VERSION "HNNBNNNYNNNNNNNNNNNNNNNNNNNNNNNNNNNNNNNNNN/4/%%%/4/'%**4NNN///"

NS_ :

BS_:

BU_: AAG BCM1 BCM2 ELV Gateway HDSG IEZS MFG MSBBR SAD SAD2 Schwerpanzer_Zusatz SitzMem_BFS SitzMem_FS SitzMem_HBFS SitzMem_HFS SitzMem_SR3 SpoilerSG TSG_BFS TSG_FS VSG VTS DK_Dummy

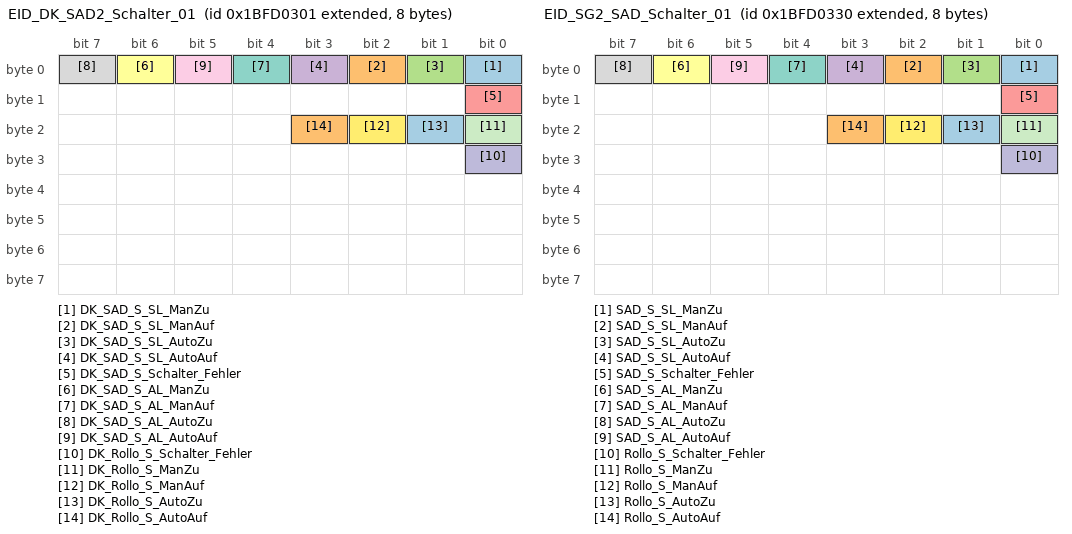
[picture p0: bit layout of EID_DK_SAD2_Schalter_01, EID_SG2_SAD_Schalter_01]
BO_ 2617049857 EID_DK_SAD2_Schalter_01: 8 DK_Dummy
 SG_ DK_SAD_S_SL_ManZu : 0|1@1+ (1,0) [0|1] ""  SAD2
 SG_ DK_SAD_S_SL_ManAuf : 2|1@1+ (1,0) [0|1] ""  SAD2
 SG_ DK_SAD_S_SL_AutoZu : 1|1@1+ (1,0) [0|1] ""  SAD2
 SG_ DK_SAD_S_SL_AutoAuf : 3|1@1+ (1,0) [0|1] ""  SAD2
 SG_ DK_SAD_S_Schalter_Fehler : 8|1@1+ (1,0) [0|1] ""  SAD2
 SG_ DK_SAD_S_AL_ManZu : 6|1@1+ (1,0) [0|1] ""  SAD2
 SG_ DK_SAD_S_AL_ManAuf : 4|1@1+ (1,0) [0|1] ""  SAD2
 SG_ DK_SAD_S_AL_AutoZu : 7|1@1+ (1,0) [0|1] ""  SAD2
 SG_ DK_SAD_S_AL_AutoAuf : 5|1@1+ (1,0) [0|1] ""  SAD2
 SG_ DK_Rollo_S_Schalter_Fehler : 24|1@1+ (1,0) [0|1] ""  SAD2
 SG_ DK_Rollo_S_ManZu : 16|1@1+ (1,0) [0|1] ""  SAD2
 SG_ DK_Rollo_S_ManAuf : 18|1@1+ (1,0) [0|1] ""  SAD2
 SG_ DK_Rollo_S_AutoZu : 17|1@1+ (1,0) [0|1] ""  SAD2
 SG_ DK_Rollo_S_AutoAuf : 19|1@1+ (1,0) [0|1] ""  SAD2

BO_ 2617049904 EID_SG2_SAD_Schalter_01: 8 SAD2
 SG_ SAD_S_SL_ManZu : 0|1@1+ (1,0) [0|1] "" Vector__XXX
 SG_ SAD_S_SL_ManAuf : 2|1@1+ (1,0) [0|1] "" Vector__XXX
 SG_ SAD_S_SL_AutoZu : 1|1@1+ (1,0) [0|1] "" Vector__XXX
 SG_ SAD_S_SL_AutoAuf : 3|1@1+ (1,0) [0|1] "" Vector__XXX
 SG_ SAD_S_Schalter_Fehler : 8|1@1+ (1,0) [0|1] "" Vector__XXX
 SG_ SAD_S_AL_ManZu : 6|1@1+ (1,0) [0|1] "" Vector__XXX
 SG_ SAD_S_AL_ManAuf : 4|1@1+ (1,0) [0|1] "" Vector__XXX
 SG_ SAD_S_AL_AutoZu : 7|1@1+ (1,0) [0|1] "" Vector__XXX
 SG_ SAD_S_AL_AutoAuf : 5|1@1+ (1,0) [0|1] "" Vector__XXX
 SG_ Rollo_S_Schalter_Fehler : 24|1@1+ (1,0) [0|1] "" Vector__XXX
 SG_ Rollo_S_ManZu : 16|1@1+ (1,0) [0|1] "" Vector__XXX
 SG_ Rollo_S_ManAuf : 18|1@1+ (1,0) [0|1] "" Vector__XXX
 SG_ Rollo_S_AutoZu : 17|1@1+ (1,0) [0|1] "" Vector__XXX
 SG_ Rollo_S_AutoAuf : 19|1@1+ (1,0) [0|1] "" Vector__XXX

BO_ 2617049906 EID_SG2_SAD_02: 8 SAD2
 SG_ Event_Logging : 0|64@1+ (1,0) [0|1.84467440737096E+019] "" Vector__XXX

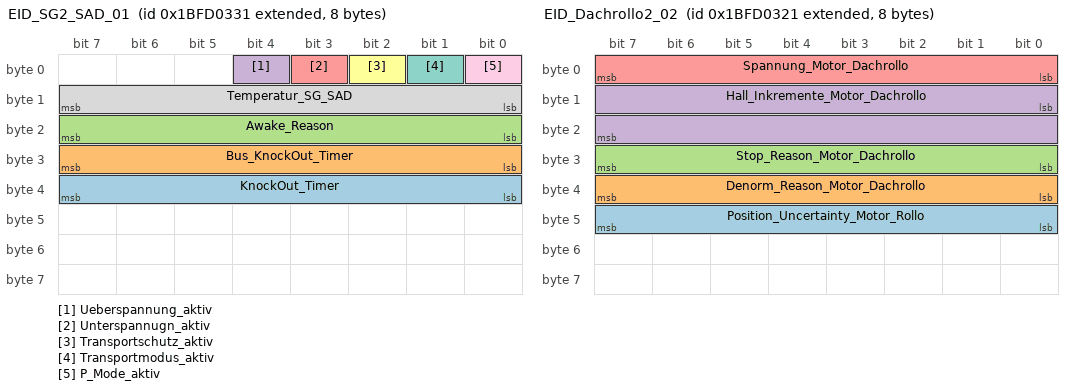
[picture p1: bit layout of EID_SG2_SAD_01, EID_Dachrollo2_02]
BO_ 2617049905 EID_SG2_SAD_01: 8 SAD2
 SG_ KnockOut_Timer : 32|8@1+ (1,0) [0|255] "Unit_Minut" Vector__XXX
 SG_ Bus_KnockOut_Timer : 24|8@1+ (1,0) [0|255] "Unit_Minut" Vector__XXX
 SG_ Awake_Reason : 16|8@1+ (1,0) [0|255] "" Vector__XXX
 SG_ Ueberspannung_aktiv : 4|1@1+ (1,0) [0|1] "" Vector__XXX
 SG_ Unterspannugn_aktiv : 3|1@1+ (1,0) [0|1] "" Vector__XXX
 SG_ Transportschutz_aktiv : 2|1@1+ (1,0) [0|1] "" Vector__XXX
 SG_ Transportmodus_aktiv : 1|1@1+ (1,0) [0|1] "" Vector__XXX
 SG_ Temperatur_SG_SAD : 8|8@1+ (1,0) [0|255] "Unit_DegreCelsi" Vector__XXX
 SG_ P_Mode_aktiv : 0|1@1+ (1,0) [0|1] "" Vector__XXX

BO_ 2617049889 EID_Dachrollo2_02: 8 SAD2
 SG_ Position_Uncertainty_Motor_Rollo : 40|8@1+ (1,0) [0|255] "" Vector__XXX
 SG_ Denorm_Reason_Motor_Dachrollo : 32|8@1+ (1,0) [0|255] "" Vector__XXX
 SG_ Stop_Reason_Motor_Dachrollo : 24|8@1+ (1,0) [0|255] "" Vector__XXX
 SG_ Hall_Inkremente_Motor_Dachrollo : 8|16@1+ (1,0) [0|65535] "" Vector__XXX
 SG_ Spannung_Motor_Dachrollo : 0|8@1+ (0.1,0) [0|25.5] "Unit_V" Vector__XXX

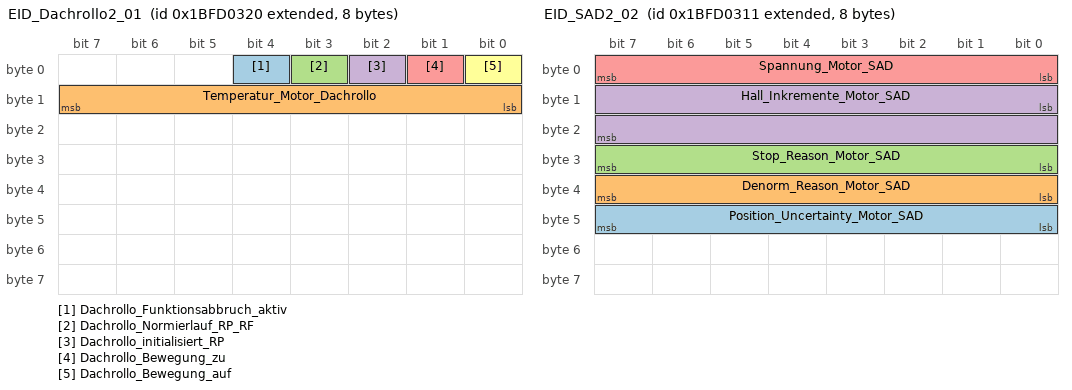
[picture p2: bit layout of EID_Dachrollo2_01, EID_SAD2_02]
BO_ 2617049888 EID_Dachrollo2_01: 8 SAD2
 SG_ Dachrollo_Funktionsabbruch_aktiv : 4|1@1+ (1,0) [0|1] "" Vector__XXX
 SG_ Temperatur_Motor_Dachrollo : 8|8@1+ (1,0) [0|255] "Unit_DegreCelsi" Vector__XXX
 SG_ Dachrollo_Normierlauf_RP_RF : 3|1@1+ (1,0) [0|1] "" Vector__XXX
 SG_ Dachrollo_initialisiert_RP : 2|1@1+ (1,0) [0|1] "" Vector__XXX
 SG_ Dachrollo_Bewegung_zu : 1|1@1+ (1,0) [0|1] "" Vector__XXX
 SG_ Dachrollo_Bewegung_auf : 0|1@1+ (1,0) [0|1] "" Vector__XXX

BO_ 2617049873 EID_SAD2_02: 8 SAD2
 SG_ Position_Uncertainty_Motor_SAD : 40|8@1+ (1,0) [0|255] "" Vector__XXX
 SG_ Denorm_Reason_Motor_SAD : 32|8@1+ (1,0) [0|255] "" Vector__XXX
 SG_ Stop_Reason_Motor_SAD : 24|8@1+ (1,0) [0|255] "" Vector__XXX
 SG_ Hall_Inkremente_Motor_SAD : 8|16@1+ (1,0) [0|65535] "" Vector__XXX
 SG_ Spannung_Motor_SAD : 0|8@1+ (0.1,0) [0|25.5] "Unit_V" Vector__XXX

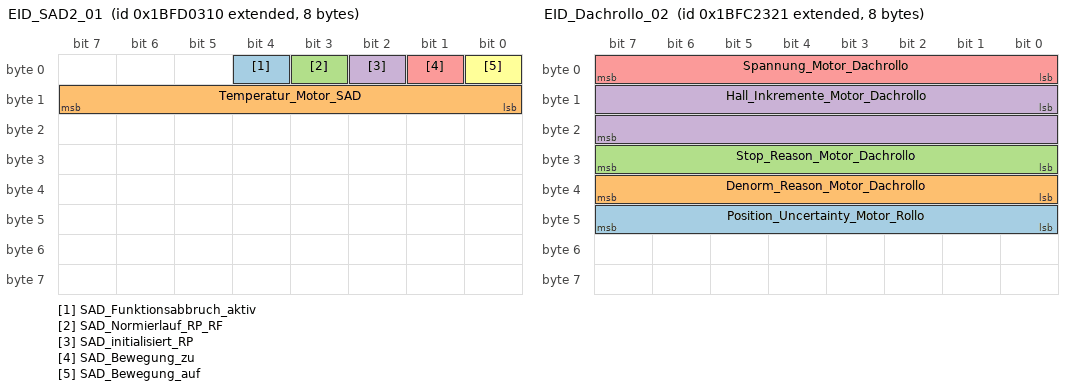
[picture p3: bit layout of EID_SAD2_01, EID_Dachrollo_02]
BO_ 2617049872 EID_SAD2_01: 8 SAD2
 SG_ SAD_Funktionsabbruch_aktiv : 4|1@1+ (1,0) [0|1] "" Vector__XXX
 SG_ Temperatur_Motor_SAD : 8|8@1+ (1,0) [0|255] "Unit_DegreCelsi" Vector__XXX
 SG_ SAD_Normierlauf_RP_RF : 3|1@1+ (1,0) [0|1] "" Vector__XXX
 SG_ SAD_initialisiert_RP : 2|1@1+ (1,0) [0|1] "" Vector__XXX
 SG_ SAD_Bewegung_zu : 1|1@1+ (1,0) [0|1] "" Vector__XXX
 SG_ SAD_Bewegung_auf : 0|1@1+ (1,0) [0|1] "" Vector__XXX

BO_ 2616992562 EID_SG_SAD_02: 8 SAD
 SG_ Event_Logging : 0|64@1+ (1,0) [0|1.84467440737096E+019] "" Vector__XXX

BO_ 2616992545 EID_Dachrollo_02: 8 SAD
 SG_ Position_Uncertainty_Motor_Rollo : 40|8@1+ (1,0) [0|255] "" Vector__XXX
 SG_ Denorm_Reason_Motor_Dachrollo : 32|8@1+ (1,0) [0|255] "" Vector__XXX
 SG_ Stop_Reason_Motor_Dachrollo : 24|8@1+ (1,0) [0|255] "" Vector__XXX
 SG_ Hall_Inkremente_Motor_Dachrollo : 8|16@1+ (1,0) [0|65535] "" Vector__XXX
 SG_ Spannung_Motor_Dachrollo : 0|8@1+ (0.1,0) [0|25.5] "Unit_V" Vector__XXX

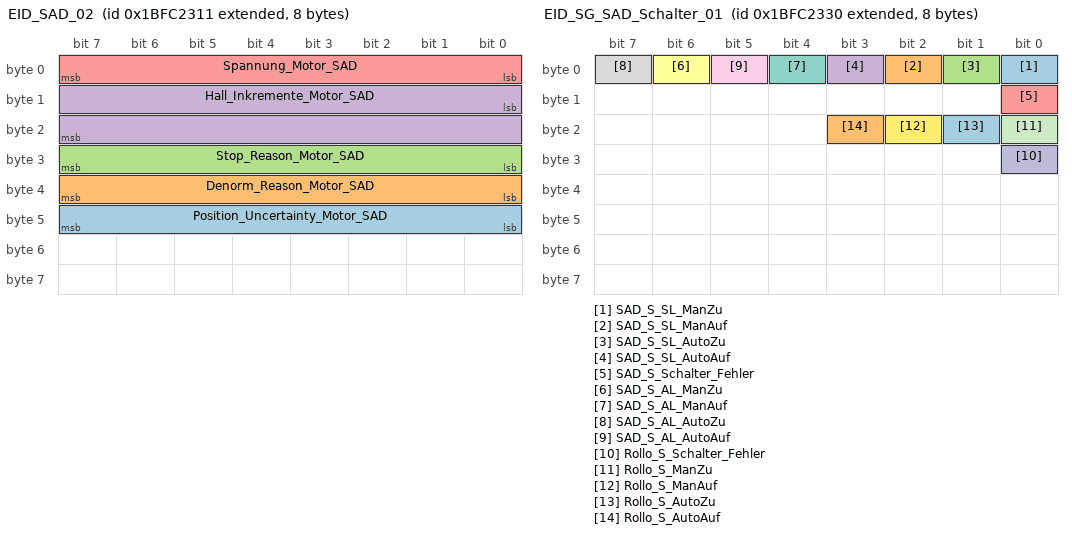
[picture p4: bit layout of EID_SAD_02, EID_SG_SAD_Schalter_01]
BO_ 2616992529 EID_SAD_02: 8 SAD
 SG_ Position_Uncertainty_Motor_SAD : 40|8@1+ (1,0) [0|255] "" Vector__XXX
 SG_ Denorm_Reason_Motor_SAD : 32|8@1+ (1,0) [0|255] "" Vector__XXX
 SG_ Stop_Reason_Motor_SAD : 24|8@1+ (1,0) [0|255] "" Vector__XXX
 SG_ Hall_Inkremente_Motor_SAD : 8|16@1+ (1,0) [0|65535] "" Vector__XXX
 SG_ Spannung_Motor_SAD : 0|8@1+ (0.1,0) [0|25.5] "Unit_V" Vector__XXX

BO_ 2616992560 EID_SG_SAD_Schalter_01: 8 SAD
 SG_ SAD_S_SL_ManZu : 0|1@1+ (1,0) [0|1] "" Vector__XXX
 SG_ SAD_S_SL_ManAuf : 2|1@1+ (1,0) [0|1] "" Vector__XXX
 SG_ SAD_S_SL_AutoZu : 1|1@1+ (1,0) [0|1] "" Vector__XXX
 SG_ SAD_S_SL_AutoAuf : 3|1@1+ (1,0) [0|1] "" Vector__XXX
 SG_ SAD_S_Schalter_Fehler : 8|1@1+ (1,0) [0|1] "" Vector__XXX
 SG_ SAD_S_AL_ManZu : 6|1@1+ (1,0) [0|1] "" Vector__XXX
 SG_ SAD_S_AL_ManAuf : 4|1@1+ (1,0) [0|1] "" Vector__XXX
 SG_ SAD_S_AL_AutoZu : 7|1@1+ (1,0) [0|1] "" Vector__XXX
 SG_ SAD_S_AL_AutoAuf : 5|1@1+ (1,0) [0|1] "" Vector__XXX
 SG_ Rollo_S_Schalter_Fehler : 24|1@1+ (1,0) [0|1] "" Vector__XXX
 SG_ Rollo_S_ManZu : 16|1@1+ (1,0) [0|1] "" Vector__XXX
 SG_ Rollo_S_ManAuf : 18|1@1+ (1,0) [0|1] "" Vector__XXX
 SG_ Rollo_S_AutoZu : 17|1@1+ (1,0) [0|1] "" Vector__XXX
 SG_ Rollo_S_AutoAuf : 19|1@1+ (1,0) [0|1] "" Vector__XXX

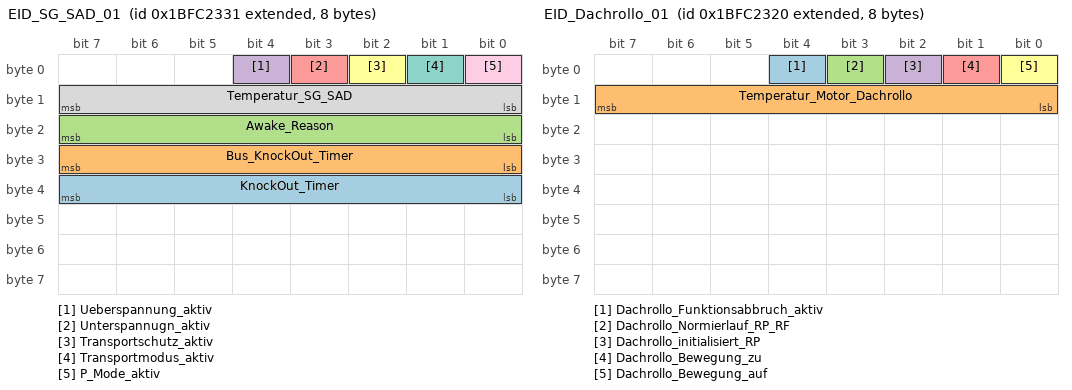
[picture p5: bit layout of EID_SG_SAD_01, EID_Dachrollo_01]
BO_ 2616992561 EID_SG_SAD_01: 8 SAD
 SG_ KnockOut_Timer : 32|8@1+ (1,0) [0|255] "Unit_Minut" Vector__XXX
 SG_ Bus_KnockOut_Timer : 24|8@1+ (1,0) [0|255] "Unit_Minut" Vector__XXX
 SG_ Awake_Reason : 16|8@1+ (1,0) [0|255] "" Vector__XXX
 SG_ Ueberspannung_aktiv : 4|1@1+ (1,0) [0|1] "" Vector__XXX
 SG_ Unterspannugn_aktiv : 3|1@1+ (1,0) [0|1] "" Vector__XXX
 SG_ Transportschutz_aktiv : 2|1@1+ (1,0) [0|1] "" Vector__XXX
 SG_ Transportmodus_aktiv : 1|1@1+ (1,0) [0|1] "" Vector__XXX
 SG_ Temperatur_SG_SAD : 8|8@1+ (1,0) [0|255] "Unit_DegreCelsi" Vector__XXX
 SG_ P_Mode_aktiv : 0|1@1+ (1,0) [0|1] "" Vector__XXX

BO_ 2616992544 EID_Dachrollo_01: 8 SAD
 SG_ Dachrollo_Funktionsabbruch_aktiv : 4|1@1+ (1,0) [0|1] "" Vector__XXX
 SG_ Temperatur_Motor_Dachrollo : 8|8@1+ (1,0) [0|255] "Unit_DegreCelsi" Vector__XXX
 SG_ Dachrollo_Normierlauf_RP_RF : 3|1@1+ (1,0) [0|1] "" Vector__XXX
 SG_ Dachrollo_initialisiert_RP : 2|1@1+ (1,0) [0|1] "" Vector__XXX
 SG_ Dachrollo_Bewegung_zu : 1|1@1+ (1,0) [0|1] "" Vector__XXX
 SG_ Dachrollo_Bewegung_auf : 0|1@1+ (1,0) [0|1] "" Vector__XXX

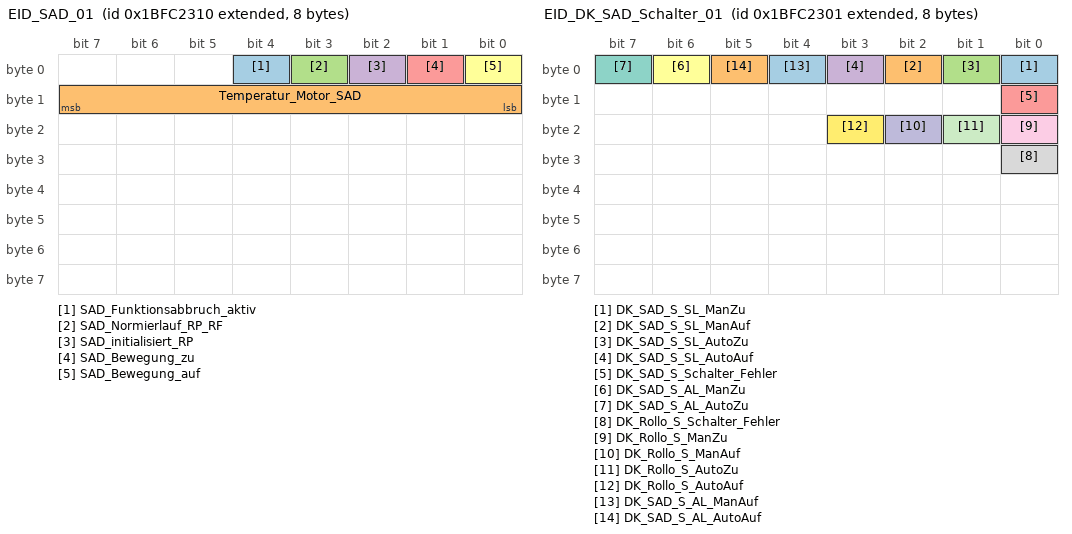
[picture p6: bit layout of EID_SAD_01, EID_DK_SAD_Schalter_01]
BO_ 2616992528 EID_SAD_01: 8 SAD
 SG_ SAD_Funktionsabbruch_aktiv : 4|1@1+ (1,0) [0|1] "" Vector__XXX
 SG_ Temperatur_Motor_SAD : 8|8@1+ (1,0) [0|255] "Unit_DegreCelsi" Vector__XXX
 SG_ SAD_Normierlauf_RP_RF : 3|1@1+ (1,0) [0|1] "" Vector__XXX
 SG_ SAD_initialisiert_RP : 2|1@1+ (1,0) [0|1] "" Vector__XXX
 SG_ SAD_Bewegung_zu : 1|1@1+ (1,0) [0|1] "" Vector__XXX
 SG_ SAD_Bewegung_auf : 0|1@1+ (1,0) [0|1] "" Vector__XXX

BO_ 2616992513 EID_DK_SAD_Schalter_01: 8 DK_Dummy
 SG_ DK_SAD_S_SL_ManZu : 0|1@1+ (1,0) [0|1] ""  SAD
 SG_ DK_SAD_S_SL_ManAuf : 2|1@1+ (1,0) [0|1] ""  SAD
 SG_ DK_SAD_S_SL_AutoZu : 1|1@1+ (1,0) [0|1] ""  SAD
 SG_ DK_SAD_S_SL_AutoAuf : 3|1@1+ (1,0) [0|1] ""  SAD
 SG_ DK_SAD_S_Schalter_Fehler : 8|1@1+ (1,0) [0|1] ""  SAD
 SG_ DK_SAD_S_AL_ManZu : 6|1@1+ (1,0) [0|1] ""  SAD
 SG_ DK_SAD_S_AL_AutoZu : 7|1@1+ (1,0) [0|1] ""  SAD
 SG_ DK_Rollo_S_Schalter_Fehler : 24|1@1+ (1,0) [0|1] ""  SAD
 SG_ DK_Rollo_S_ManZu : 16|1@1+ (1,0) [0|1] ""  SAD
 SG_ DK_Rollo_S_ManAuf : 18|1@1+ (1,0) [0|1] ""  SAD
 SG_ DK_Rollo_S_AutoZu : 17|1@1+ (1,0) [0|1] ""  SAD
 SG_ DK_Rollo_S_AutoAuf : 19|1@1+ (1,0) [0|1] ""  SAD
 SG_ DK_SAD_S_AL_ManAuf : 4|1@1+ (1,0) [0|1] ""  SAD
 SG_ DK_SAD_S_AL_AutoAuf : 5|1@1+ (1,0) [0|1] ""  SAD

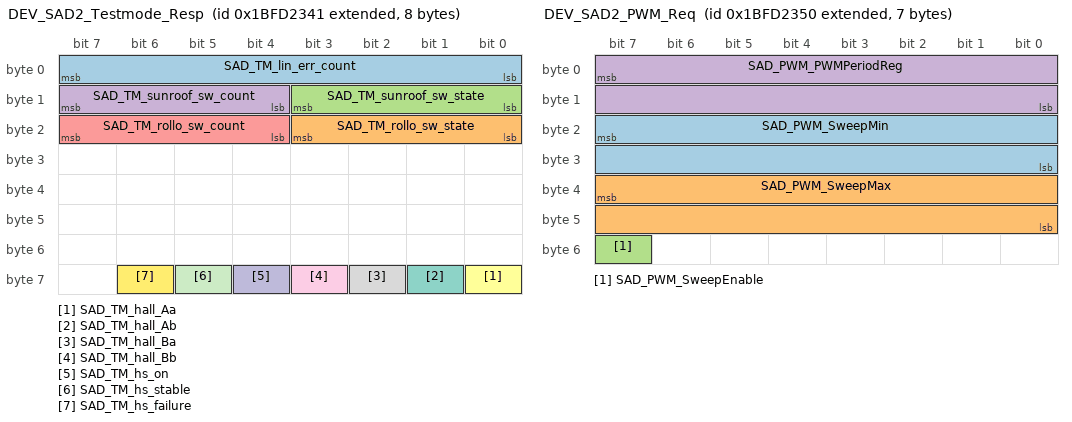
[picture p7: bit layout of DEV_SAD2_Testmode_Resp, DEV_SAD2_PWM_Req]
BO_ 2617058113 DEV_SAD2_Testmode_Resp: 8 SAD2
 SG_ SAD_TM_lin_err_count : 0|8@1+ (1,0) [0|0] ""  DK_Dummy
 SG_ SAD_TM_rollo_sw_state : 16|4@1+ (1,0) [0|0] ""  DK_Dummy
 SG_ SAD_TM_sunroof_sw_state : 8|4@1+ (1,0) [0|0] ""  DK_Dummy
 SG_ SAD_TM_sunroof_sw_count : 12|4@1+ (1,0) [0|0] ""  DK_Dummy
 SG_ SAD_TM_rollo_sw_count : 20|4@1+ (1,0) [0|0] ""  DK_Dummy
 SG_ SAD_TM_hall_Aa : 56|1@1+ (1,0) [0|0] ""  DK_Dummy
 SG_ SAD_TM_hall_Ab : 57|1@1+ (1,0) [0|0] ""  DK_Dummy
 SG_ SAD_TM_hall_Ba : 58|1@1+ (1,0) [0|0] ""  DK_Dummy
 SG_ SAD_TM_hall_Bb : 59|1@1+ (1,0) [0|0] ""  DK_Dummy
 SG_ SAD_TM_hs_on : 60|1@1+ (1,0) [0|0] ""  DK_Dummy
 SG_ SAD_TM_hs_stable : 61|1@1+ (1,0) [0|0] ""  DK_Dummy
 SG_ SAD_TM_hs_failure : 62|1@1+ (1,0) [0|0] ""  DK_Dummy

BO_ 2617058112 DEV_SAD2_Testmode_Req: 6 DK_Dummy
 SG_ SAD_TM_sunroof_sw_expected : 40|4@1+ (1,0) [0|0] ""  SAD2
 SG_ SAD_TM_rollo_sw_expected : 44|4@1+ (1,0) [0|0] ""  SAD2
 SG_ SAD_TM_l99h01_en : 7|1@1+ (1,0) [0|0] ""  SAD2
 SG_ SAD_TM_Mode : 0|2@1+ (1,0) [0|0] ""  SAD2
 SG_ SAD_TM_lin_en : 2|1@1+ (1,0) [0|0] ""  SAD2
 SG_ SAD_TM_swil_en : 3|1@1+ (1,0) [0|0] ""  SAD2
 SG_ SAD_TM_hs_en : 4|1@1+ (1,0) [0|0] ""  SAD2
 SG_ SAD_TM_lpwm_en : 5|1@1+ (1,0) [0|0] ""  SAD2
 SG_ SAD_TM_sws_en : 6|1@1+ (1,0) [0|0] ""  SAD2
 SG_ SAD_TM_sws : 15|1@1+ (1,0) [0|0] ""  SAD2
 SG_ SAD_TM_clr_lin : 10|1@1+ (1,0) [0|0] ""  SAD2
 SG_ SAD_TM_clr_swil_fdbk : 11|1@1+ (1,0) [0|0] ""  SAD2
 SG_ SAD_TM_clr_hs_fdbk : 12|1@1+ (1,0) [0|0] ""  SAD2
 SG_ SAD_TM_clr_lpwm_fdbk : 13|1@1+ (1,0) [0|0] ""  SAD2
 SG_ SAD_TM_clr_sw_fdbk : 14|1@1+ (1,0) [0|0] ""  SAD2
 SG_ SAD_TM_switch_illum : 16|7@1+ (1,0) [0|0] ""  SAD2
 SG_ SAD_TM_hall_supply : 24|7@1+ (1,0) [0|0] ""  SAD2
 SG_ SAD_TM_led_pwm : 32|7@1+ (1,0) [0|0] ""  SAD2

BO_ 2617058128 DEV_SAD2_PWM_Req: 7 DK_Dummy
 SG_ SAD_PWM_SweepMin : 23|16@0+ (1,0) [1|30000] "Hz"  SAD2
 SG_ SAD_PWM_SweepMax : 39|16@0+ (1,0) [1|30000] "Hz"  SAD2
 SG_ SAD_PWM_SweepEnable : 55|1@1+ (1,0) [0|0] ""  SAD2
 SG_ SAD_PWM_PWMPeriodReg : 7|16@0+ (1,0) [1|65535] ""  SAD2

BO_ 2617058161 DEV_SAD2_L99H01_B_Resp: 6 SAD2
 SG_ SAD_L99H01_B_WDTO : 0|1@1+ (1,0) [0|1] ""  DK_Dummy
 SG_ SAD_L99H01_B_UV : 2|1@1+ (1,0) [0|1] ""  DK_Dummy
 SG_ SAD_L99H01_B_TW : 3|1@1+ (1,0) [0|1] ""  DK_Dummy
 SG_ SAD_L99H01_B_TSD : 4|1@1+ (1,0) [0|1] ""  DK_Dummy
 SG_ SAD_L99H01_B_STK_RESET_Q : 5|1@1+ (1,0) [0|1] ""  DK_Dummy
 SG_ SAD_L99H01_B_rOT_EXT : 9|1@1+ (1,0) [0|1] ""  DK_Dummy
 SG_ SAD_L99H01_B_rDS_MON_3 : 15|1@1+ (1,0) [0|1] ""  DK_Dummy
 SG_ SAD_L99H01_B_rDS_MON_2 : 14|1@1+ (1,0) [0|1] ""  DK_Dummy
 SG_ SAD_L99H01_B_rDS_MON_1 : 13|1@1+ (1,0) [0|1] ""  DK_Dummy
 SG_ SAD_L99H01_B_rDS_MON_0 : 12|1@1+ (1,0) [0|1] ""  DK_Dummy
 SG_ SAD_L99H01_B_rCP_LOW : 8|1@1+ (1,0) [0|1] ""  DK_Dummy
 SG_ SAD_L99H01_B_OV : 1|1@1+ (1,0) [0|1] ""  DK_Dummy
 SG_ SAD_L99H01_B_GL_ER : 7|1@1+ (1,0) [0|1] ""  DK_Dummy
 SG_ SAD_L99H01_B_FE : 6|1@1+ (1,0) [0|1] ""  DK_Dummy
 SG_ SAD_L99H01_B_Error : 16|4@1+ (1,0) [0|0] ""  DK_Dummy
 SG_ SAD_L99H01_B_State : 20|4@1+ (1,0) [0|0] ""  DK_Dummy
 SG_ SAD_L99H01_B_SC2GND : 24|8@1+ (1,0) [0|0] ""  DK_Dummy
 SG_ SAD_L99H01_B_SC2BAT_LS : 32|8@1+ (1,0) [0|0] ""  DK_Dummy
 SG_ SAD_L99H01_B_SC2BAT_HS : 40|8@1+ (1,0) [0|0] ""  DK_Dummy

BO_ 2617058160 DEV_SAD2_L99H01_B_Req: 5 DK_Dummy
 SG_ SAD_L99H01_B_EnableFdbkMon : 12|1@1+ (1,0) [0|0] ""  SAD2
 SG_ SAD_L99H01_B_DirSwitchTime : 8|4@1+ (5,0) [0|75] "ms"  SAD2
 SG_ SAD_L99H01_B_OVT : 19|1@1+ (1,0) [0|1] ""  SAD2
 SG_ SAD_L99H01_B_OV_UV_RD : 18|1@1+ (1,0) [0|1] ""  SAD2
 SG_ SAD_L99H01_B_OFF_CAL : 21|1@1+ (1,0) [0|1] ""  SAD2
 SG_ SAD_L99H01_B_FW_PAS : 22|1@1+ (1,0) [0|1] ""  SAD2
 SG_ SAD_L99H01_B_FW : 27|1@1+ (1,0) [0|1] ""  SAD2
 SG_ SAD_L99H01_B_EXT_TS : 38|1@1+ (1,0) [0|1] ""  SAD2
 SG_ SAD_L99H01_B_ENABLE : 13|1@1+ (1,0) [0|1] ""  SAD2
 SG_ SAD_L99H01_B_DIR : 14|1@1+ (1,0) [0|1] ""  SAD2
 SG_ SAD_L99H01_B_CLR_STAT : 15|1@1+ (1,0) [0|1] ""  SAD2
 SG_ SAD_L99H01_B_CLK_SPCTR : 20|1@1+ (1,0) [0|1] ""  SAD2
 SG_ SAD_L99H01_B_EXTTH_n : 35|3@1+ (1,0) [0|7] ""  SAD2
 SG_ SAD_L99H01_B_DIAG : 16|2@1+ (1,0) [0|3] ""  SAD2
 SG_ SAD_L99H01_B_EXTTH_m : 32|3@1+ (1,0) [0|7] ""  SAD2
 SG_ SAD_L99H01_B_COPT : 28|3@1+ (1,0) [0|7] ""  SAD2
 SG_ SAD_L99H01_B_PWM : 0|8@1+ (1,0) [0|255] "%"  SAD2

BO_ 2617058145 DEV_SAD2_L99H01_A_Resp: 6 SAD2
 SG_ SAD_L99H01_A_WDTO : 0|1@1+ (1,0) [0|1] ""  DK_Dummy
 SG_ SAD_L99H01_A_UV : 2|1@1+ (1,0) [0|1] ""  DK_Dummy
 SG_ SAD_L99H01_A_TW : 3|1@1+ (1,0) [0|1] ""  DK_Dummy
 SG_ SAD_L99H01_A_TSD : 4|1@1+ (1,0) [0|1] ""  DK_Dummy
 SG_ SAD_L99H01_A_STK_RESET_Q : 5|1@1+ (1,0) [0|1] ""  DK_Dummy
 SG_ SAD_L99H01_A_rOT_EXT : 9|1@1+ (1,0) [0|1] ""  DK_Dummy
 SG_ SAD_L99H01_A_rDS_MON_3 : 15|1@1+ (1,0) [0|1] ""  DK_Dummy
 SG_ SAD_L99H01_A_rDS_MON_2 : 14|1@1+ (1,0) [0|1] ""  DK_Dummy
 SG_ SAD_L99H01_A_rDS_MON_1 : 13|1@1+ (1,0) [0|1] ""  DK_Dummy
 SG_ SAD_L99H01_A_rDS_MON_0 : 12|1@1+ (1,0) [0|1] ""  DK_Dummy
 SG_ SAD_L99H01_A_rCP_LOW : 8|1@1+ (1,0) [0|1] ""  DK_Dummy
 SG_ SAD_L99H01_A_OV : 1|1@1+ (1,0) [0|1] ""  DK_Dummy
 SG_ SAD_L99H01_A_GL_ER : 7|1@1+ (1,0) [0|1] ""  DK_Dummy
 SG_ SAD_L99H01_A_FE : 6|1@1+ (1,0) [0|1] ""  DK_Dummy
 SG_ SAD_L99H01_A_Error : 16|4@1+ (1,0) [0|0] ""  DK_Dummy
 SG_ SAD_L99H01_A_State : 20|4@1+ (1,0) [0|0] ""  DK_Dummy
 SG_ SAD_L99H01_A_SC2GND : 24|8@1+ (1,0) [0|0] ""  DK_Dummy
 SG_ SAD_L99H01_A_SC2BAT_LS : 32|8@1+ (1,0) [0|0] ""  DK_Dummy
 SG_ SAD_L99H01_A_SC2BAT_HS : 40|8@1+ (1,0) [0|0] ""  DK_Dummy

BO_ 2617058144 DEV_SAD2_L99H01_A_Req: 5 DK_Dummy
 SG_ SAD_L99H01_A_EnableFdbkMon : 12|1@1+ (1,0) [0|0] ""  SAD2
 SG_ SAD_L99H01_A_DirSwitchTime : 8|4@1+ (5,0) [0|75] "ms"  SAD2
 SG_ SAD_L99H01_A_OVT : 19|1@1+ (1,0) [0|1] ""  SAD2
 SG_ SAD_L99H01_A_OV_UV_RD : 18|1@1+ (1,0) [0|1] ""  SAD2
 SG_ SAD_L99H01_A_OFF_CAL : 21|1@1+ (1,0) [0|1] ""  SAD2
 SG_ SAD_L99H01_A_FW_PAS : 22|1@1+ (1,0) [0|1] ""  SAD2
 SG_ SAD_L99H01_A_FW : 27|1@1+ (1,0) [0|1] ""  SAD2
 SG_ SAD_L99H01_A_EXT_TS : 38|1@1+ (1,0) [0|1] ""  SAD2
 SG_ SAD_L99H01_A_ENABLE : 13|1@1+ (1,0) [0|1] ""  SAD2
 SG_ SAD_L99H01_A_DIR : 14|1@1+ (1,0) [0|1] ""  SAD2
 SG_ SAD_L99H01_A_CLR_STAT : 15|1@1+ (1,0) [0|1] ""  SAD2
 SG_ SAD_L99H01_A_CLK_SPCTR : 20|1@1+ (1,0) [0|1] ""  SAD2
 SG_ SAD_L99H01_A_EXTTH_n : 35|3@1+ (1,0) [0|7] ""  SAD2
 SG_ SAD_L99H01_A_DIAG : 16|2@1+ (1,0) [0|3] ""  SAD2
 SG_ SAD_L99H01_A_EXTTH_m : 32|3@1+ (1,0) [0|7] ""  SAD2
 SG_ SAD_L99H01_A_COPT : 28|3@1+ (1,0) [0|7] ""  SAD2
 SG_ SAD_L99H01_A_PWM : 0|8@1+ (1,0) [0|255] "%"  SAD2

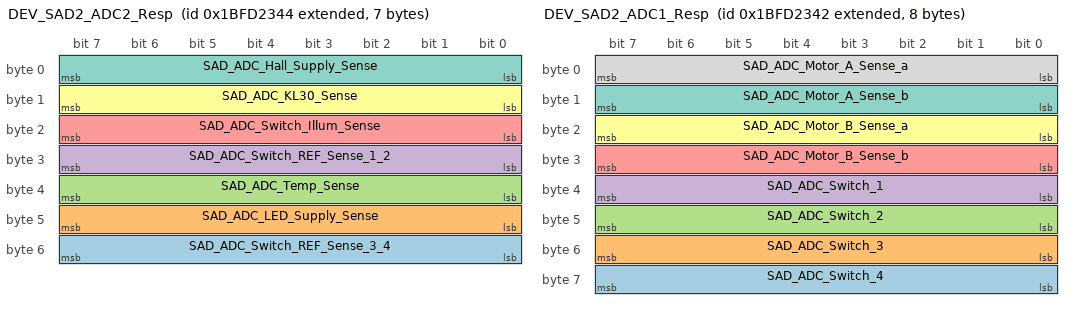
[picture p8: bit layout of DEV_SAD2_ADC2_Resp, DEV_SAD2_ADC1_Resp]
BO_ 2617058116 DEV_SAD2_ADC2_Resp: 7 SAD2
 SG_ SAD_ADC_Switch_REF_Sense_3_4 : 48|8@1+ (0.108309659,0) [0|0] "V"  DK_Dummy
 SG_ SAD_ADC_LED_Supply_Sense : 40|8@1+ (0.108309659,0) [0|0] "V"  DK_Dummy
 SG_ SAD_ADC_Temp_Sense : 32|8@1+ (1,0) [0|0] ""  DK_Dummy
 SG_ SAD_ADC_Switch_REF_Sense_1_2 : 24|8@1+ (0.108309659,0) [0|0] "V"  DK_Dummy
 SG_ SAD_ADC_Switch_Illum_Sense : 16|8@1+ (0.108309659,0) [0|0] "V"  DK_Dummy
 SG_ SAD_ADC_KL30_Sense : 8|8@1+ (0.091869212,0) [0|23.42664906] "V"  DK_Dummy
 SG_ SAD_ADC_Hall_Supply_Sense : 0|8@1+ (0.108309659,0) [0|0] "V"  DK_Dummy

BO_ 2617058114 DEV_SAD2_ADC1_Resp: 8 SAD2
 SG_ SAD_ADC_Switch_4 : 56|8@1+ (1,0) [0|0] ""  DK_Dummy
 SG_ SAD_ADC_Switch_3 : 48|8@1+ (1,0) [0|0] ""  DK_Dummy
 SG_ SAD_ADC_Switch_2 : 40|8@1+ (1,0) [0|0] ""  DK_Dummy
 SG_ SAD_ADC_Switch_1 : 32|8@1+ (1,0) [0|0] ""  DK_Dummy
 SG_ SAD_ADC_Motor_B_Sense_b : 24|8@1+ (0.091869212,0) [0|23.42664906] "V"  DK_Dummy
 SG_ SAD_ADC_Motor_B_Sense_a : 16|8@1+ (0.091869212,0) [0|23.42664906] "V"  DK_Dummy
 SG_ SAD_ADC_Motor_A_Sense_b : 8|8@1+ (0.091869212,0) [0|23.42664906] "V"  DK_Dummy
 SG_ SAD_ADC_Motor_A_Sense_a : 0|8@1+ (0.091869212,0) [0|23.42664906] "V"  DK_Dummy

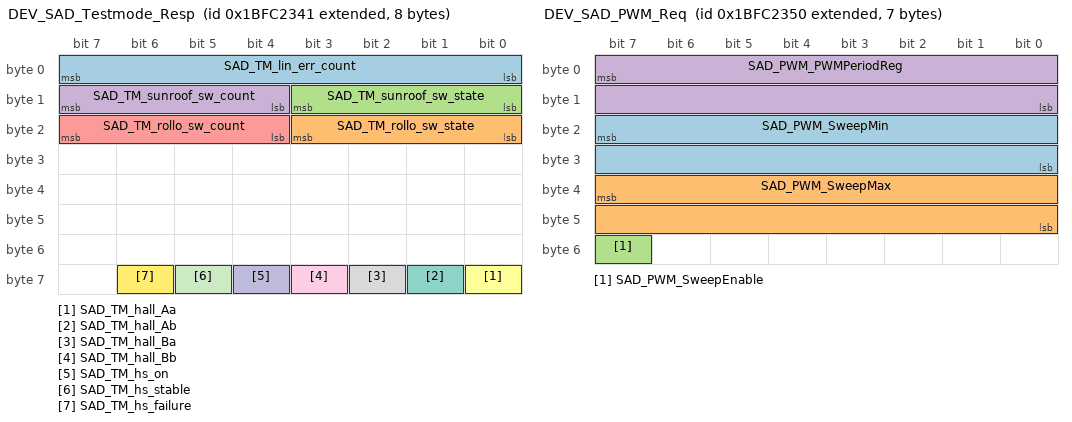
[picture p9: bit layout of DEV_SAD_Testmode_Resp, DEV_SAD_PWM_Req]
BO_ 2616992577 DEV_SAD_Testmode_Resp: 8 SAD
 SG_ SAD_TM_lin_err_count : 0|8@1+ (1,0) [0|0] ""  DK_Dummy
 SG_ SAD_TM_rollo_sw_state : 16|4@1+ (1,0) [0|0] ""  DK_Dummy
 SG_ SAD_TM_sunroof_sw_state : 8|4@1+ (1,0) [0|0] ""  DK_Dummy
 SG_ SAD_TM_sunroof_sw_count : 12|4@1+ (1,0) [0|0] ""  DK_Dummy
 SG_ SAD_TM_rollo_sw_count : 20|4@1+ (1,0) [0|0] ""  DK_Dummy
 SG_ SAD_TM_hall_Aa : 56|1@1+ (1,0) [0|0] ""  DK_Dummy
 SG_ SAD_TM_hall_Ab : 57|1@1+ (1,0) [0|0] ""  DK_Dummy
 SG_ SAD_TM_hall_Ba : 58|1@1+ (1,0) [0|0] ""  DK_Dummy
 SG_ SAD_TM_hall_Bb : 59|1@1+ (1,0) [0|0] ""  DK_Dummy
 SG_ SAD_TM_hs_on : 60|1@1+ (1,0) [0|0] ""  DK_Dummy
 SG_ SAD_TM_hs_stable : 61|1@1+ (1,0) [0|0] ""  DK_Dummy
 SG_ SAD_TM_hs_failure : 62|1@1+ (1,0) [0|0] ""  DK_Dummy

BO_ 2616992592 DEV_SAD_PWM_Req: 7 DK_Dummy
 SG_ SAD_PWM_SweepMin : 23|16@0+ (1,0) [1|30000] "Hz"  SAD
 SG_ SAD_PWM_SweepMax : 39|16@0+ (1,0) [1|30000] "Hz"  SAD
 SG_ SAD_PWM_SweepEnable : 55|1@1+ (1,0) [0|0] ""  SAD
 SG_ SAD_PWM_PWMPeriodReg : 7|16@0+ (1,0) [1|65535] ""  SAD

BO_ 2616992576 DEV_SAD_Testmode_Req: 6 DK_Dummy
 SG_ SAD_TM_sunroof_sw_expected : 40|4@1+ (1,0) [0|0] ""  SAD
 SG_ SAD_TM_rollo_sw_expected : 44|4@1+ (1,0) [0|0] ""  SAD
 SG_ SAD_TM_l99h01_en : 7|1@1+ (1,0) [0|0] ""  SAD
 SG_ SAD_TM_Mode : 0|2@1+ (1,0) [0|0] ""  SAD
 SG_ SAD_TM_lin_en : 2|1@1+ (1,0) [0|0] ""  SAD
 SG_ SAD_TM_swil_en : 3|1@1+ (1,0) [0|0] ""  SAD
 SG_ SAD_TM_hs_en : 4|1@1+ (1,0) [0|0] ""  SAD
 SG_ SAD_TM_lpwm_en : 5|1@1+ (1,0) [0|0] ""  SAD
 SG_ SAD_TM_sws_en : 6|1@1+ (1,0) [0|0] ""  SAD
 SG_ SAD_TM_sws : 15|1@1+ (1,0) [0|0] ""  SAD
 SG_ SAD_TM_clr_lin : 10|1@1+ (1,0) [0|0] ""  SAD
 SG_ SAD_TM_clr_swil_fdbk : 11|1@1+ (1,0) [0|0] ""  SAD
 SG_ SAD_TM_clr_hs_fdbk : 12|1@1+ (1,0) [0|0] ""  SAD
 SG_ SAD_TM_clr_lpwm_fdbk : 13|1@1+ (1,0) [0|0] ""  SAD
 SG_ SAD_TM_clr_sw_fdbk : 14|1@1+ (1,0) [0|0] ""  SAD
 SG_ SAD_TM_switch_illum : 16|7@1+ (1,0) [0|0] ""  SAD
 SG_ SAD_TM_hall_supply : 24|7@1+ (1,0) [0|0] ""  SAD
 SG_ SAD_TM_led_pwm : 32|7@1+ (1,0) [0|0] ""  SAD

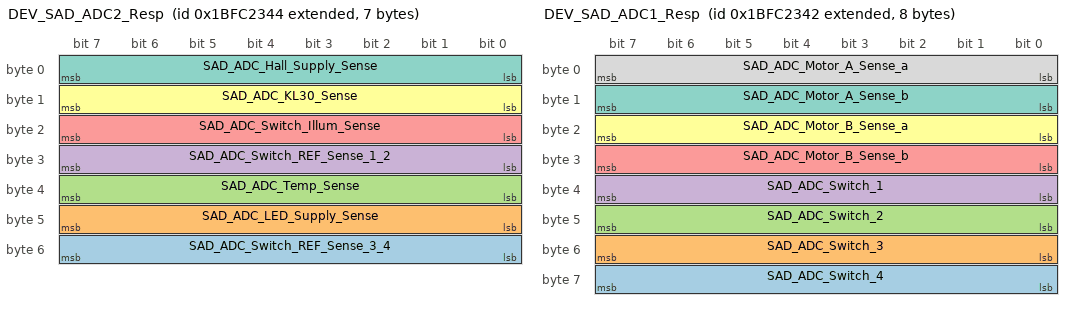
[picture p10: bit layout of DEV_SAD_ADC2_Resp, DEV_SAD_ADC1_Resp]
BO_ 2616992580 DEV_SAD_ADC2_Resp: 7 SAD
 SG_ SAD_ADC_Switch_REF_Sense_3_4 : 48|8@1+ (0.108309659,0) [0|0] "V"  DK_Dummy
 SG_ SAD_ADC_LED_Supply_Sense : 40|8@1+ (0.108309659,0) [0|0] "V"  DK_Dummy
 SG_ SAD_ADC_Temp_Sense : 32|8@1+ (1,0) [0|0] ""  DK_Dummy
 SG_ SAD_ADC_Switch_REF_Sense_1_2 : 24|8@1+ (0.108309659,0) [0|0] "V"  DK_Dummy
 SG_ SAD_ADC_Switch_Illum_Sense : 16|8@1+ (0.108309659,0) [0|0] "V"  DK_Dummy
 SG_ SAD_ADC_KL30_Sense : 8|8@1+ (0.091869212,0) [0|23.42664906] "V"  DK_Dummy
 SG_ SAD_ADC_Hall_Supply_Sense : 0|8@1+ (0.108309659,0) [0|0] "V"  DK_Dummy

BO_ 2616992578 DEV_SAD_ADC1_Resp: 8 SAD
 SG_ SAD_ADC_Switch_4 : 56|8@1+ (1,0) [0|0] ""  DK_Dummy
 SG_ SAD_ADC_Switch_3 : 48|8@1+ (1,0) [0|0] ""  DK_Dummy
 SG_ SAD_ADC_Switch_2 : 40|8@1+ (1,0) [0|0] ""  DK_Dummy
 SG_ SAD_ADC_Switch_1 : 32|8@1+ (1,0) [0|0] ""  DK_Dummy
 SG_ SAD_ADC_Motor_B_Sense_b : 24|8@1+ (0.091869212,0) [0|23.42664906] "V"  DK_Dummy
 SG_ SAD_ADC_Motor_B_Sense_a : 16|8@1+ (0.091869212,0) [0|23.42664906] "V"  DK_Dummy
 SG_ SAD_ADC_Motor_A_Sense_b : 8|8@1+ (0.091869212,0) [0|23.42664906] "V"  DK_Dummy
 SG_ SAD_ADC_Motor_A_Sense_a : 0|8@1+ (0.091869212,0) [0|23.42664906] "V"  DK_Dummy

BO_ 2616992624 DEV_SAD_L99H01_B_Req: 5 DK_Dummy
 SG_ SAD_L99H01_B_EnableFdbkMon : 12|1@1+ (1,0) [0|0] ""  SAD
 SG_ SAD_L99H01_B_DirSwitchTime : 8|4@1+ (5,0) [0|75] "ms"  SAD
 SG_ SAD_L99H01_B_OVT : 19|1@1+ (1,0) [0|1] ""  SAD
 SG_ SAD_L99H01_B_OV_UV_RD : 18|1@1+ (1,0) [0|1] ""  SAD
 SG_ SAD_L99H01_B_OFF_CAL : 21|1@1+ (1,0) [0|1] ""  SAD
 SG_ SAD_L99H01_B_FW_PAS : 22|1@1+ (1,0) [0|1] ""  SAD
 SG_ SAD_L99H01_B_FW : 27|1@1+ (1,0) [0|1] ""  SAD
 SG_ SAD_L99H01_B_EXT_TS : 38|1@1+ (1,0) [0|1] ""  SAD
 SG_ SAD_L99H01_B_ENABLE : 13|1@1+ (1,0) [0|1] ""  SAD
 SG_ SAD_L99H01_B_DIR : 14|1@1+ (1,0) [0|1] ""  SAD
 SG_ SAD_L99H01_B_CLR_STAT : 15|1@1+ (1,0) [0|1] ""  SAD
 SG_ SAD_L99H01_B_CLK_SPCTR : 20|1@1+ (1,0) [0|1] ""  SAD
 SG_ SAD_L99H01_B_EXTTH_n : 35|3@1+ (1,0) [0|7] ""  SAD
 SG_ SAD_L99H01_B_DIAG : 16|2@1+ (1,0) [0|3] ""  SAD
 SG_ SAD_L99H01_B_EXTTH_m : 32|3@1+ (1,0) [0|7] ""  SAD
 SG_ SAD_L99H01_B_COPT : 28|3@1+ (1,0) [0|7] ""  SAD
 SG_ SAD_L99H01_B_PWM : 0|8@1+ (1,0) [0|255] "%"  SAD

BO_ 2616992608 DEV_SAD_L99H01_A_Req: 5 DK_Dummy
 SG_ SAD_L99H01_A_EnableFdbkMon : 12|1@1+ (1,0) [0|0] ""  SAD
 SG_ SAD_L99H01_A_DirSwitchTime : 8|4@1+ (5,0) [0|75] "ms"  SAD
 SG_ SAD_L99H01_A_OVT : 19|1@1+ (1,0) [0|1] ""  SAD
 SG_ SAD_L99H01_A_OV_UV_RD : 18|1@1+ (1,0) [0|1] ""  SAD
 SG_ SAD_L99H01_A_OFF_CAL : 21|1@1+ (1,0) [0|1] ""  SAD
 SG_ SAD_L99H01_A_FW_PAS : 22|1@1+ (1,0) [0|1] ""  SAD
 SG_ SAD_L99H01_A_FW : 27|1@1+ (1,0) [0|1] ""  SAD
 SG_ SAD_L99H01_A_EXT_TS : 38|1@1+ (1,0) [0|1] ""  SAD
 SG_ SAD_L99H01_A_ENABLE : 13|1@1+ (1,0) [0|1] ""  SAD
 SG_ SAD_L99H01_A_DIR : 14|1@1+ (1,0) [0|1] ""  SAD
 SG_ SAD_L99H01_A_CLR_STAT : 15|1@1+ (1,0) [0|1] ""  SAD
 SG_ SAD_L99H01_A_CLK_SPCTR : 20|1@1+ (1,0) [0|1] ""  SAD
 SG_ SAD_L99H01_A_EXTTH_n : 35|3@1+ (1,0) [0|7] ""  SAD
 SG_ SAD_L99H01_A_DIAG : 16|2@1+ (1,0) [0|3] ""  SAD
 SG_ SAD_L99H01_A_EXTTH_m : 32|3@1+ (1,0) [0|7] ""  SAD
 SG_ SAD_L99H01_A_COPT : 28|3@1+ (1,0) [0|7] ""  SAD
 SG_ SAD_L99H01_A_PWM : 0|8@1+ (1,0) [0|255] "%"  SAD

BO_ 2616992625 DEV_SAD_L99H01_B_Resp: 6 SAD
 SG_ SAD_L99H01_B_WDTO : 0|1@1+ (1,0) [0|1] ""  DK_Dummy
 SG_ SAD_L99H01_B_UV : 2|1@1+ (1,0) [0|1] ""  DK_Dummy
 SG_ SAD_L99H01_B_TW : 3|1@1+ (1,0) [0|1] ""  DK_Dummy
 SG_ SAD_L99H01_B_TSD : 4|1@1+ (1,0) [0|1] ""  DK_Dummy
 SG_ SAD_L99H01_B_STK_RESET_Q : 5|1@1+ (1,0) [0|1] ""  DK_Dummy
 SG_ SAD_L99H01_B_rOT_EXT : 9|1@1+ (1,0) [0|1] ""  DK_Dummy
 SG_ SAD_L99H01_B_rDS_MON_3 : 15|1@1+ (1,0) [0|1] ""  DK_Dummy
 SG_ SAD_L99H01_B_rDS_MON_2 : 14|1@1+ (1,0) [0|1] ""  DK_Dummy
 SG_ SAD_L99H01_B_rDS_MON_1 : 13|1@1+ (1,0) [0|1] ""  DK_Dummy
 SG_ SAD_L99H01_B_rDS_MON_0 : 12|1@1+ (1,0) [0|1] ""  DK_Dummy
 SG_ SAD_L99H01_B_rCP_LOW : 8|1@1+ (1,0) [0|1] ""  DK_Dummy
 SG_ SAD_L99H01_B_OV : 1|1@1+ (1,0) [0|1] ""  DK_Dummy
 SG_ SAD_L99H01_B_GL_ER : 7|1@1+ (1,0) [0|1] ""  DK_Dummy
 SG_ SAD_L99H01_B_FE : 6|1@1+ (1,0) [0|1] ""  DK_Dummy
 SG_ SAD_L99H01_B_Error : 16|4@1+ (1,0) [0|0] ""  DK_Dummy
 SG_ SAD_L99H01_B_State : 20|4@1+ (1,0) [0|0] ""  DK_Dummy
 SG_ SAD_L99H01_B_SC2GND : 24|8@1+ (1,0) [0|0] ""  DK_Dummy
 SG_ SAD_L99H01_B_SC2BAT_LS : 32|8@1+ (1,0) [0|0] ""  DK_Dummy
 SG_ SAD_L99H01_B_SC2BAT_HS : 40|8@1+ (1,0) [0|0] ""  DK_Dummy

BO_ 2616992609 DEV_SAD_L99H01_A_Resp: 6 SAD
 SG_ SAD_L99H01_A_WDTO : 0|1@1+ (1,0) [0|1] ""  DK_Dummy
 SG_ SAD_L99H01_A_UV : 2|1@1+ (1,0) [0|1] ""  DK_Dummy
 SG_ SAD_L99H01_A_TW : 3|1@1+ (1,0) [0|1] ""  DK_Dummy
 SG_ SAD_L99H01_A_TSD : 4|1@1+ (1,0) [0|1] ""  DK_Dummy
 SG_ SAD_L99H01_A_STK_RESET_Q : 5|1@1+ (1,0) [0|1] ""  DK_Dummy
 SG_ SAD_L99H01_A_rOT_EXT : 9|1@1+ (1,0) [0|1] ""  DK_Dummy
 SG_ SAD_L99H01_A_rDS_MON_3 : 15|1@1+ (1,0) [0|1] ""  DK_Dummy
 SG_ SAD_L99H01_A_rDS_MON_2 : 14|1@1+ (1,0) [0|1] ""  DK_Dummy
 SG_ SAD_L99H01_A_rDS_MON_1 : 13|1@1+ (1,0) [0|1] ""  DK_Dummy
 SG_ SAD_L99H01_A_rDS_MON_0 : 12|1@1+ (1,0) [0|1] ""  DK_Dummy
 SG_ SAD_L99H01_A_rCP_LOW : 8|1@1+ (1,0) [0|1] ""  DK_Dummy
 SG_ SAD_L99H01_A_OV : 1|1@1+ (1,0) [0|1] ""  DK_Dummy
 SG_ SAD_L99H01_A_GL_ER : 7|1@1+ (1,0) [0|1] ""  DK_Dummy
 SG_ SAD_L99H01_A_FE : 6|1@1+ (1,0) [0|1] ""  DK_Dummy
 SG_ SAD_L99H01_A_Error : 16|4@1+ (1,0) [0|0] ""  DK_Dummy
 SG_ SAD_L99H01_A_State : 20|4@1+ (1,0) [0|0] ""  DK_Dummy
 SG_ SAD_L99H01_A_SC2GND : 24|8@1+ (1,0) [0|0] ""  DK_Dummy
 SG_ SAD_L99H01_A_SC2BAT_LS : 32|8@1+ (1,0) [0|0] ""  DK_Dummy
 SG_ SAD_L99H01_A_SC2BAT_HS : 40|8@1+ (1,0) [0|0] ""  DK_Dummy

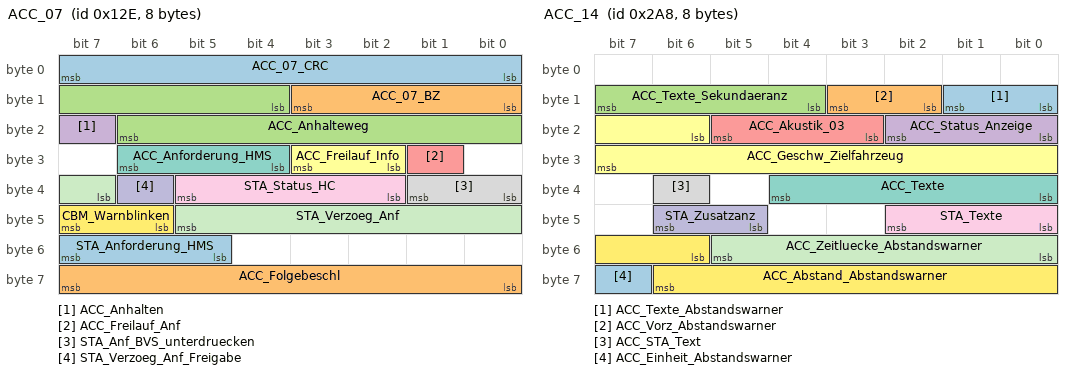
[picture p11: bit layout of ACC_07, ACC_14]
BO_ 302 ACC_07: 8 Gateway
 SG_ ACC_07_CRC : 0|8@1+ (1,0) [0|255] "" Vector__XXX
 SG_ ACC_07_BZ : 8|4@1+ (1,0) [0|15] "" Vector__XXX
 SG_ ACC_Anhalteweg : 12|11@1+ (0.01,0) [0|20.45] "Unit_Meter" Vector__XXX
 SG_ ACC_Anhalten : 23|1@1+ (1,0) [0|1] "" Vector__XXX
 SG_ ACC_Freilauf_Anf : 25|1@1+ (1,0) [0|1] "" Vector__XXX
 SG_ ACC_Freilauf_Info : 26|2@1+ (1,0) [0|3] "" Vector__XXX
 SG_ ACC_Anforderung_HMS : 28|3@1+ (1,0) [0|7] "" Vector__XXX
 SG_ STA_Anf_BVS_unterdruecken : 32|2@1+ (1,0) [0|3] "" Vector__XXX
 SG_ STA_Status_HC : 34|4@1+ (1,0) [0|15] "" Vector__XXX
 SG_ STA_Verzoeg_Anf_Freigabe : 38|1@1+ (1,0) [0|1] "" Vector__XXX
 SG_ STA_Verzoeg_Anf : 39|7@1+ (0.0625,-7.875) [-7.875|0] "Unit_MeterPerSeconSquar" Vector__XXX
 SG_ CBM_Warnblinken : 46|2@1+ (1,0) [0|3] ""  BCM2
 SG_ STA_Anforderung_HMS : 53|3@1+ (1,0) [0|7] "" Vector__XXX
 SG_ ACC_Folgebeschl : 56|8@1+ (0.03,-4.6) [-4.6|2.99] "Unit_MeterPerSeconSquar" Vector__XXX

BO_ 680 ACC_14: 8 Gateway
 SG_ ACC_Texte_Abstandswarner : 8|2@1+ (1,0) [0|3] "" Vector__XXX
 SG_ ACC_Vorz_Abstandswarner : 10|2@1+ (1,0) [0|3] "" Vector__XXX
 SG_ ACC_Texte_Sekundaeranz : 12|4@1+ (1,0) [0|15] "" Vector__XXX
 SG_ ACC_Status_Anzeige : 16|3@1+ (1,0) [0|7] ""  BCM1
 SG_ ACC_Akustik_03 : 19|3@1+ (1,0) [0|7] "" Vector__XXX
 SG_ ACC_Geschw_Zielfahrzeug : 22|10@1+ (0.32,0) [0|326.72] "Unit_KiloMeterPerHour" Vector__XXX
 SG_ ACC_Texte : 32|5@1+ (1,0) [0|31] "" Vector__XXX
 SG_ ACC_STA_Text : 38|1@1+ (1,0) [0|1] "" Vector__XXX
 SG_ STA_Texte : 40|3@1+ (1,0) [0|7] "" Vector__XXX
 SG_ STA_Zusatzanz : 45|2@1+ (1,0) [0|3] "" Vector__XXX
 SG_ ACC_Zeitluecke_Abstandswarner : 48|6@1+ (0.1,0) [0|6] "Unit_Secon" Vector__XXX
 SG_ ACC_Abstand_Abstandswarner : 54|9@1+ (1,0) [0|508] "" Vector__XXX
 SG_ ACC_Einheit_Abstandswarner : 63|1@1+ (1,0) [0|1] "" Vector__XXX

BO_ 64 Airbag_01: 8 Gateway
 SG_ Airbag_01_CRC : 0|8@1+ (1,0) [0|255] ""  BCM2,SitzMem_BFS,SitzMem_FS,SitzMem_HBFS,SitzMem_HFS,SitzMem_SR3
 SG_ Airbag_01_BZ : 8|4@1+ (1,0) [0|15] ""  BCM2,SitzMem_BFS,SitzMem_FS,SitzMem_HBFS,SitzMem_HFS,SitzMem_SR3
 SG_ AB_RGS_Anst : 12|4@1+ (1,0) [0|15] "" Vector__XXX
 SG_ AB_Front_Crash : 16|1@1+ (1,0) [0|1] ""  BCM2,SitzMem_BFS,SitzMem_FS,SitzMem_HBFS,SitzMem_HFS,SitzMem_SR3,VTS
 SG_ AB_Heck_Crash : 17|1@1+ (1,0) [0|1] ""  BCM2,SitzMem_BFS,SitzMem_FS,SitzMem_HBFS,SitzMem_HFS,SitzMem_SR3,VTS
 SG_ AB_SF_Crash : 18|1@1+ (1,0) [0|1] ""  BCM2,SitzMem_BFS,SitzMem_FS,SitzMem_HBFS,SitzMem_HFS,SitzMem_SR3,TSG_BFS,TSG_FS,VTS
 SG_ AB_SB_Crash : 19|1@1+ (1,0) [0|1] ""  BCM2,SitzMem_BFS,SitzMem_FS,SitzMem_HBFS,SitzMem_HFS,SitzMem_SR3,TSG_BFS,TSG_FS,VTS
 SG_ AB_Rollover_Crash : 20|1@1+ (1,0) [0|1] ""  BCM2,SitzMem_BFS,SitzMem_FS,SitzMem_HBFS,SitzMem_HFS,SitzMem_SR3,TSG_BFS,TSG_FS,VTS
 SG_ AB_Crash_Int : 21|3@1+ (1,0) [0|7] ""  BCM1,SitzMem_BFS,SitzMem_FS,SitzMem_HBFS,SitzMem_HFS,SitzMem_SR3,TSG_BFS,TSG_FS,VTS
 SG_ AB_Lampe : 24|1@1+ (1,0) [0|1] ""  VTS
 SG_ AB_Deaktiviert : 25|1@1+ (1,0) [0|1] "" Vector__XXX
 SG_ AB_VB_deaktiviert : 26|1@1+ (1,0) [0|1] "" Vector__XXX
 SG_ AB_Systemfehler : 27|1@1+ (1,0) [0|1] "" Vector__XXX
 SG_ AB_Diagnose : 28|1@1+ (1,0) [0|1] "" Vector__XXX
 SG_ AB_Stellgliedtest : 29|1@1+ (1,0) [0|1] ""  VTS
 SG_ AB_Erh_Auf_VB : 30|2@1+ (1,0) [0|3] "" Vector__XXX
 SG_ AB_Gurtwarn_VF : 32|1@1+ (1,0) [0|1] ""  VTS
 SG_ AB_Gurtwarn_VB : 33|1@1+ (1,0) [0|1] ""  VTS
 SG_ AB_Anzeige_Fussg : 34|2@1+ (1,0) [0|3] "" Vector__XXX
 SG_ AB_Texte_AKS : 36|2@1+ (1,0) [0|3] "" Vector__XXX
 SG_ AB_MKB_gueltig : 39|1@1+ (1,0) [0|1] "" Vector__XXX
 SG_ AB_MKB_Anforderung : 40|1@1+ (1,0) [0|1] "" Vector__XXX
 SG_ AB_Versorgungsspannung : 41|1@1+ (1,0) [0|1] "" Vector__XXX
 SG_ AB_Deaktivierung_HV : 42|3@1+ (1,0) [0|7] "" Vector__XXX
 SG_ AB_EDR_Trigger : 45|2@1+ (1,0) [0|3] "" Vector__XXX
 SG_ SC_LowSpeedCrashErkannt : 55|2@1+ (1,0) [0|3] "" Vector__XXX
 SG_ SC_Masterzeit : 57|7@1+ (0.04,0) [0|5.04] "Unit_Secon" Vector__XXX

BO_ 1312 Airbag_02: 8 Gateway
 SG_ Airbag_02_CRC : 0|8@1+ (1,0) [0|255] ""  SitzMem_BFS
 SG_ Airbag_02_BZ : 8|4@1+ (1,0) [0|15] ""  SitzMem_BFS
 SG_ LoGeWa_Event_Kombiwarnung : 12|4@1+ (1,0) [0|15] "" Vector__XXX
 SG_ AB_Anprall_Seite_Beifahrer : 17|1@1+ (1,0) [0|1] "" Vector__XXX
 SG_ AB_Anprall_Rollover : 18|1@1+ (1,0) [0|1] "" Vector__XXX
 SG_ AB_Anprall_FGS : 19|1@1+ (1,0) [0|1] "" Vector__XXX
 SG_ AB_Anprall_Front_Beifahrer : 20|1@1+ (1,0) [0|1] "" Vector__XXX
 SG_ AB_Anprall_Front_Fahrer : 21|1@1+ (1,0) [0|1] "" Vector__XXX
 SG_ AB_Anprall_Heck_Beifahrer : 22|1@1+ (1,0) [0|1] "" Vector__XXX
 SG_ AB_Anprall_Heck_Fahrer : 23|1@1+ (1,0) [0|1] "" Vector__XXX
 SG_ AB_Wickelklappung_Reihe2_MI : 24|2@1+ (1,0) [0|3] "" Vector__XXX
 SG_ AB_Belegung_VB : 26|2@1+ (1,0) [0|3] ""  BCM1,SitzMem_BFS,TSG_BFS,TSG_FS
 SG_ AB_Abschaltanf_SIH_BF : 28|1@1+ (1,0) [0|1] ""  BCM1
 SG_ AB_Anprall_Seite_Fahrer : 29|1@1+ (1,0) [0|1] "" Vector__XXX
 SG_ SC_PAO_Schriftzug_Anf : 30|2@1+ (1,0) [0|3] ""  BCM1
 SG_ SC_PAO_ON_Anf : 32|2@1+ (1,0) [0|3] ""  BCM1
 SG_ SC_PAO_OFF_Anf : 34|2@1+ (1,0) [0|3] ""  BCM1
 SG_ AB_Crashschwere : 36|3@1+ (1,0) [0|7] "" Vector__XXX
 SG_ AB_Anforderung_USM : 39|1@1+ (1,0) [0|1] "" Vector__XXX
 SG_ AB_Gurtschloss_FA : 40|2@1+ (1,0) [0|3] ""  BCM1,BCM2,TSG_BFS,VTS
 SG_ AB_Gurtschloss_BF : 42|2@1+ (1,0) [0|3] ""  BCM1,SitzMem_BFS,TSG_BFS,VTS
 SG_ AB_Gurtschloss_Reihe2_FA : 44|2@1+ (1,0) [0|3] ""  BCM1,SitzMem_HFS,TSG_FS
 SG_ AB_Gurtschloss_Reihe2_MI : 46|2@1+ (1,0) [0|3] ""  BCM1
 SG_ AB_Gurtschloss_Reihe2_BF : 48|2@1+ (1,0) [0|3] ""  BCM1,SitzMem_HBFS,TSG_FS
 SG_ AB_Gurtschloss_Reihe3_FA : 50|2@1+ (1,0) [0|3] "" Vector__XXX
 SG_ AB_Gurtschloss_Reihe3_MI : 52|2@1+ (1,0) [0|3] "" Vector__XXX
 SG_ AB_Gurtschloss_Reihe3_BF : 54|2@1+ (1,0) [0|3] "" Vector__XXX
 SG_ AB_Sitzpos_Sens_FA : 56|2@1+ (1,0) [0|3] ""  TSG_BFS,TSG_FS
 SG_ AB_Sitzpos_Sens_BF : 58|2@1+ (1,0) [0|3] ""  SitzMem_BFS,SitzMem_FS,SitzMem_HBFS,TSG_BFS,TSG_FS
 SG_ AB_Wickelklappung_Reihe2_BF : 60|2@1+ (1,0) [0|3] "" Vector__XXX
 SG_ AB_Wickelklappung_Reihe2_FA : 62|2@1+ (1,0) [0|3] "" Vector__XXX

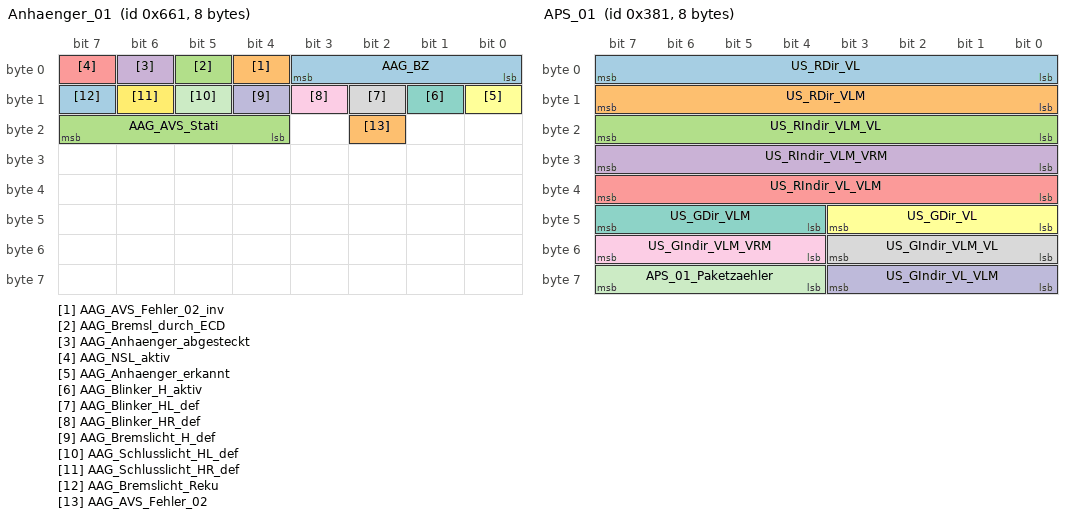
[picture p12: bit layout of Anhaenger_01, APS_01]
BO_ 1633 Anhaenger_01: 8 AAG
 SG_ AAG_BZ : 0|4@1+ (1,0) [0|15] ""  BCM2,Gateway
 SG_ AAG_AVS_Fehler_02_inv : 4|1@1+ (1,0) [0|1] ""  Gateway
 SG_ AAG_Bremsl_durch_ECD : 5|1@1+ (1,0) [0|1] ""  Gateway
 SG_ AAG_Anhaenger_abgesteckt : 6|1@1+ (1,0) [0|1] ""  BCM1,Gateway,MFG
 SG_ AAG_NSL_aktiv : 7|1@1+ (1,0) [0|1] ""  BCM1,Gateway
 SG_ AAG_Anhaenger_erkannt : 8|1@1+ (1,0) [0|1] ""  BCM1,BCM2,Gateway,HDSG,VTS
 SG_ AAG_Blinker_H_aktiv : 9|1@1+ (1,0) [0|1] ""  Gateway,MFG
 SG_ AAG_Blinker_HL_def : 10|1@1+ (1,0) [0|1] ""  Gateway
 SG_ AAG_Blinker_HR_def : 11|1@1+ (1,0) [0|1] ""  Gateway
 SG_ AAG_Bremslicht_H_def : 12|1@1+ (1,0) [0|1] ""  Gateway
 SG_ AAG_Schlusslicht_HL_def : 13|1@1+ (1,0) [0|1] ""  Gateway
 SG_ AAG_Schlusslicht_HR_def : 14|1@1+ (1,0) [0|1] ""  Gateway
 SG_ AAG_Bremslicht_Reku : 15|1@1+ (1,0) [0|1] ""  Gateway
 SG_ AAG_AVS_Fehler_02 : 18|1@1+ (1,0) [0|1] ""  BCM1,Gateway
 SG_ AAG_AVS_Stati : 20|4@1+ (1,0) [0|15] ""  BCM1,Gateway,VTS

BO_ 897 APS_01: 8 BCM1
 SG_ US_RDir_VL : 0|8@1+ (0.02,0) [0|5.1] "Unit_Meter"  Gateway
 SG_ US_RDir_VLM : 8|8@1+ (0.02,0) [0|5.1] "Unit_Meter"  Gateway
 SG_ US_RIndir_VLM_VL : 16|8@1+ (0.02,0) [0|5.1] "Unit_Meter"  Gateway
 SG_ US_RIndir_VLM_VRM : 24|8@1+ (0.02,0) [0|5.1] "Unit_Meter"  Gateway
 SG_ US_RIndir_VL_VLM : 32|8@1+ (0.02,0) [0|5.1] "Unit_Meter"  Gateway
 SG_ US_GDir_VL : 40|4@1+ (0.066,0) [0|0.99] ""  Gateway
 SG_ US_GDir_VLM : 44|4@1+ (0.066,0) [0|0.99] ""  Gateway
 SG_ US_GIndir_VLM_VL : 48|4@1+ (0.066,0) [0|0.99] ""  Gateway
 SG_ US_GIndir_VLM_VRM : 52|4@1+ (0.066,0) [0|0.99] ""  Gateway
 SG_ US_GIndir_VL_VLM : 56|4@1+ (0.066,0) [0|0.99] ""  Gateway
 SG_ APS_01_Paketzaehler : 60|4@1+ (1,0) [0|15] ""  Gateway

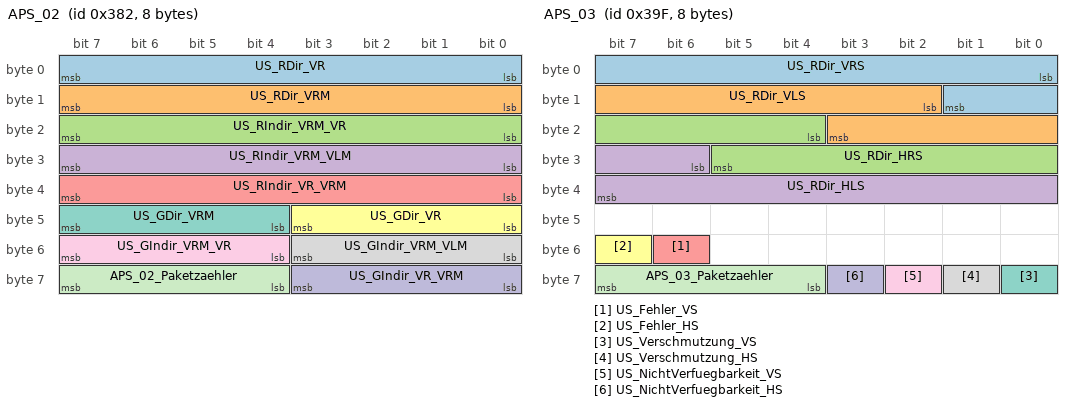
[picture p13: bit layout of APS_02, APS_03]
BO_ 898 APS_02: 8 BCM1
 SG_ US_RDir_VR : 0|8@1+ (0.02,0) [0|5.1] "Unit_Meter"  Gateway
 SG_ US_RDir_VRM : 8|8@1+ (0.02,0) [0|5.1] "Unit_Meter"  Gateway
 SG_ US_RIndir_VRM_VR : 16|8@1+ (0.02,0) [0|5.1] "Unit_Meter"  Gateway
 SG_ US_RIndir_VRM_VLM : 24|8@1+ (0.02,0) [0|5.1] "Unit_Meter"  Gateway
 SG_ US_RIndir_VR_VRM : 32|8@1+ (0.02,0) [0|5.1] "Unit_Meter"  Gateway
 SG_ US_GDir_VR : 40|4@1+ (0.066,0) [0|0.99] ""  Gateway
 SG_ US_GDir_VRM : 44|4@1+ (0.066,0) [0|0.99] ""  Gateway
 SG_ US_GIndir_VRM_VLM : 48|4@1+ (0.066,0) [0|0.99] ""  Gateway
 SG_ US_GIndir_VRM_VR : 52|4@1+ (0.066,0) [0|0.99] ""  Gateway
 SG_ US_GIndir_VR_VRM : 56|4@1+ (0.066,0) [0|0.99] ""  Gateway
 SG_ APS_02_Paketzaehler : 60|4@1+ (1,0) [0|15] ""  Gateway

BO_ 927 APS_03: 8 BCM1
 SG_ US_RDir_VRS : 0|10@1+ (0.015625,0) [0|15.984375] "Unit_Meter"  Gateway
 SG_ US_RDir_VLS : 10|10@1+ (0.015625,0) [0|15.984375] "Unit_Meter"  Gateway
 SG_ US_RDir_HRS : 20|10@1+ (0.015625,0) [0|15.984375] "Unit_Meter"  Gateway
 SG_ US_RDir_HLS : 30|10@1+ (0.015625,0) [0|15.984375] "Unit_Meter"  Gateway
 SG_ US_Fehler_VS : 54|1@1+ (1,0) [0|1] ""  Gateway
 SG_ US_Fehler_HS : 55|1@1+ (1,0) [0|1] ""  Gateway
 SG_ US_Verschmutzung_VS : 56|1@1+ (1,0) [0|1] ""  Gateway
 SG_ US_Verschmutzung_HS : 57|1@1+ (1,0) [0|1] ""  Gateway
 SG_ US_NichtVerfuegbarkeit_VS : 58|1@1+ (1,0) [0|1] ""  Gateway
 SG_ US_NichtVerfuegbarkeit_HS : 59|1@1+ (1,0) [0|1] ""  Gateway
 SG_ APS_03_Paketzaehler : 60|4@1+ (1,0) [0|15] ""  Gateway

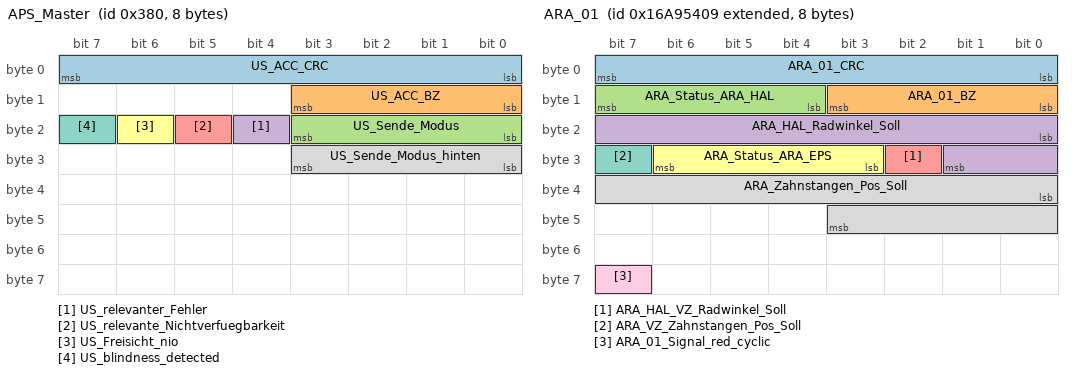
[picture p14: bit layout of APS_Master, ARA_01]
BO_ 896 APS_Master: 8 BCM1
 SG_ US_ACC_CRC : 0|8@1+ (1,0) [0|255] ""  Gateway
 SG_ US_ACC_BZ : 8|4@1+ (1,0) [0|15] ""  Gateway
 SG_ US_Sende_Modus : 16|4@1+ (1,0) [0|15] ""  Gateway
 SG_ US_relevanter_Fehler : 20|1@1+ (1,0) [0|1] ""  Gateway
 SG_ US_relevante_Nichtverfuegbarkeit : 21|1@1+ (1,0) [0|1] ""  Gateway
 SG_ US_Freisicht_nio : 22|1@1+ (1,0) [0|1] ""  Gateway
 SG_ US_blindness_detected : 23|1@1+ (1,0) [0|1] ""  Gateway
 SG_ US_Sende_Modus_hinten : 24|4@1+ (1,0) [0|15] ""  Gateway

BO_ 2527679497 ARA_01: 8 BCM1
 SG_ ARA_01_CRC : 0|8@1+ (1,0) [0|255] ""  Gateway
 SG_ ARA_01_BZ : 8|4@1+ (1,0) [0|15] ""  Gateway
 SG_ ARA_Status_ARA_HAL : 12|4@1+ (1,0) [0|15] ""  Gateway
 SG_ ARA_HAL_Radwinkel_Soll : 16|10@1+ (0.01,0) [0|10.19] "Unit_DegreOfArc"  Gateway
 SG_ ARA_HAL_VZ_Radwinkel_Soll : 26|1@1+ (1,0) [0|1] ""  Gateway
 SG_ ARA_Status_ARA_EPS : 27|4@1+ (1,0) [0|15] ""  Gateway
 SG_ ARA_VZ_Zahnstangen_Pos_Soll : 31|1@1+ (1,0) [0|1] ""  Gateway
 SG_ ARA_Zahnstangen_Pos_Soll : 32|12@1+ (0.02,0) [0|81.86] "Unit_MilliMeter"  Gateway
 SG_ ARA_01_Signal_red_cyclic : 63|1@1+ (1,0) [0|1] ""  Gateway

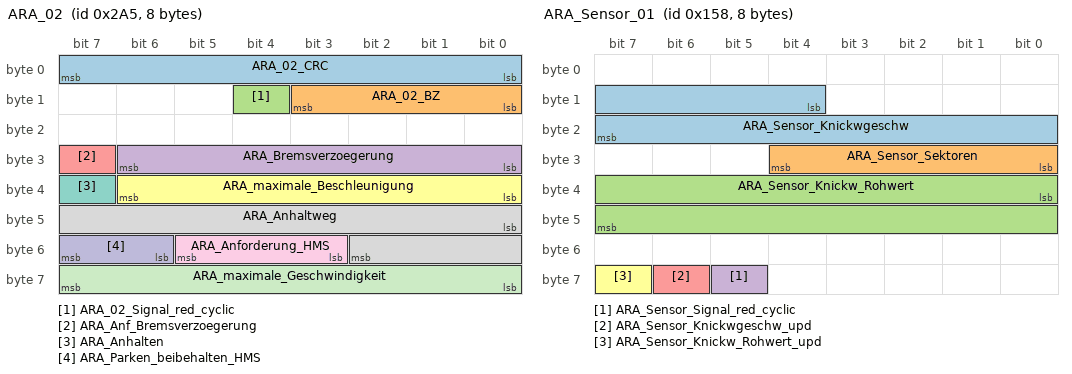
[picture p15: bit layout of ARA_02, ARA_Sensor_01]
BO_ 677 ARA_02: 8 BCM1
 SG_ ARA_02_CRC : 0|8@1+ (1,0) [0|255] ""  Gateway
 SG_ ARA_02_BZ : 8|4@1+ (1,0) [0|15] ""  Gateway
 SG_ ARA_02_Signal_red_cyclic : 12|1@1+ (1,0) [0|1] ""  Gateway
 SG_ ARA_Bremsverzoegerung : 24|7@1+ (0.1,0) [0|12] "Unit_MeterPerSeconSquar"  Gateway
 SG_ ARA_Anf_Bremsverzoegerung : 31|1@1+ (1,0) [0|1] ""  Gateway
 SG_ ARA_maximale_Beschleunigung : 32|7@1+ (0.1,-6) [-6|6.1] "Unit_MeterPerSeconSquar"  Gateway
 SG_ ARA_Anhalten : 39|1@1+ (1,0) [0|1] ""  Gateway
 SG_ ARA_Anhaltweg : 40|11@1+ (0.01,0) [0|20.45] "Unit_Meter"  Gateway
 SG_ ARA_Anforderung_HMS : 51|3@1+ (1,0) [0|7] ""  Gateway
 SG_ ARA_Parken_beibehalten_HMS : 54|2@1+ (1,0) [0|3] ""  Gateway
 SG_ ARA_maximale_Geschwindigkeit : 56|8@1+ (0.1,0) [0|25] "Unit_KiloMeterPerHour"  Gateway

BO_ 344 ARA_Sensor_01: 8 AAG
 SG_ ARA_Sensor_Knickwgeschw : 12|12@1+ (0.05,-100) [-100|100] "Unit_DegreOfArcPerSecon"  BCM1
 SG_ ARA_Sensor_Sektoren : 24|5@1+ (1,0) [0|31] ""  BCM1
 SG_ ARA_Sensor_Knickw_Rohwert : 32|16@1+ (0.0055,-180) [-180|179.997] "Unit_DegreOfArc"  BCM1
 SG_ ARA_Sensor_Signal_red_cyclic : 61|1@1+ (1,0) [0|1] ""  BCM1
 SG_ ARA_Sensor_Knickwgeschw_upd : 62|1@1+ (1,0) [0|1] ""  BCM1
 SG_ ARA_Sensor_Knickw_Rohwert_upd : 63|1@1+ (1,0) [0|1] ""  BCM1

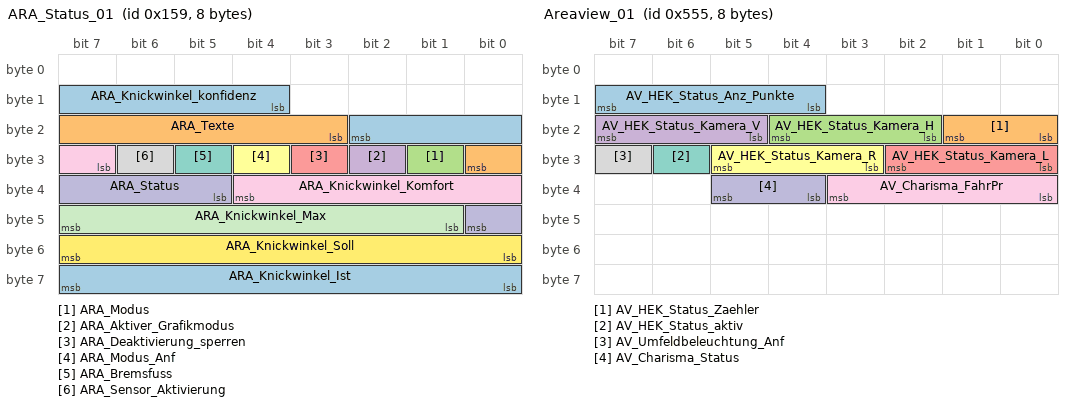
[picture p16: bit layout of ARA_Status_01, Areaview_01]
BO_ 345 ARA_Status_01: 8 BCM1
 SG_ ARA_Knickwinkel_konfidenz : 12|7@1+ (1,0) [0|120] "Unit_DegreOfArc"  Gateway
 SG_ ARA_Texte : 19|6@1+ (1,0) [0|63] ""  Gateway
 SG_ ARA_Modus : 25|1@1+ (1,0) [0|1] ""  Gateway
 SG_ ARA_Aktiver_Grafikmodus : 26|1@1+ (1,0) [0|1] ""  Gateway
 SG_ ARA_Deaktivierung_sperren : 27|1@1+ (1,0) [0|1] ""  Gateway
 SG_ ARA_Modus_Anf : 28|1@1+ (1,0) [0|1] ""  Gateway
 SG_ ARA_Bremsfuss : 29|1@1+ (1,0) [0|1] ""  Gateway
 SG_ ARA_Sensor_Aktivierung : 30|1@1+ (1,0) [0|1] ""  Gateway
 SG_ ARA_Knickwinkel_Komfort : 31|6@1+ (1,0) [0|60] "Unit_DegreOfArc"  Gateway
 SG_ ARA_Status : 37|4@1+ (1,0) [0|15] ""  AAG,Gateway
 SG_ ARA_Knickwinkel_Max : 41|7@1+ (1,0) [0|120] "Unit_DegreOfArc"  Gateway
 SG_ ARA_Knickwinkel_Soll : 48|8@1+ (1,-125) [-125|126] "Unit_DegreOfArc"  Gateway
 SG_ ARA_Knickwinkel_Ist : 56|8@1+ (1,-125) [-125|126] "Unit_DegreOfArc"  Gateway

BO_ 1365 Areaview_01: 8 Gateway
 SG_ AV_HEK_Status_Anz_Punkte : 12|4@1+ (1,0) [0|15] "" Vector__XXX
 SG_ AV_HEK_Status_Zaehler : 16|2@1+ (1,0) [0|3] "" Vector__XXX
 SG_ AV_HEK_Status_Kamera_H : 18|3@1+ (1,0) [0|7] "" Vector__XXX
 SG_ AV_HEK_Status_Kamera_V : 21|3@1+ (1,0) [0|7] "" Vector__XXX
 SG_ AV_HEK_Status_Kamera_L : 24|3@1+ (1,0) [0|7] "" Vector__XXX
 SG_ AV_HEK_Status_Kamera_R : 27|3@1+ (1,0) [0|7] "" Vector__XXX
 SG_ AV_HEK_Status_aktiv : 30|1@1+ (1,0) [0|1] "" Vector__XXX
 SG_ AV_Umfeldbeleuchtung_Anf : 31|1@1+ (1,0) [0|1] ""  BCM1
 SG_ AV_Charisma_FahrPr : 32|4@1+ (1,0) [0|15] "" Vector__XXX
 SG_ AV_Charisma_Status : 36|2@1+ (1,0) [0|3] "" Vector__XXX

BO_ 2536704256 BAP_Aussenlicht_ASG_01: 8 Gateway
 SG_ BAP_Aussenlicht_ASG_01_Header : 0|8@1+ (1,0) [0|255] ""  BCM1

BO_ 2536704272 BAP_Aussenlicht_FSG_01: 8 BCM1
 SG_ BAP_Aussenlicht_FSG_01_Header : 0|8@1+ (1,0) [0|255] ""  Gateway

BO_ 2536711427 BAP_BatteryControl_ASG_04: 8 VTS
 SG_ BAP_BatteryControl_ASG_04_Header : 0|8@1+ (1,0) [0|255] ""  Gateway

BO_ 2536711440 BAP_BatteryControl_FSG_01: 8 Gateway
 SG_ BAP_BatteryControl_FSG_01_Header : 0|8@1+ (1,0) [0|255] ""  VTS

BO_ 2536705794 BAP_BC_ASG_03: 8 VTS
 SG_ BAP_BC_ASG_03_Header : 0|8@1+ (1,0) [0|255] ""  Gateway

BO_ 2536705808 BAP_BC_FSG_01: 8 Gateway
 SG_ BAP_BC_FSG_01_Header : 0|8@1+ (1,0) [0|255] ""  VTS

BO_ 2536767264 BAP_Debug_Cmd: 8 Vector__XXX
 SG_ BAP_Debug_Cmd : 0|16@1+ (1,0) [0|65535] ""  BCM1,BCM2,Gateway,MFG,SitzMem_BFS,SitzMem_FS,SitzMem_HBFS,SitzMem_HFS,SpoilerSG,VTS

BO_ 2536767280 BAP_Debug_Data: 8 BCM1
 SG_ BAP_Debug_Data : 0|64@1+ (1,0) [0|1.84467440737096E+019] "" Vector__XXX

BO_ 2536705280 BAP_Doorlocking_ASG_01: 8 Gateway
 SG_ BAP_Doorlocking_ASG_01_Header : 0|8@1+ (1,0) [0|255] ""  BCM2

BO_ 2536705281 BAP_Doorlocking_ASG_02: 8 Gateway
 SG_ BAP_Doorlocking_ASG_02_Header : 0|8@1+ (1,0) [0|255] ""  BCM2

BO_ 2536705282 BAP_Doorlocking_ASG_03: 8 Gateway
 SG_ BAP_Doorlocking_ASG_03_Data : 0|8@1+ (1,0) [0|255] ""  BCM2

BO_ 2536705283 BAP_Doorlocking_ASG_04: 8 VTS
 SG_ BAP_Doorlocking_ASG_04_Header : 0|8@1+ (1,0) [0|255] ""  BCM2

BO_ 2536705296 BAP_Doorlocking_FSG_01: 8 BCM2
 SG_ BAP_Doorlocking_FSG_01_Header : 0|8@1+ (1,0) [0|255] ""  Gateway,VTS

BO_ 2536707072 BAP_Homelink_ASG_01: 8 Gateway
 SG_ BAP_Homelink_ASG_01_Header : 0|8@1+ (1,0) [0|255] ""  BCM1

BO_ 2536707088 BAP_Homelink_FSG_01: 8 BCM1
 SG_ BAP_Homelink_FSG_01_Header : 0|8@1+ (1,0) [0|255] ""  Gateway

BO_ 2536704000 BAP_Innenlicht_ASG_01: 8 Gateway
 SG_ BAP_Innenlicht_ASG_01_Header : 0|8@1+ (1,0) [0|255] ""  BCM1

BO_ 2536704016 BAP_Innenlicht_FSG_01: 8 BCM1
 SG_ BAP_Innenlicht_FSG_01_Header : 0|8@1+ (1,0) [0|255] ""  Gateway

BO_ 2536702211 BAP_Klima1_ASG_04: 8 VTS
 SG_ BAP_Klima1_ASG_04_Header : 0|8@1+ (1,0) [0|255] ""  Gateway

BO_ 2536702224 BAP_Klima1_FSG_01: 8 Gateway
 SG_ BAP_Klima1_FSG_01_Header : 0|8@1+ (1,0) [0|255] ""  VTS

BO_ 2536705536 BAP_Mirror_ASG_01: 8 Gateway
 SG_ BAP_Mirror_ASG_01_Header : 0|8@1+ (1,0) [0|255] ""  BCM2

BO_ 2536705552 BAP_Mirror_FSG_01: 8 BCM2
 SG_ BAP_Mirror_FSG_01_Header : 0|8@1+ (1,0) [0|255] ""  Gateway

BO_ 2536704512 BAP_OPS_ASG_01: 8 Gateway
 SG_ BAP_OPS_ASG_01_Header : 0|8@1+ (1,0) [0|255] ""  BCM1

BO_ 2536704513 BAP_OPS_ASG_02: 8 Gateway
 SG_ BAP_OPS_ASG_02_Header : 0|8@1+ (1,0) [0|255] ""  BCM1

BO_ 2536704528 BAP_OPS_FSG_01: 8 BCM1
 SG_ BAP_OPS_FSG_01_Header : 0|8@1+ (1,0) [0|255] ""  Gateway

BO_ 2536704529 BAP_OPS_FSG_02: 8 BCM1
 SG_ BAP_OPS_FSG_02_Header : 0|8@1+ (1,0) [0|255] ""  Gateway

BO_ 2536702722 BAP_ParkHeater_ASG_03: 8 VTS
 SG_ BAP_ParkHeater_ASG_03_Header : 0|8@1+ (1,0) [0|255] ""  Gateway

BO_ 2536702736 BAP_ParkHeater_FSG_01: 8 Gateway
 SG_ BAP_ParkHeater_FSG_01_Header : 0|8@1+ (1,0) [0|255] ""  VTS

BO_ 2536703746 BAP_RDK_ASG_03: 8 VTS
 SG_ BAP_RDK_ASG_03_Header : 0|8@1+ (1,0) [0|255] ""  Gateway

BO_ 2536703760 BAP_RDK_FSG_01: 8 Gateway
 SG_ BAP_RDK_FSG_01_Header : 0|8@1+ (1,0) [0|255] ""  VTS

BO_ 2536713728 BAP_RSE_ASG_01: 8 Gateway
 SG_ BAP_RSE_ASG_01_Header : 0|8@1+ (1,0) [0|255] ""  SitzMem_BFS

BO_ 2536713729 BAP_RSE_ASG_02: 8 Gateway
 SG_ BAP_RSE_ASG_02_Header : 0|8@1+ (1,0) [0|255] ""  SitzMem_BFS

BO_ 2536713744 BAP_RSE_FSG_01: 8 SitzMem_BFS
 SG_ BAP_RSE_FSG_01_Header : 0|8@1+ (1,0) [0|255] ""  Gateway

BO_ 2536718080 BAP_SeatCoDriverRear_ASG_01: 8 Gateway
 SG_ BAP_SeatCoDriverRear_ASG_01 : 0|8@1+ (1,0) [0|255] ""  SitzMem_HBFS

BO_ 2536718081 BAP_SeatCoDriverRear_ASG_02: 8 Gateway
 SG_ BAP_SeatCoDriverRear_ASG_02 : 0|8@1+ (1,0) [0|255] ""  SitzMem_HBFS

BO_ 2536718096 BAP_SeatCoDriverRear_FSG_01: 8 SitzMem_HBFS
 SG_ BAP_SeatCoDriverRear_FSG_01 : 0|8@1+ (1,0) [0|255] ""  Gateway

BO_ 2536717824 BAP_SeatDriverRear_ASG_01: 8 Gateway
 SG_ BAP_SeatDriverRear_ASG_01 : 0|8@1+ (1,0) [0|255] ""  SitzMem_HFS

BO_ 2536717825 BAP_SeatDriverRear_ASG_02: 8 Gateway
 SG_ BAP_SeatDriverRear_ASG_02 : 0|8@1+ (1,0) [0|255] ""  SitzMem_HFS

BO_ 2536717840 BAP_SeatDriverRear_FSG_01: 8 SitzMem_HFS
 SG_ BAP_SeatDriverRear_FSG_01 : 0|8@1+ (1,0) [0|255] ""  Gateway

BO_ 2536717056 BAP_SeatPneumatic_ASG_01: 8 Gateway
 SG_ BAP_SeatPneumatic_ASG_01_Header : 0|8@1+ (1,0) [0|255] ""  BCM1

BO_TX_BU_ 2536767280 : BCM1,BCM2,Gateway,MFG,SitzMem_BFS,SitzMem_FS,SitzMem_HBFS,SitzMem_HFS,SpoilerSG,VTS;

CM_ "MLBevo_KCAN_V8.07F Generated by BUSNET-NG 9.1.2";
CM_ BU_ AAG "MLBevo";
CM_ BU_ BCM1 "MLBevo";
CM_ BU_ BCM2 "MLBevo";
CM_ BU_ ELV "Elektronische Lenkradverriegelung";
CM_ BU_ Gateway "MLBevo Diagnoseinterface für Datenbus";
CM_ BU_ HDSG "MLBevo";
CM_ BU_ IEZS "Intelligentes Elektronisches Zündschloss (aktuell nur bei PAG)";
CM_ BU_ MFG "MLBevo";
CM_ BU_ MSBBR "Matrix Schluss-/Brems-/Blink-/Rückleuchte";
CM_ BU_ SAD "MQB/MLBevo";
CM_ BU_ SAD2 "Schiebeausstelldach 2";
CM_ BU_ Schwerpanzer_Zusatz "MFG-Portreplikator im Schwerpanzer-Fzg.   
";
CM_ BU_ SitzMem_BFS "MLBevo";
CM_ BU_ SitzMem_FS "MLBevo";
CM_ BU_ SitzMem_HBFS "MLBevo";
CM_ BU_ SitzMem_HFS "MLBevo";
CM_ BU_ SitzMem_SR3 "Sitzmemory für die dritte Sitzreihe";
CM_ BU_ SpoilerSG "Spoiler Steuergerät MSB";
CM_ BU_ TSG_BFS "MLBevo";
CM_ BU_ TSG_FS "MLBevo";
CM_ BU_ VSG "MLBevo";
CM_ SG_ 2617049857 DK_SAD_S_SL_ManZu "manuelles Schlie¯en vom Schiebedach";
CM_ SG_ 2617049857 DK_SAD_S_SL_ManAuf "manuelles Íffnen vom Schiebedach";
CM_ SG_ 2617049857 DK_SAD_S_SL_AutoZu "automatisch Schlie¯en vom Schiebedach";
CM_ SG_ 2617049857 DK_SAD_S_SL_AutoAuf "autiomatisch Íffnen vom Schiebedach";
CM_ SG_ 2617049857 DK_SAD_S_Schalter_Fehler "Fehler vom Schiebedachschalter";
CM_ SG_ 2617049857 DK_SAD_S_AL_ManZu "manuelles Schlie¯en vom Schiebedach";
CM_ SG_ 2617049857 DK_SAD_S_AL_ManAuf "manuelles Íffnen vom Schiebedach";
CM_ SG_ 2617049857 DK_SAD_S_AL_AutoZu "autiomatisch Schlie¯en vom Schiebedach";
CM_ SG_ 2617049857 DK_SAD_S_AL_AutoAuf "autiomatisch Íffnen vom Schiebedach";
CM_ SG_ 2617049857 DK_Rollo_S_Schalter_Fehler "Fehler vom Dachrolloschalter";
CM_ SG_ 2617049857 DK_Rollo_S_ManZu "manuelles Schlie¯en vom Dachrollo";
CM_ SG_ 2617049857 DK_Rollo_S_ManAuf "manuelles Íffnen vom Dachrollo";
CM_ SG_ 2617049857 DK_Rollo_S_AutoZu "automatisch Schlie¯en vom Dachrollo";
CM_ SG_ 2617049857 DK_Rollo_S_AutoAuf "autiomatisch Íffnen vom Dachrollo";
CM_ SG_ 2617049904 SAD_S_SL_ManZu "manuelles Schlie¯en vom Schiebedach";
CM_ SG_ 2617049904 SAD_S_SL_ManAuf "manuelles Íffnen vom Schiebedach";
CM_ SG_ 2617049904 SAD_S_SL_AutoZu "automatisch Schlie¯en vom Schiebedach";
CM_ SG_ 2617049904 SAD_S_SL_AutoAuf "autiomatisch Íffnen vom Schiebedach";
CM_ SG_ 2617049904 SAD_S_Schalter_Fehler "Fehler vom Schiebedachschalter";
CM_ SG_ 2617049904 SAD_S_AL_ManZu "manuelles Schlie¯en vom Schiebedach";
CM_ SG_ 2617049904 SAD_S_AL_ManAuf "manuelles Íffnen vom Schiebedach";
CM_ SG_ 2617049904 SAD_S_AL_AutoZu "autiomatisch Schlie¯en vom Schiebedach";
CM_ SG_ 2617049904 SAD_S_AL_AutoAuf "autiomatisch Íffnen vom Schiebedach";
CM_ SG_ 2617049904 Rollo_S_Schalter_Fehler "Fehler vom Dachrolloschalter";
CM_ SG_ 2617049904 Rollo_S_ManZu "manuelles Schlie¯en vom Dachrollo";
CM_ SG_ 2617049904 Rollo_S_ManAuf "manuelles Íffnen vom Dachrollo";
CM_ SG_ 2617049904 Rollo_S_AutoZu "automatisch Schlie¯en vom Dachrollo";
CM_ SG_ 2617049904 Rollo_S_AutoAuf "autiomatisch Íffnen vom Dachrollo";
CM_ SG_ 2617049905 Transportschutz_aktiv "Wird auf den Wert 1 gesetzt, wenn der Transportschutz aktiv ist.";
CM_ SG_ 2617049905 Transportmodus_aktiv "Wird auf den Wert 1 gesetzt, wenn der Transportmodus aktiv ist.";
CM_ SG_ 2617049905 Temperatur_SG_SAD "Gibt die Temperatur vom Schiebedachsteuergerõt an.";
CM_ SG_ 2617049905 P_Mode_aktiv "Bei Wert 1 P-Mode aktiv";
CM_ SG_ 2617049889 Position_Uncertainty_Motor_Rollo "
";
CM_ SG_ 2617049888 Temperatur_Motor_Dachrollo "Gibt die Temperatur vom Dachrollo Motor an";
CM_ SG_ 2617049888 Dachrollo_Normierlauf_RP_RF "Wird auf den Wert 1 gesetzt, wenn das Dachrollo seinen Normierlauf ausf³hrt.";
CM_ SG_ 2617049888 Dachrollo_initialisiert_RP "Wird auf den Wert 1 gesetzt, wenn das Dachrollo seinen RP Referenzpunkt hat.";
CM_ SG_ 2617049888 Dachrollo_Bewegung_zu "Bewegungsrichtung vom Dachrollo";
CM_ SG_ 2617049888 Dachrollo_Bewegung_auf "Bewegungsrichtung vom Dachrollo";
CM_ SG_ 2617049872 Temperatur_Motor_SAD "Gibt die Temperatur vom Schiebedach Motor an";
CM_ SG_ 2617049872 SAD_Normierlauf_RP_RF "Wird auf den Wert 1 gesetzt, wenn das Schiebedach seinen Normierlauf ausf³hrt.";
CM_ SG_ 2617049872 SAD_initialisiert_RP "Wird auf den Wert 1 gesetzt, wenn das Schiebedach seinen RP Referenzpunkt hat.";
CM_ SG_ 2617049872 SAD_Bewegung_zu "Bewegungsrichtung vom Schiebedach";
CM_ SG_ 2617049872 SAD_Bewegung_auf "Bewegungsrichtung vom Schiebedach";
CM_ SG_ 2616992545 Position_Uncertainty_Motor_Rollo "
";
CM_ SG_ 2616992560 SAD_S_SL_ManZu "manuelles Schlie¯en vom Schiebedach";
CM_ SG_ 2616992560 SAD_S_SL_ManAuf "manuelles Íffnen vom Schiebedach";
CM_ SG_ 2616992560 SAD_S_SL_AutoZu "automatisch Schlie¯en vom Schiebedach";
CM_ SG_ 2616992560 SAD_S_SL_AutoAuf "autiomatisch Íffnen vom Schiebedach";
CM_ SG_ 2616992560 SAD_S_Schalter_Fehler "Fehler vom Schiebedachschalter";
CM_ SG_ 2616992560 SAD_S_AL_ManZu "manuelles Schlie¯en vom Schiebedach";
CM_ SG_ 2616992560 SAD_S_AL_ManAuf "manuelles Íffnen vom Schiebedach";
CM_ SG_ 2616992560 SAD_S_AL_AutoZu "autiomatisch Schlie¯en vom Schiebedach";
CM_ SG_ 2616992560 SAD_S_AL_AutoAuf "autiomatisch Íffnen vom Schiebedach";
CM_ SG_ 2616992560 Rollo_S_Schalter_Fehler "Fehler vom Dachrolloschalter";
CM_ SG_ 2616992560 Rollo_S_ManZu "manuelles Schlie¯en vom Dachrollo";
CM_ SG_ 2616992560 Rollo_S_ManAuf "manuelles Íffnen vom Dachrollo";
CM_ SG_ 2616992560 Rollo_S_AutoZu "automatisch Schlie¯en vom Dachrollo";
CM_ SG_ 2616992560 Rollo_S_AutoAuf "autiomatisch Íffnen vom Dachrollo";
CM_ SG_ 2616992561 Transportschutz_aktiv "Wird auf den Wert 1 gesetzt, wenn der Transportschutz aktiv ist.";
CM_ SG_ 2616992561 Transportmodus_aktiv "Wird auf den Wert 1 gesetzt, wenn der Transportmodus aktiv ist.";
CM_ SG_ 2616992561 Temperatur_SG_SAD "Gibt die Temperatur vom Schiebedachsteuergerõt an.";
CM_ SG_ 2616992561 P_Mode_aktiv "Bei Wert 1 P-Mode aktiv";
CM_ SG_ 2616992544 Temperatur_Motor_Dachrollo "Gibt die Temperatur vom Dachrollo Motor an";
CM_ SG_ 2616992544 Dachrollo_Normierlauf_RP_RF "Wird auf den Wert 1 gesetzt, wenn das Dachrollo seinen Normierlauf ausf³hrt.";
CM_ SG_ 2616992544 Dachrollo_initialisiert_RP "Wird auf den Wert 1 gesetzt, wenn das Dachrollo seinen RP Referenzpunkt hat.";
CM_ SG_ 2616992544 Dachrollo_Bewegung_zu "Bewegungsrichtung vom Dachrollo";
CM_ SG_ 2616992544 Dachrollo_Bewegung_auf "Bewegungsrichtung vom Dachrollo";
CM_ SG_ 2616992528 Temperatur_Motor_SAD "Gibt die Temperatur vom Schiebedach Motor an";
CM_ SG_ 2616992528 SAD_Normierlauf_RP_RF "Wird auf den Wert 1 gesetzt, wenn das Schiebedach seinen Normierlauf ausf³hrt.";
CM_ SG_ 2616992528 SAD_initialisiert_RP "Wird auf den Wert 1 gesetzt, wenn das Schiebedach seinen RP Referenzpunkt hat.";
CM_ SG_ 2616992528 SAD_Bewegung_zu "Bewegungsrichtung vom Schiebedach";
CM_ SG_ 2616992528 SAD_Bewegung_auf "Bewegungsrichtung vom Schiebedach";
CM_ SG_ 2616992513 DK_SAD_S_SL_ManZu "manuelles Schlie¯en vom Schiebedach";
CM_ SG_ 2616992513 DK_SAD_S_SL_ManAuf "manuelles Íffnen vom Schiebedach";
CM_ SG_ 2616992513 DK_SAD_S_SL_AutoZu "automatisch Schlie¯en vom Schiebedach";
CM_ SG_ 2616992513 DK_SAD_S_SL_AutoAuf "autiomatisch Íffnen vom Schiebedach";
CM_ SG_ 2616992513 DK_SAD_S_Schalter_Fehler "Fehler vom Schiebedachschalter";
CM_ SG_ 2616992513 DK_SAD_S_AL_ManZu "manuelles Schlie¯en vom Schiebedach";
CM_ SG_ 2616992513 DK_SAD_S_AL_AutoZu "autiomatisch Schlie¯en vom Schiebedach";
CM_ SG_ 2616992513 DK_Rollo_S_Schalter_Fehler "Fehler vom Dachrolloschalter";
CM_ SG_ 2616992513 DK_Rollo_S_ManZu "manuelles Schlie¯en vom Dachrollo";
CM_ SG_ 2616992513 DK_Rollo_S_ManAuf "manuelles Íffnen vom Dachrollo";
CM_ SG_ 2616992513 DK_Rollo_S_AutoZu "automatisch Schlie¯en vom Dachrollo";
CM_ SG_ 2616992513 DK_Rollo_S_AutoAuf "autiomatisch Íffnen vom Dachrollo";
CM_ SG_ 2616992513 DK_SAD_S_AL_ManAuf "manuelles Íffnen vom Schiebedach";
CM_ SG_ 2616992513 DK_SAD_S_AL_AutoAuf "autiomatisch Íffnen vom Schiebedach";
CM_ BO_ 302 "ab MQB";
CM_ SG_ 302 ACC_07_CRC "Für MLB:
'Berechnung siehe Lastenheft 'Kommunikationsabsicherung für FlexRay und CAN''

Ab MQB und MLBevo:
'Berechnung siehe Lastenheft 'End-to-End Kommunikationsabsicherung''

Endwerte siehe Begleitdokument 'S-PDU Kennungsfolgen'";
CM_ SG_ 302 ACC_Anhalteweg "Verbleibender Weg bis zum Stillstand";
CM_ SG_ 302 ACC_Anhalten "Im Falle eines gesetzten Bits wird vom ACC ein Anhalten bis in den Stand gewünscht. Das Bit wird von ACC nur unterhalb einer appl. Geschwindigkeitsschwelle gesetzt. Notwendig für die ACCplus-Funktionalität. Nicht für Audi B8 relevant, jedoch im Vorgriff a";
CM_ SG_ 302 ACC_Freilauf_Anf "Freilauf-Anforderung durch Energo/ACC";
CM_ SG_ 302 ACC_Freilauf_Info "Freilauf-Freigabe durch Aktiven Teilnehmer Freilauf";
CM_ SG_ 302 ACC_Anforderung_HMS "Bremsanforderung an den Haltemanager";
CM_ SG_ 302 STA_Anf_BVS_unterdruecken "STA überstimmt die Anforderung des HC";
CM_ SG_ 302 STA_Status_HC "Status des Stauassistenten";
CM_ SG_ 302 STA_Verzoeg_Anf_Freigabe "STA_Freigabe_Verzoegerungsanforderung";
CM_ SG_ 302 STA_Verzoeg_Anf "STA_Verzoegerungsanforderung";
CM_ SG_ 302 CBM_Warnblinken "Ansteuerung_STA_Warnblinken";
CM_ SG_ 302 STA_Anforderung_HMS "Bremsanforderung an den Haltemanager";
CM_ SG_ 302 ACC_Folgebeschl "Sollbeschleunigung des ACC-Folgeregler";
CM_ SG_ 680 ACC_Texte_Abstandswarner "Signal zur Ansteuerung von Fahrer- und Warnhinweisen des Abstandswarners im Mitteldisplay";
CM_ SG_ 680 ACC_Vorz_Abstandswarner "Vorzeichen der Abstandsanzeige und -warnung";
CM_ SG_ 680 ACC_Texte_Sekundaeranz "Textdefinitionen für Anzeige ACC, Tempolimitassistent und Kurvenassistent";
CM_ SG_ 680 ACC_Status_Anzeige "Status nur zur Defintion von Anzeige im Kombi. Hinweis: Wird für die spez. VW-Anzeige (überlappende Anzeigebereiche) verwendet. Vom AUDI-ACC im Rahmen der Modulstrategie zu bedienen.";
CM_ SG_ 680 ACC_Akustik_03 "Ansteuerung der zugehörigen Akustik im Kombiinstrument, solange die entsprechende Bitkombination gesetzt ist.";
CM_ SG_ 680 ACC_Geschw_Zielfahrzeug "Nur Porsche E2: Zur grafischen Darstellung der Geschwindigkeit eines im ACC Regelbetrieb erkannten Zielobjektes bzw, vorausfahrenden Objektes. ACC ermittelt nach der Vorschrift: Vom Kombi eingelesene 'angezeigte Geschwindigkeit' plus TO_vrel";
CM_ SG_ 680 ACC_Texte "Zusätzliches Signal zu 'ACC_Texte_Primaeranz', welches Warnungen und Fahrerhinweise bzgl. ACC im Mitteldisplay des Kombis anzeigt.";
CM_ SG_ 680 ACC_STA_Text "ACC_STA_Text wird gesendet wenn aktiv regelt.";
CM_ SG_ 680 STA_Texte "Signal, welches Warnungen und Fahrerhinweise bzgl. der Funktion STA im Kombi anzeigt";
CM_ SG_ 680 STA_Zusatzanz "Für Anzeigen der STA-Funktion im Mitteldisplay";
CM_ SG_ 680 ACC_Zeitluecke_Abstandswarner "Anzeige der aktuellen Zeitluecke zum vorausfahrenden Fahrzeug";
CM_ SG_ 680 ACC_Abstand_Abstandswarner "Signal dient zur Anzeige des Abstands im Kombi
Hinweis: das Signal ist mit dem Signal ACC_Einheit_Abstandswarner zu interpretieren";
CM_ SG_ 680 ACC_Einheit_Abstandswarner "Einheit zu Signal ACC_Abstand_Abstandswarner";
CM_ SG_ 64 Airbag_01_CRC "Für MLB:
'Berechnung siehe Lastenheft 'Kommunikationsabsicherung für FlexRay und CAN''

Ab MQB und MLBevo:
'Berechnung siehe Lastenheft 'End-to-End Kommunikationsabsicherung''

Endwerte siehe Begleitdokument 'S-PDU Kennungsfolgen'";
CM_ SG_ 64 AB_RGS_Anst "PreCrash-Ansteuerung reversibler Gurtstraffer (Aktivierung und Kraftniveau)

10xx = deaktiviert";
CM_ SG_ 64 AB_Front_Crash "Bit wird bei Überschreitung der Gurtstraffer-, US- und RdW-Schwelle gesetzt";
CM_ SG_ 64 AB_Heck_Crash "Wird für alle neu anlaufenden Projekte umgesetzt: AB8.4, Audi8/VW8";
CM_ SG_ 64 AB_SF_Crash "Z.Zt. nur in Verbindung mit Crash-Intensität >= 100b (Kraftstoffpumpenabschaltung) verwendet.";
CM_ SG_ 64 AB_SB_Crash "Z.Zt. nur in Verbindung mit Crash-Intensität >= 100b (Kraftstoffpumpenabschaltung) verwendet.
";
CM_ SG_ 64 AB_Rollover_Crash "Wird im B6/B7 Cabrio und New Beetle Cabrio bedient. ";
CM_ SG_ 64 AB_Crash_Int "Crash_Intensität_1 = fahrzeugabhängige Reaktionen im Crash
Crash_Intensität_2 = fahrzeugabhängige Reaktionen im Crash
Crash_Intensität_3 = fahrzeugabhängige Reaktionen im Crash

Die jeweiligen fahrzeugabhängigen Reaktionen im Crash sind in einem separ";
CM_ SG_ 64 AB_Lampe "Sicherheitswarnlampe im Kombi wird vom Airbag-SG angesteuert; Zustand der Lampe wird auf dem CAN-Bus ausgegeben (auch Blinkinformation).";
CM_ SG_ 64 AB_Deaktiviert "Airbag oder Gurtstraffer wurden per Anpassung deaktiviert: Aktualisierung erst nach Selbsttest";
CM_ SG_ 64 AB_VB_deaktiviert "Als Option vorgehalten, Beifahrerairbag wurden per Schlüsselschalter oder Insassenerkennung deaktiviert";
CM_ SG_ 64 AB_Systemfehler "Systemfehler Ggf. wird Warnlampe dauernd eingeschaltet.";
CM_ SG_ 64 AB_Diagnose "Airbag in Diagnose";
CM_ SG_ 64 AB_Stellgliedtest "Information, ob Airbag im Stellgliedtest ist, um eine Notrufauflösung beim Stellgliedtest zu verhindern";
CM_ SG_ 64 AB_Erh_Auf_VB "Der Fahrer soll bei einem Statuswechsel des Beifahrerairbags (ausgelöst durch die Beifahrerinsassenerkennung oder den Schlüsselschloßschalter) aufmerksam gemacht werden durch eine Anzeige im Kombi. Nur Audi: gültig für: AB2 (4-Türer AU352), B7, C6, D3";
CM_ SG_ 64 AB_Gurtwarn_VF "Fahrer hat Gurt nicht gesteckt, Anzeige im Kombi";
CM_ SG_ 64 AB_Gurtwarn_VB "Beifahrer hat Gurt nicht gesteckt, Anzeige im Kombi";
CM_ SG_ 64 AB_Anzeige_Fussg "Anzeige für ausgelöste Fussgängerschutz-Aktuatorik";
CM_ SG_ 64 AB_Texte_AKS "Textanzeige für pyrotechnische Auslösung der aktiven Kopfstütze (AKS)";
CM_ SG_ 64 AB_MKB_gueltig "Multi-Kollisions-Bremsung im Airbag freigeschaltet";
CM_ SG_ 64 AB_MKB_Anforderung "Anforderung Multi-Kollisions-Bremsung";
CM_ SG_ 64 AB_Versorgungsspannung "Übertragung der Plausibilitätsinformation Kl.15-Last vs. Kl.15-CAN.
Bedienung im Fall Kl.15-Last 'EIN' und Kl.15-CAN 'AUS' mit Ausgabe Warnung/Akustik im Kombi.";
CM_ SG_ 64 AB_Deaktivierung_HV "Deaktivierung des HV-Systems und der HV-Teilnehmer im Crash (u.a. Hybrid- und Elektrofahrzeuge)";
CM_ SG_ 64 AB_EDR_Trigger "Triggerbedingung zur dezentralen Aufzeichnung unfallrelevanter Daten im Event Data Recorder";
CM_ SG_ 64 SC_LowSpeedCrashErkannt "Crash erkannt bei niedriger Geschwindigkeit";
CM_ SG_ 64 SC_Masterzeit "Masterzeit für alle Objektlisten";
CM_ SG_ 1312 Airbag_02_CRC "Für MLB:
'Berechnung siehe Lastenheft 'Kommunikationsabsicherung für FlexRay und CAN''

Ab MQB und MLBevo:
'Berechnung siehe Lastenheft 'End-to-End Kommunikationsabsicherung''

Endwerte siehe Begleitdokument 'S-PDU Kennungsfolgen'";
CM_ SG_ 1312 LoGeWa_Event_Kombiwarnung "Event für Kombiwarnung";
CM_ SG_ 1312 AB_Anprall_Seite_Beifahrer "Uebermittlung der Lage einer Kollision, Anprallzone Beifahrerseite Seite";
CM_ SG_ 1312 AB_Anprall_Rollover "Uebermittlung der Lage einer Kollision, Rollover erkannt";
CM_ SG_ 1312 AB_Anprall_FGS "Uebermittlung der Lage einer Kollision, Fussgaengerschutz-Aktorik";
CM_ SG_ 1312 AB_Anprall_Front_Beifahrer "Uebermittlung der Lage einer Kollision, Anprallzone Beifahrerseite vorne";
CM_ SG_ 1312 AB_Anprall_Front_Fahrer "Uebermittlung der Lage einer Kollision, Anprallzone Fahrerseite vorne";
CM_ SG_ 1312 AB_Anprall_Heck_Beifahrer "Uebermittlung der Lage einer Kollision, Anprallzone Beifahrerseite hinten";
CM_ SG_ 1312 AB_Anprall_Heck_Fahrer "Uebermittlung der Lage einer Kollision, Anprallzone Fahrerseite hinten";
CM_ SG_ 1312 AB_Wickelklappung_Reihe2_MI "Status Wickelklappung 2. Reihe Mitte, Mehrausstattung";
CM_ SG_ 1312 AB_Belegung_VB "Belegungserkennung vorne Beifahrer. Wird in US-Steuergeräten über Bladder-Matte bedient, optional bei RdW, falls SBE_EuroNCAP entschieden wird.";
CM_ SG_ 1312 AB_Abschaltanf_SIH_BF "Die Insassenerkennung auf der Beifahrerseite fordert bei Übertemperatur eine Abschaltung der Sitzheizung an. Die Übertemperatur kann bei niederohmigen Nebenschlüssen der Sitzheizungsmatte als Folge von zu hohem resultierenden Strom auftreten.";
CM_ SG_ 1312 AB_Anprall_Seite_Fahrer "Uebermittlung der Lage einer Kollision, Anprallzone Fahrerseite Seite";
CM_ SG_ 1312 SC_PAO_Schriftzug_Anf "Sollwert für LED 'PASSENGER AIRBAG' in Anzeige Passenger Airbag On/Off";
CM_ SG_ 1312 SC_PAO_ON_Anf "Sollwert für LED 'ON' in Anzeige Passenger Airbag On/Off";
CM_ SG_ 1312 SC_PAO_OFF_Anf "Sollwert für LED 'OFF' in Anzeige Passenger Airbag On/Off";
CM_ SG_ 1312 AB_Crashschwere "Übermittlung der Crashschwere an das Gateway (OBDC)";
CM_ SG_ 1312 AB_Anforderung_USM "Trigger für Gateway (OBDC) und MIB/MMI, dass ein USM-Ereignis erkannt wurde.";
CM_ SG_ 1312 AB_Gurtschloss_FA "Gurtschlosstatatus Fahrerseite";
CM_ SG_ 1312 AB_Gurtschloss_BF "Gurtschlossstatus Beifahrerseite";
CM_ SG_ 1312 AB_Gurtschloss_Reihe2_FA "Gurtschlossstatus 2. Reihe Fahrerseite, Mehrausstattung";
CM_ SG_ 1312 AB_Gurtschloss_Reihe2_MI "Gurtschlossstatus 2. Reihe Mitte,  Mehrausstattung";
CM_ SG_ 1312 AB_Gurtschloss_Reihe2_BF "Gurtschlossstatus 2. Reihe Beifahrerseite,  Mehrausstattung";
CM_ SG_ 1312 AB_Gurtschloss_Reihe3_FA "Gurtschlossstatus 3. Reihe Fahrerseite,  Mehrausstattung";
CM_ SG_ 1312 AB_Gurtschloss_Reihe3_MI "Gurtschlossstatus 3. Reihe Mitte,  Mehrausstattung";
CM_ SG_ 1312 AB_Gurtschloss_Reihe3_BF "Gurtschlossstatus 3. Reihe Beifahrerseite,  Mehrausstattung";
CM_ SG_ 1312 AB_Sitzpos_Sens_FA "Ausgabe Sitzposition Fahrer";
CM_ SG_ 1312 AB_Sitzpos_Sens_BF "Ausgabe Sitzposition Beifahrer";
CM_ SG_ 1312 AB_Wickelklappung_Reihe2_BF "Status Wickelklappung 2. Reihe Beifahrerseite, Mehrausstattung";
CM_ SG_ 1312 AB_Wickelklappung_Reihe2_FA "Status Wickelklappung 2. Reihe Fahrerseite, Mehrausstattung";
CM_ BO_ 1633 "ab MQB 7.2";
CM_ SG_ 1633 AAG_BZ "4bit-Botschaftszaehler, wird in jeder Sendebotschaft inkrementiert

";
CM_ SG_ 1633 AAG_AVS_Fehler_02_inv "Fehler AVS (inverses Signal)";
CM_ SG_ 1633 AAG_Bremsl_durch_ECD "Bremslicht durch ECD aktiv";
CM_ SG_ 1633 AAG_Anhaenger_abgesteckt "Anhaenger wurde bei Kl. 15 aus abgesteckt";
CM_ SG_ 1633 AAG_NSL_aktiv "Anhaenger Nebelschlusslicht aktiv";
CM_ SG_ 1633 AAG_Anhaenger_erkannt "Erkennung Anhaenger ";
CM_ SG_ 1633 AAG_Blinker_H_aktiv "Status: Anhaenger Blinker aktiv";
CM_ SG_ 1633 AAG_Blinker_HL_def "Anhaenger Blinker links defekt";
CM_ SG_ 1633 AAG_Blinker_HR_def "Anhaenger Blinker rechts defekt";
CM_ SG_ 1633 AAG_Bremslicht_H_def "Anhaenger Bremslicht defekt";
CM_ SG_ 1633 AAG_Schlusslicht_HL_def "Anhaenger Schlußlicht links defekt";
CM_ SG_ 1633 AAG_Schlusslicht_HR_def "Anhaenger Schlußlicht rechts defekt";
CM_ SG_ 1633 AAG_Bremslicht_Reku "AAG_Bremslicht_Reku meldet zyklisch den empfangenen Zustand des CAN-Signals MO_Bremslicht_Reku zurück.";
CM_ SG_ 1633 AAG_AVS_Fehler_02 "Fehler AVS";
CM_ SG_ 1633 AAG_AVS_Stati "Status AVS (bei abnehmbarer oder mech.schwenkbarer Anhängerkupplung ist der Status immer 0)
";
CM_ SG_ 897 US_RDir_VL "direkte Messung des US-Sensors vorne links";
CM_ SG_ 897 US_RDir_VLM "direkte Messung des US-Sensors vorne links Mitte";
CM_ SG_ 897 US_RIndir_VLM_VL "indirekte Messung der US-Sensoren vorne links Mitte (Sender) und vorne links (Empfänger)";
CM_ SG_ 897 US_RIndir_VLM_VRM "indirekte Messung der US-Sensoren vorne links Mitte (Sender) und vorne rechts Mitte (Empfänger)";
CM_ SG_ 897 US_RIndir_VL_VLM "indirekte Messung der US-Sensoren vorne links (Sender) und vorne links Mitte (Empfänger)";
CM_ SG_ 897 US_GDir_VL "Güte der direkten Messung des US-Sensors vorne links";
CM_ SG_ 897 US_GDir_VLM "Güte der direkten Messung des US-Sensors vorne links Mitte";
CM_ SG_ 897 US_GIndir_VLM_VL "Güte der indirekten Messung der US-Sensoren vorne links Mitte (Sender) und vorne links (Empfänger)";
CM_ SG_ 897 US_GIndir_VLM_VRM "Güte der indirekten Messung der US-Sensoren vorne links Mitte (Sender) und vorne rechts Mitte (Empfänger)";
CM_ SG_ 897 US_GIndir_VL_VLM "Güte der indirekten Messung der US-Sensoren vorne links (Sender) und vorne links Mitte (Empfänger)";
CM_ SG_ 897 APS_01_Paketzaehler "Wird verwendet zur Verifizierung der Botschafsreihenfolge
APS_Master
APS_01
APS_02

";
CM_ SG_ 898 US_RDir_VR "direkte Messung des US-Sensors vorne rechts";
CM_ SG_ 898 US_RDir_VRM "direkte Messung des US-Sensors vorne rechts Mitte";
CM_ SG_ 898 US_RIndir_VRM_VR "indirekte Messung der US-Sensoren vorne rechts  Mitte (Sender) und vorne rechts (Empfänger)";
CM_ SG_ 898 US_RIndir_VRM_VLM "indirekte Messung der US-Sensoren vorne rechts Mitte (Sender) und vorne links Mitte (Empfänger)";
CM_ SG_ 898 US_RIndir_VR_VRM "indirekte Messung der US-Sensoren vorne rechts (Sender) und vorne rechts Mitte (Empfänger)";
CM_ SG_ 898 US_GDir_VR "Güte der direkten Messung des US-Sensors vorne rechts";
CM_ SG_ 898 US_GDir_VRM "Güte der direkten Messung des US-Sensors vorne rechts Mitte";
CM_ SG_ 898 US_GIndir_VRM_VLM "Güte der indirekten Messung der US-Sensoren vorne rechts Mitte (Sender) und vorne links Mitte (Empfänger)";
CM_ SG_ 898 US_GIndir_VRM_VR "Güte der indirekten Messung der US-Sensoren vorne rechts Mitte (Sender) und vorne rechts (Empfänger)";
CM_ SG_ 898 US_GIndir_VR_VRM "Güte der indirekten Messung der US-Sensoren vorne rechts (Sender) und vorne rechts Mitte (Empfänger)";
CM_ SG_ 898 APS_02_Paketzaehler "Wird verwendet zur Verifizierung der Botschafsreihenfolge
APS_Master
APS_01
APS_02

";
CM_ SG_ 927 US_RDir_VRS "direkte Messung des US-Sensors vorne rechts seitlich";
CM_ SG_ 927 US_RDir_VLS "direkte Messung des US-Sensors vorne links seitlich";
CM_ SG_ 927 US_RDir_HRS "direkte Messung des US-Sensors hinten rechts seitlich";
CM_ SG_ 927 US_RDir_HLS "direkte Messung des US-Sensors hinten links seitlich";
CM_ SG_ 927 US_Fehler_VS "Fehler US-Sensoren vorne seitlich";
CM_ SG_ 927 US_Fehler_HS "Fehler US-Sensor hinten seitlich";
CM_ SG_ 927 US_Verschmutzung_VS "Verschmutzung US-Sensoren vorne seitlich";
CM_ SG_ 927 US_Verschmutzung_HS "Verschmutzung US-Sensoren hinten seitlich";
CM_ SG_ 927 US_NichtVerfuegbarkeit_VS "Nichtverfuegbarkeit US-Sensoren vorne seitlich";
CM_ SG_ 927 US_NichtVerfuegbarkeit_HS "Nichtverfuegbarkeit US-Sensoren hinten seitlich";
CM_ SG_ 927 APS_03_Paketzaehler "Wird verwendet zur Verifizierung der Botschafsreihenfolge";
CM_ SG_ 896 US_ACC_CRC "Ab MQB und MLBevo:
'Berechnung siehe Lastenheft 'End-to-End Kommunikationsabsicherung''

Endwerte siehe Begleitdokument 'S-PDU Kennungsfolgen'";
CM_ SG_ 896 US_Sende_Modus "US=Ultraschall
US_SendeModus:
0x0: keine für das ACC-SG relevanten Abstandswerte werden gesendet
0x1: 4K ext. range, 10 Signalwege verfügbar ('4m')
0x2: 4K norm. range, 10 Signalwege verfügbar ('2m')
0x3: 6K ext. range, 16 Signalwege verfügbar ('4m')";
CM_ SG_ 896 US_relevanter_Fehler "US erkennt einen Fehler, die Objektdetektion im Frontbereich betreffend, mit FSP-Eintrag.";
CM_ SG_ 896 US_relevante_Nichtverfuegbarkeit "US erkennt eine Nichtverfuegbarkeit, die Objektdetektion im Frontbereich betreffend, ohne FSP-Eintrag";
CM_ SG_ 896 US_Freisicht_nio "Blindheitserkennung
Nach KL15-Ein konnte Freisichtprüfung noch nicht erfüllt werden";
CM_ SG_ 896 US_blindness_detected "US erkennt selbständig eigene Blindheit durch äußere Einflüsse.";
CM_ SG_ 896 US_Sende_Modus_hinten "US=Ultraschall
US_Sende_Modus_hinten:
0x0: keine für das ACC-SG relevanten Abstandswerte werden gesendet
0x1....0x4: frei
0x5: 2-K. ext. range (PLA), 2 Signalwege verfügbar ('4m')
0x6: Modeumschaltung (ext -> norm oder norm -> ext)
0x7: Blindheitspr";
CM_ SG_ 2527679497 ARA_01_CRC "Berechnung siehe Lastenheft:
'End-to-End Kommunikationsabsicherung'";
CM_ SG_ 2527679497 ARA_01_BZ "Botschaftszähler
";
CM_ SG_ 2527679497 ARA_Status_ARA_HAL "Schnittstelle zum Austausch von Statusinformationen der internen Statusmaschine. Erforderlich zum Aktivieren der automatischen Lenkung.";
CM_ SG_ 2527679497 ARA_HAL_Radwinkel_Soll "Sollradwinkel durch ARA Anforderung";
CM_ SG_ 2527679497 ARA_HAL_VZ_Radwinkel_Soll "Vorzeichen des durch ARA angeforderten Radwinkel";
CM_ SG_ 2527679497 ARA_Status_ARA_EPS "Schnittstelle zum Austausch von Statusinformationen der internen Statusmaschine. Erforderlich zum Aktivieren der automatischen Lenkung.";
CM_ SG_ 2527679497 ARA_VZ_Zahnstangen_Pos_Soll "Vorzeichen der vom ARA angeforderten Zahnstangenposition der EPS (Fahreransicht: positiv = links von der Nullstellung des Lenkrades) ";
CM_ SG_ 2527679497 ARA_Zahnstangen_Pos_Soll "Steuerbefehl an EPS zum Einstellen der angeforderten Zahnstangenposition.";
CM_ SG_ 2527679497 ARA_01_Signal_red_cyclic "Zeigt die reduzierte Zykluszeit der CAN-Botschaft 'ARA_01' an.";
CM_ SG_ 677 ARA_02_CRC "Berechnung siehe Lastenheft:
'End-to-End Kommunikationsabsicherung'";
CM_ SG_ 677 ARA_02_BZ "Botschaftszähler
";
CM_ SG_ 677 ARA_02_Signal_red_cyclic "Zeigt die reduzierte Zykluszeit der CAN-Botschaft 'ARA_02' an.";
CM_ SG_ 677 ARA_Bremsverzoegerung "Verzögerungsanforderung Richtung ESC
(Botschaftszyklus z. B. im MQB gesteuert über ARA_02_Signal_red_cyclic)";
CM_ SG_ 677 ARA_Anf_Bremsverzoegerung "Anforderung einer Verzögerungsbremsung";
CM_ SG_ 677 ARA_maximale_Beschleunigung "Gibt den Wert der maximal zulässigen Beschleunigung vor. Die während aktiver ARA Regelung vom TSK zugelassen werden darf.";
CM_ SG_ 677 ARA_Anhalten "Im Falle eines gesetzten Bits werden vom ARA die Anhaltemechanismen im ESC aktiviert.";
CM_ SG_ 677 ARA_Anhaltweg "Gibt den gewünschten Anhalteweg vor (für Notbremsung Anhalteweg ==0m)";
CM_ SG_ 677 ARA_Anforderung_HMS "Anforderung vom ARA (Anhängerrangierassistent) an das HMS (Haltemanagement System)";
CM_ SG_ 677 ARA_Parken_beibehalten_HMS "Anforderung um automatisches lösen der Parkbremse zu verhindern";
CM_ SG_ 677 ARA_maximale_Geschwindigkeit "Gibt den Wert der maximal zulässigen Geschwindigkeit vor. Die während aktiver ARA Regelung vom TSK zugelassen werden darf.";
CM_ SG_ 344 ARA_Sensor_Knickwgeschw "Gibt die Knickwinkelgeschwindigkeit des Anhängers am Kugelkopf wieder.";
CM_ SG_ 344 ARA_Sensor_Sektoren "Anzahl Sektoren am Kugelkopf";
CM_ SG_ 344 ARA_Sensor_Knickw_Rohwert "Rohwert Anhängerknickwinkel am Kugelkopf";
CM_ SG_ 344 ARA_Sensor_Signal_red_cyclic "Zeigt die reduzierte Zykluszeit der CAN-Botschaft 'ARA_Sensor' an.";
CM_ SG_ 344 ARA_Sensor_Knickwgeschw_upd "Update-Signal von ARA_Sensor_Knickwgeschw";
CM_ SG_ 344 ARA_Sensor_Knickw_Rohwert_upd "Update-Signal für ARA_Sensor_Knickw_Rohwert";
CM_ SG_ 345 ARA_Knickwinkel_konfidenz "Gibt einen Unschärfewinkel zur Darstellung der Visiualisierung in der RV-Ansicht bei Notregelung an";
CM_ SG_ 345 ARA_Texte "Anforderung für Kombianzeigetexte und Akustik";
CM_ SG_ 345 ARA_Modus "Regelmodus ARA für Kombidarstellung";
CM_ SG_ 345 ARA_Aktiver_Grafikmodus "Zeigt an  das eine Grafik für ARA aktiviert werden soll";
CM_ SG_ 345 ARA_Deaktivierung_sperren "Unterdrückt die Deaktivierung der ARA- Visualisierung";
CM_ SG_ 345 ARA_Modus_Anf "Anforderung des ARA-Modus im Türsteuergerät";
CM_ SG_ 345 ARA_Bremsfuss "Anforderung des Bremsfusssymbols im Kombi";
CM_ SG_ 345 ARA_Sensor_Aktivierung "Anforderung der Aktivierung des Knickwinkelsensors.";
CM_ SG_ 345 ARA_Knickwinkel_Komfort "Knickwinkelgrenze bis zu der, bei maximalem Lenkeinschlag, eine sofortige gerade Rückwärtsfahrt möglich ist.";
CM_ SG_ 345 ARA_Status "Gibt den Status des ARA wieder";
CM_ SG_ 345 ARA_Knickwinkel_Max "Gibt den maximalen ausregelbaren Knickwinkel zwischen Anhänger und Fahrzeug wieder.";
CM_ SG_ 345 ARA_Knickwinkel_Soll "Vom Fahrer vorgegebener Knickwinkel.";
CM_ SG_ 345 ARA_Knickwinkel_Ist "Gibt den aktuellen Knickwinkel zwischen Anhänger und Fahrzeug wieder";
CM_ SG_ 1365 AV_HEK_Status_Anz_Punkte "Anzahl der Punkte des Polygons in den folgenden Botschaften AV_HEK_02";
CM_ SG_ 1365 AV_HEK_Status_Zaehler "Zykluszähler der Botschaft AV_HEK_01";
CM_ SG_ 1365 AV_HEK_Status_Kamera_H "Status der Heckkamera";
CM_ SG_ 1365 AV_HEK_Status_Kamera_V "Status der Frontkamera";
CM_ SG_ 1365 AV_HEK_Status_Kamera_L "Status der Spiegelkamera links";
CM_ SG_ 1365 AV_HEK_Status_Kamera_R "Status der Spiegelkamera rechts";
CM_ SG_ 1365 AV_HEK_Status_aktiv "Status der Funktion Hinderniserkennung durch Areaview";
CM_ SG_ 1365 AV_Umfeldbeleuchtung_Anf "Anforderung für die Aktivierung einer Umfeldbeleuchtung zur Unterstützung des Umfeldkamerasystems bei Dunkelheit";
CM_ SG_ 1365 AV_Charisma_FahrPr "Istwert der Kennlinie (siehe Systemlastenheft MQB FPA)";
CM_ SG_ 1365 AV_Charisma_Status "Charisma Systemstatus des Charisma-Teilnehmers";
BA_DEF_  "DBName" STRING ;
BA_DEF_  "GenNWMApBusSleep" STRING ;
BA_DEF_  "GenNWMApCanNormal" STRING ;
BA_DEF_  "GenNWMApCanOff" STRING ;
BA_DEF_  "GenNWMApCanOn" STRING ;
BA_DEF_  "GenNWMApCanSleep" STRING ;
BA_DEF_  "GenNWMApCanWakeUp" STRING ;
BA_DEF_  "GenNWMGotoMode_Awake" STRING ;
BA_DEF_  "GenNWMGotoMode_BusSleep" STRING ;
BA_DEF_  "GenNWMSleepTime" INT 0 1000000;
BA_DEF_  "GenNWMTalkNM" STRING ;
BA_DEF_  "Manufacturer" STRING ;
BA_DEF_  "NmhBaseAddress" HEX 0 536870911;
BA_DEF_  "NmhMessageCount" INT 0 256;
BA_DEF_  "NmType" STRING ;
BA_DEF_  "VAGTP20_SetupMessageCount" INT 0 255;
BA_DEF_  "VAGTP20_SetupStartAddress" HEX 0 2047;
BA_DEF_  "VersionDay" INT 1 31;
BA_DEF_  "VersionMonth" INT 1 12;
BA_DEF_  "VersionWeek" INT 1 52;
BA_DEF_  "VersionYear" INT 0 99;
BA_DEF_  "VersionNumber" INT 0 65535;
BA_DEF_  "Baudrate" INT 0 1000000;
BA_DEF_  "SamplePointMin" INT 1 100;
BA_DEF_  "SamplePointMax" INT 1 100;
BA_DEF_  "SyncJumpWidthMin" INT 1 4;
BA_DEF_  "SyncJumpWidthMax" INT 1 4;
BA_DEF_  "NmhTimeoutTimer" INT 0 65535;
BA_DEF_  "NmhWaitBusSleepTimer" INT 0 65535;
BA_DEF_  "NmhPrepareBusSleepTimer" INT 0 65535;
BA_DEF_  "NmhLongTimer" INT 0 65535;
BA_DEF_  "NmhNStart" INT 0 255;
BA_DEF_ BU_  "GenNodAutoGenDsp" ENUM  "No","Yes";
BA_DEF_ BU_  "GenNodAutoGenSnd" ENUM  "No","Yes";
BA_DEF_ BU_  "GenNodSleepTime" INT 0 1000000;
BA_DEF_ BU_  "ILUsed" ENUM  "No","Yes";
BA_DEF_ BU_  "ECUVariantDefault" ENUM  "No","Yes";
BA_DEF_ BU_  "ECUVariantGroup" STRING ;
BA_DEF_ BU_  "NodeLayerModules" STRING ;
BA_DEF_ BU_  "NmhNode" ENUM  "No","Yes";
BA_DEF_ BU_  "NmNode" ENUM  "No","Yes";
BA_DEF_ BO_  "DiagRequest" ENUM  "No","Yes";
BA_DEF_ BO_  "DiagResponse" ENUM  "No","Yes";
BA_DEF_ BO_  "DiagState" ENUM  "No","Yes";
BA_DEF_ BO_  "GenMsgChkConstant" HEX 0 4095;
BA_DEF_ BO_  "GenMsgCycleTime" INT 0 65535;
BA_DEF_ BO_  "GenMsgCycleTimeFast" INT 0 65535;
BA_DEF_ BO_  "GenMsgDelayTime" INT 0 100000;
BA_DEF_ BO_  "GenMsgILSupport" ENUM  "No","Yes";
BA_DEF_ BO_  "GenMsgNrOfRepetition" INT 0 100;
BA_DEF_ BO_  "GenMsgPDUConstants" STRING ;
BA_DEF_ BO_  "GenMsgSendType" ENUM  "Cyclic","not_used","not_used","not_used","not_used","not_used","not_used","IfActive","NoMsgSendType";
BA_DEF_ BO_  "GenMsgStartDelayTime" INT 0 100000;
BA_DEF_ BO_  "NmMessage" ENUM  "No","Yes";
BA_DEF_ BO_  "NmhMessage" ENUM  "No","Yes";
BA_DEF_ BO_  "MsgType" ENUM  "Application","NM ","NMH","TP2.0","ISO-TP ","BAP","EID";
BA_DEF_ BO_  "VAGTP20_API" HEX 0 255;
BA_DEF_ BO_  "VAGTP20_DynConnection" ENUM  "No","Yes";
BA_DEF_ BO_  "VAGTP20_DynSetup" ENUM  "No","Yes";
BA_DEF_ BO_  "VAGTP20_StatConnection" ENUM  "No","Yes";
BA_DEF_ SG_  "GenSigActiveRepetitions" INT -2147483648 2147483647;
BA_DEF_ SG_  "GenSigInactiveValue" INT -2147483648 2147483647;
BA_DEF_ SG_  "GenSigSendType" ENUM  "Cyclic","OnWrite","OnWriteWithRepetition","OnChange","OnChangeWithRepetition","IfActive","IfActiveWithRepetition","NoSigSendType","OnChangeAndIfActive","OnChangeAndIfActiveWithRepetition";
BA_DEF_ SG_  "GenSigStartValue" INT -2147483648 2147483647;
BA_DEF_ SG_  "NWM-WakeupAllowed" ENUM  "No","Yes";
BA_DEF_ SG_  "GenSigFuncType" ENUM  "NoFunction","MsgCounter","CRC-8","XOR","XOR-2","DatedBit","SW-Kl15","CHK","Constant","Protocol","CRC-8-SAE_J1850";
BA_DEF_ SG_  "GenSigSwitchedByIgnition" ENUM  "No","Yes";
BA_DEF_ SG_  "Fehlerwert" HEX 0 2147483647;
BA_DEF_ SG_  "GenSigMissingSourceValue" HEX 0 2147483647;
BA_DEF_REL_ BU_SG_REL_  "GenSigTimeoutTime" INT 0 65535;
BA_DEF_DEF_  "DBName" "";
BA_DEF_DEF_  "GenNWMApBusSleep" "";
BA_DEF_DEF_  "GenNWMApCanNormal" "";
BA_DEF_DEF_  "GenNWMApCanOff" "";
BA_DEF_DEF_  "GenNWMApCanOn" "";
BA_DEF_DEF_  "GenNWMApCanSleep" "";
BA_DEF_DEF_  "GenNWMApCanWakeUp" "";
BA_DEF_DEF_  "GenNWMGotoMode_Awake" "";
BA_DEF_DEF_  "GenNWMGotoMode_BusSleep" "";
BA_DEF_DEF_  "GenNWMSleepTime" 0;
BA_DEF_DEF_  "GenNWMTalkNM" "";
BA_DEF_DEF_  "Manufacturer" "";
BA_DEF_DEF_  "NmhBaseAddress" 0;
BA_DEF_DEF_  "NmhMessageCount" 1;
BA_DEF_DEF_  "NmType" "None";
BA_DEF_DEF_  "VAGTP20_SetupMessageCount" 0;
BA_DEF_DEF_  "VAGTP20_SetupStartAddress" 0;
BA_DEF_DEF_  "VersionDay" 4.26918962551288E-316;
BA_DEF_DEF_  "VersionMonth" 4.26919436854308E-316;
BA_DEF_DEF_  "VersionWeek" 4.26919199702798E-316;
BA_DEF_DEF_  "VersionYear" 4.34231845564268E-316;
BA_DEF_DEF_  "VersionNumber" 0;
BA_DEF_DEF_  "Baudrate" 0;
BA_DEF_DEF_  "SamplePointMin" 1;
BA_DEF_DEF_  "SamplePointMax" 1;
BA_DEF_DEF_  "SyncJumpWidthMin" 1;
BA_DEF_DEF_  "SyncJumpWidthMax" 1;
BA_DEF_DEF_  "NmhTimeoutTimer" 0;
BA_DEF_DEF_  "NmhWaitBusSleepTimer" 0;
BA_DEF_DEF_  "NmhPrepareBusSleepTimer" 0;
BA_DEF_DEF_  "NmhLongTimer" 0;
BA_DEF_DEF_  "NmhNStart" 0;
BA_DEF_DEF_  "GenNodAutoGenDsp" "Yes";
BA_DEF_DEF_  "GenNodAutoGenSnd" "Yes";
BA_DEF_DEF_  "GenNodSleepTime" 0;
BA_DEF_DEF_  "ILUsed" "Yes";
BA_DEF_DEF_  "ECUVariantDefault" "Yes";
BA_DEF_DEF_  "ECUVariantGroup" "";
BA_DEF_DEF_  "NodeLayerModules" "";
BA_DEF_DEF_  "NmhNode" "Yes";
BA_DEF_DEF_  "NmNode" "No";
BA_DEF_DEF_  "DiagRequest" "No";
BA_DEF_DEF_  "DiagResponse" "No";
BA_DEF_DEF_  "DiagState" "No";
BA_DEF_DEF_  "GenMsgChkConstant" 0;
BA_DEF_DEF_  "GenMsgCycleTime" 0;
BA_DEF_DEF_  "GenMsgCycleTimeFast" 0;
BA_DEF_DEF_  "GenMsgDelayTime" 0;
BA_DEF_DEF_  "GenMsgILSupport" "No";
BA_DEF_DEF_  "GenMsgNrOfRepetition" 0;
BA_DEF_DEF_  "GenMsgPDUConstants" "";
BA_DEF_DEF_  "GenMsgSendType" "NoMsgSendType";
BA_DEF_DEF_  "GenMsgStartDelayTime" 0;
BA_DEF_DEF_  "NmMessage" "No";
BA_DEF_DEF_  "NmhMessage" "No";
BA_DEF_DEF_  "MsgType" "Application";
BA_DEF_DEF_  "VAGTP20_API" 0;
BA_DEF_DEF_  "VAGTP20_DynConnection" "No";
BA_DEF_DEF_  "VAGTP20_DynSetup" "No";
BA_DEF_DEF_  "VAGTP20_StatConnection" "No";
BA_DEF_DEF_  "GenSigActiveRepetitions" 0;
BA_DEF_DEF_  "GenSigInactiveValue" 0;
BA_DEF_DEF_  "GenSigSendType" "NoSigSendType";
BA_DEF_DEF_  "GenSigStartValue" 0;
BA_DEF_DEF_  "NWM-WakeupAllowed" "No";
BA_DEF_DEF_  "GenSigFuncType" "NoFunction";
BA_DEF_DEF_  "GenSigSwitchedByIgnition" "Yes";
BA_DEF_DEF_  "Fehlerwert" 0;
BA_DEF_DEF_  "GenSigMissingSourceValue" 0;
BA_DEF_DEF_REL_ "GenSigTimeoutTime" 0;
BA_ "NmhNStart" 20;
BA_ "NmhLongTimer" 200;
BA_ "NmhPrepareBusSleepTimer" 500;
BA_ "NmhWaitBusSleepTimer" 750;
BA_ "NmhTimeoutTimer" 1000;
BA_ "SyncJumpWidthMax" 4;
BA_ "SyncJumpWidthMin" 2;
BA_ "SamplePointMax" 84;
BA_ "SamplePointMin" 80;
BA_ "Baudrate" 500000;
BA_ "VersionYear" 13;
BA_ "VersionWeek" 50;
BA_ "VersionMonth" 12;
BA_ "VersionDay" 12;
BA_ "VAGTP20_SetupStartAddress" 512;
BA_ "VAGTP20_SetupMessageCount" 128;
BA_ "NmType" "NM-High";
BA_ "NmhMessageCount" 256;
BA_ "NmhBaseAddress" 452984832;
BA_ "Manufacturer" "VAG";
BA_ "GenNWMTalkNM" "Nmh_ReqNetOn()";
BA_ "GenNWMSleepTime" 4000;
BA_ "GenNWMGotoMode_BusSleep" "Nmh_ReqNetOff()";
BA_ "GenNWMGotoMode_Awake" "Nmh_ReqNetOn()";
BA_ "GenNWMApCanWakeUp" "apCanWakeUp()";
BA_ "GenNWMApCanSleep" "apCanSleep()";
BA_ "GenNWMApCanOn" "NMIndnetOn()";
BA_ "GenNWMApCanOff" "NMIndnetOff()";
BA_ "GenNWMApCanNormal" "apCanNormal()";
BA_ "GenNWMApBusSleep" "NMIndNetSDN()";
BA_ "DBName" "MLBevo_KCAN";
BA_ "NodeLayerModules" BU_ AAG "NMHigh.DLL";
BA_ "GenNodSleepTime" BU_ AAG 4000;
BA_ "NodeLayerModules" BU_ BCM1 "NMHigh.DLL";
BA_ "ECUVariantGroup" BU_ BCM1 "BCM1";
BA_ "GenNodSleepTime" BU_ BCM1 4000;
BA_ "NodeLayerModules" BU_ BCM2 "NMHigh.DLL";
BA_ "ECUVariantGroup" BU_ BCM2 "BCM2";
BA_ "GenNodSleepTime" BU_ BCM2 4000;
BA_ "NodeLayerModules" BU_ ELV "NMHigh.DLL";
BA_ "ECUVariantGroup" BU_ ELV "ELV";
BA_ "GenNodSleepTime" BU_ ELV 4000;
BA_ "NodeLayerModules" BU_ Gateway "NMHigh.DLL";
BA_ "ECUVariantGroup" BU_ Gateway "Gateway";
BA_ "GenNodSleepTime" BU_ Gateway 4000;
BA_ "NodeLayerModules" BU_ HDSG "NMHigh.DLL";
BA_ "ECUVariantGroup" BU_ HDSG "HDSG";
BA_ "GenNodSleepTime" BU_ HDSG 4000;
BA_ "NodeLayerModules" BU_ IEZS "NMHigh.DLL";
BA_ "ECUVariantGroup" BU_ IEZS "IEZS";
BA_ "GenNodSleepTime" BU_ IEZS 4000;
BA_ "NodeLayerModules" BU_ MFG "NMHigh.DLL";
BA_ "ECUVariantGroup" BU_ MFG "MFG";
BA_ "GenNodSleepTime" BU_ MFG 4000;
BA_ "NodeLayerModules" BU_ MSBBR "NMHigh.DLL";
BA_ "ECUVariantGroup" BU_ MSBBR "MSBBR";
BA_ "GenNodSleepTime" BU_ MSBBR 4000;
BA_ "NodeLayerModules" BU_ SAD "NMHigh.DLL";
BA_ "ECUVariantGroup" BU_ SAD "SAD";
BA_ "GenNodSleepTime" BU_ SAD 4000;
BA_ "NodeLayerModules" BU_ SAD2 "NMHigh.DLL";
BA_ "ECUVariantGroup" BU_ SAD2 "SAD2";
BA_ "GenNodSleepTime" BU_ SAD2 4000;
BA_ "NmhNode" BU_ Schwerpanzer_Zusatz 0;
BA_ "GenNodSleepTime" BU_ Schwerpanzer_Zusatz 4000;
BA_ "NodeLayerModules" BU_ SitzMem_BFS "NMHigh.DLL";
BA_ "ECUVariantGroup" BU_ SitzMem_BFS "SitzMem_BFS";
BA_ "GenNodSleepTime" BU_ SitzMem_BFS 4000;
BA_ "NodeLayerModules" BU_ SitzMem_FS "NMHigh.DLL";
BA_ "ECUVariantGroup" BU_ SitzMem_FS "SitzMem_FS";
BA_ "GenNodSleepTime" BU_ SitzMem_FS 4000;
BA_ "NodeLayerModules" BU_ SitzMem_HBFS "NMHigh.DLL";
BA_ "ECUVariantGroup" BU_ SitzMem_HBFS "SitzMem_HBFS";
BA_ "GenNodSleepTime" BU_ SitzMem_HBFS 4000;
BA_ "NodeLayerModules" BU_ SitzMem_HFS "NMHigh.DLL";
BA_ "ECUVariantGroup" BU_ SitzMem_HFS "SitzMem_HFS";
BA_ "GenNodSleepTime" BU_ SitzMem_HFS 4000;
BA_ "NodeLayerModules" BU_ SitzMem_SR3 "NMHigh.DLL";
BA_ "ECUVariantGroup" BU_ SitzMem_SR3 "SitzMem_SR3";
BA_ "GenNodSleepTime" BU_ SitzMem_SR3 4000;
BA_ "NodeLayerModules" BU_ SpoilerSG "NMHigh.DLL";
BA_ "GenNodSleepTime" BU_ SpoilerSG 4000;
BA_ "NodeLayerModules" BU_ TSG_BFS "NMHigh.DLL";
BA_ "ECUVariantGroup" BU_ TSG_BFS "TSG_BFS";
BA_ "GenNodSleepTime" BU_ TSG_BFS 4000;
BA_ "NodeLayerModules" BU_ TSG_FS "NMHigh.DLL";
BA_ "ECUVariantGroup" BU_ TSG_FS "TSG_FS";
BA_ "GenNodSleepTime" BU_ TSG_FS 4000;
BA_ "NodeLayerModules" BU_ VSG "NMHigh.DLL";
BA_ "ECUVariantGroup" BU_ VSG "VSG";
BA_ "GenNodSleepTime" BU_ VSG 4000;
BA_ "NodeLayerModules" BU_ VTS "NMHigh.DLL";
BA_ "ECUVariantGroup" BU_ VTS "STS";
BA_ "ECUVariantDefault" BU_ VTS 0;
BA_ "GenNodSleepTime" BU_ VTS 4000;
BA_ "GenNodSleepTime" BU_ DK_Dummy 4000;
BA_ "NodeLayerModules" BU_ DK_Dummy "CANoeILNLVAG.dll,NMHigh.dll";
BA_ "GenMsgCycleTime" BO_ 2617049857 100;
BA_ "GenMsgCycleTimeFast" BO_ 2617049857 50;
BA_ "GenMsgDelayTime" BO_ 2617049857 50;
BA_ "GenMsgILSupport" BO_ 2617049857 1;
BA_ "GenMsgNrOfRepetition" BO_ 2617049857 3;
BA_ "GenMsgSendType" BO_ 2617049857 0;
BA_ "GenMsgCycleTime" BO_ 2617049904 200;
BA_ "GenMsgCycleTimeFast" BO_ 2617049904 50;
BA_ "GenMsgDelayTime" BO_ 2617049904 50;
BA_ "GenMsgILSupport" BO_ 2617049904 1;
BA_ "GenMsgNrOfRepetition" BO_ 2617049904 3;
BA_ "GenMsgSendType" BO_ 2617049904 0;
BA_ "GenMsgCycleTime" BO_ 2617049906 200;
BA_ "GenMsgDelayTime" BO_ 2617049906 100;
BA_ "GenMsgILSupport" BO_ 2617049906 1;
BA_ "GenMsgSendType" BO_ 2617049906 0;
BA_ "GenMsgCycleTime" BO_ 2617049905 200;
BA_ "GenMsgDelayTime" BO_ 2617049905 100;
BA_ "GenMsgILSupport" BO_ 2617049905 1;
BA_ "GenMsgSendType" BO_ 2617049905 0;
BA_ "GenMsgCycleTime" BO_ 2617049889 100;
BA_ "GenMsgDelayTime" BO_ 2617049889 100;
BA_ "GenMsgILSupport" BO_ 2617049889 1;
BA_ "GenMsgSendType" BO_ 2617049889 0;
BA_ "GenMsgCycleTime" BO_ 2617049888 100;
BA_ "GenMsgDelayTime" BO_ 2617049888 100;
BA_ "GenMsgILSupport" BO_ 2617049888 1;
BA_ "GenMsgSendType" BO_ 2617049888 0;
BA_ "GenMsgCycleTime" BO_ 2617049873 100;
BA_ "GenMsgDelayTime" BO_ 2617049873 100;
BA_ "GenMsgILSupport" BO_ 2617049873 1;
BA_ "GenMsgSendType" BO_ 2617049873 0;
BA_ "GenMsgCycleTime" BO_ 2617049872 100;
BA_ "GenMsgDelayTime" BO_ 2617049872 100;
BA_ "GenMsgILSupport" BO_ 2617049872 1;
BA_ "GenMsgSendType" BO_ 2617049872 0;
BA_ "GenMsgCycleTime" BO_ 2616992562 200;
BA_ "GenMsgDelayTime" BO_ 2616992562 100;
BA_ "GenMsgILSupport" BO_ 2616992562 1;
BA_ "GenMsgSendType" BO_ 2616992562 0;
BA_ "GenMsgCycleTime" BO_ 2616992545 100;
BA_ "GenMsgDelayTime" BO_ 2616992545 100;
BA_ "GenMsgILSupport" BO_ 2616992545 1;
BA_ "GenMsgSendType" BO_ 2616992545 0;
BA_ "GenMsgCycleTime" BO_ 2616992529 100;
BA_ "GenMsgDelayTime" BO_ 2616992529 100;
BA_ "GenMsgILSupport" BO_ 2616992529 1;
BA_ "GenMsgSendType" BO_ 2616992529 0;
BA_ "GenMsgCycleTime" BO_ 2616992560 200;
BA_ "GenMsgCycleTimeFast" BO_ 2616992560 50;
BA_ "GenMsgDelayTime" BO_ 2616992560 50;
BA_ "GenMsgILSupport" BO_ 2616992560 1;
BA_ "GenMsgNrOfRepetition" BO_ 2616992560 3;
BA_ "GenMsgSendType" BO_ 2616992560 0;
BA_ "GenMsgSendType" BO_ 2616992561 0;
BA_ "GenMsgILSupport" BO_ 2616992561 1;
BA_ "GenMsgDelayTime" BO_ 2616992561 100;
BA_ "GenMsgCycleTime" BO_ 2616992561 200;
BA_ "GenMsgSendType" BO_ 2616992544 0;
BA_ "GenMsgILSupport" BO_ 2616992544 1;
BA_ "GenMsgDelayTime" BO_ 2616992544 100;
BA_ "GenMsgCycleTime" BO_ 2616992544 100;
BA_ "GenMsgSendType" BO_ 2616992528 0;
BA_ "GenMsgILSupport" BO_ 2616992528 1;
BA_ "GenMsgDelayTime" BO_ 2616992528 100;
BA_ "GenMsgCycleTime" BO_ 2616992528 100;
BA_ "GenMsgSendType" BO_ 2616992513 0;
BA_ "GenMsgNrOfRepetition" BO_ 2616992513 3;
BA_ "GenMsgILSupport" BO_ 2616992513 1;
BA_ "GenMsgDelayTime" BO_ 2616992513 50;
BA_ "GenMsgCycleTimeFast" BO_ 2616992513 50;
BA_ "GenMsgCycleTime" BO_ 2616992513 100;
BA_ "GenMsgCycleTime" BO_ 2617058113 40;
BA_ "GenMsgILSupport" BO_ 2617058113 1;
BA_ "GenMsgSendType" BO_ 2617058113 0;
BA_ "GenMsgStartDelayTime" BO_ 2617058113 25;
BA_ "GenMsgCycleTime" BO_ 2617058112 100;
BA_ "GenMsgILSupport" BO_ 2617058112 1;
BA_ "GenMsgSendType" BO_ 2617058112 0;
BA_ "GenMsgCycleTime" BO_ 2617058128 100;
BA_ "GenMsgILSupport" BO_ 2617058128 1;
BA_ "GenMsgSendType" BO_ 2617058128 0;
BA_ "GenMsgCycleTime" BO_ 2617058161 50;
BA_ "GenMsgILSupport" BO_ 2617058161 1;
BA_ "GenMsgSendType" BO_ 2617058161 0;
BA_ "GenMsgStartDelayTime" BO_ 2617058161 20;
BA_ "GenMsgCycleTime" BO_ 2617058160 100;
BA_ "GenMsgILSupport" BO_ 2617058160 1;
BA_ "GenMsgSendType" BO_ 2617058160 0;
BA_ "GenMsgCycleTime" BO_ 2617058145 50;
BA_ "GenMsgILSupport" BO_ 2617058145 1;
BA_ "GenMsgSendType" BO_ 2617058145 0;
BA_ "GenMsgStartDelayTime" BO_ 2617058145 15;
BA_ "GenMsgCycleTime" BO_ 2617058144 100;
BA_ "GenMsgILSupport" BO_ 2617058144 1;
BA_ "GenMsgSendType" BO_ 2617058144 0;
BA_ "GenMsgCycleTime" BO_ 2617058116 20;
BA_ "GenMsgILSupport" BO_ 2617058116 1;
BA_ "GenMsgSendType" BO_ 2617058116 0;
BA_ "GenMsgStartDelayTime" BO_ 2617058116 10;
BA_ "GenMsgCycleTime" BO_ 2617058114 20;
BA_ "GenMsgILSupport" BO_ 2617058114 1;
BA_ "GenMsgSendType" BO_ 2617058114 0;
BA_ "GenMsgStartDelayTime" BO_ 2617058114 5;
BA_ "GenMsgILSupport" BO_ 2616992577 1;
BA_ "GenMsgCycleTime" BO_ 2616992577 40;
BA_ "GenMsgSendType" BO_ 2616992577 0;
BA_ "GenMsgStartDelayTime" BO_ 2616992577 25;
BA_ "GenMsgSendType" BO_ 2616992592 0;
BA_ "GenMsgILSupport" BO_ 2616992592 1;
BA_ "GenMsgCycleTime" BO_ 2616992592 100;
BA_ "GenMsgILSupport" BO_ 2616992576 1;
BA_ "GenMsgSendType" BO_ 2616992576 0;
BA_ "GenMsgCycleTime" BO_ 2616992576 100;
BA_ "GenMsgStartDelayTime" BO_ 2616992580 10;
BA_ "GenMsgILSupport" BO_ 2616992580 1;
BA_ "GenMsgSendType" BO_ 2616992580 0;
BA_ "GenMsgCycleTime" BO_ 2616992580 20;
BA_ "GenMsgStartDelayTime" BO_ 2616992578 5;
BA_ "GenMsgILSupport" BO_ 2616992578 1;
BA_ "GenMsgSendType" BO_ 2616992578 0;
BA_ "GenMsgCycleTime" BO_ 2616992578 20;
BA_ "GenMsgILSupport" BO_ 2616992624 1;
BA_ "GenMsgSendType" BO_ 2616992624 0;
BA_ "GenMsgCycleTime" BO_ 2616992624 100;
BA_ "GenMsgILSupport" BO_ 2616992608 1;
BA_ "GenMsgSendType" BO_ 2616992608 0;
BA_ "GenMsgCycleTime" BO_ 2616992608 100;
BA_ "GenMsgStartDelayTime" BO_ 2616992625 20;
BA_ "GenMsgILSupport" BO_ 2616992625 1;
BA_ "GenMsgSendType" BO_ 2616992625 0;
BA_ "GenMsgCycleTime" BO_ 2616992625 50;
BA_ "GenMsgStartDelayTime" BO_ 2616992609 15;
BA_ "GenMsgILSupport" BO_ 2616992609 1;
BA_ "GenMsgSendType" BO_ 2616992609 0;
BA_ "GenMsgCycleTime" BO_ 2616992609 50;
BA_ "GenMsgSendType" BO_ 302 0;
BA_ "GenMsgPDUConstants" BO_ 302 "0xf8,0xe5,0x97,0xc9,0xd6,0x07,0x47,0x21,0x66,0xdd,0xcf,0x6f,0xa1,0x94,0x74,0x63";
BA_ "GenMsgILSupport" BO_ 302 1;
BA_ "GenMsgCycleTime" BO_ 302 20;
BA_ "GenMsgSendType" BO_ 680 0;
BA_ "GenMsgILSupport" BO_ 680 1;
BA_ "GenMsgDelayTime" BO_ 680 40;
BA_ "GenMsgCycleTime" BO_ 680 200;
BA_ "GenMsgSendType" BO_ 64 0;
BA_ "GenMsgPDUConstants" BO_ 64 "0x40,0x40,0x40,0x40,0x40,0x40,0x40,0x40,0x40,0x40,0x40,0x40,0x40,0x40,0x40,0x40";
BA_ "GenMsgNrOfRepetition" BO_ 64 5;
BA_ "GenMsgILSupport" BO_ 64 1;
BA_ "GenMsgDelayTime" BO_ 64 10;
BA_ "GenMsgCycleTimeFast" BO_ 64 10;
BA_ "GenMsgCycleTime" BO_ 64 40;
BA_ "GenMsgChkConstant" BO_ 64 64;
BA_ "GenMsgSendType" BO_ 1312 0;
BA_ "GenMsgPDUConstants" BO_ 1312 "0x44,0x44,0x44,0x44,0x44,0x44,0x44,0x44,0x44,0x44,0x44,0x44,0x44,0x44,0x44,0x44";
BA_ "GenMsgILSupport" BO_ 1312 1;
BA_ "GenMsgDelayTime" BO_ 1312 20;
BA_ "GenMsgCycleTime" BO_ 1312 200;
BA_ "GenMsgChkConstant" BO_ 1312 68;
BA_ "GenMsgSendType" BO_ 1633 0;
BA_ "GenMsgILSupport" BO_ 1633 1;
BA_ "GenMsgCycleTime" BO_ 1633 100;
BA_ "GenMsgSendType" BO_ 897 0;
BA_ "GenMsgILSupport" BO_ 897 1;
BA_ "GenMsgCycleTime" BO_ 897 80;
BA_ "GenMsgSendType" BO_ 898 0;
BA_ "GenMsgILSupport" BO_ 898 1;
BA_ "GenMsgCycleTime" BO_ 898 80;
BA_ "GenMsgSendType" BO_ 927 0;
BA_ "GenMsgILSupport" BO_ 927 1;
BA_ "GenMsgCycleTime" BO_ 927 80;
BA_ "GenMsgSendType" BO_ 896 0;
BA_ "GenMsgPDUConstants" BO_ 896 "0x13,0x13,0x13,0x13,0x13,0x13,0x13,0x13,0x13,0x13,0x13,0x13,0x13,0x13,0x13,0x13";
BA_ "GenMsgILSupport" BO_ 896 1;
BA_ "GenMsgCycleTime" BO_ 896 80;
BA_ "GenMsgChkConstant" BO_ 896 19;
BA_ "GenMsgSendType" BO_ 2527679497 0;
BA_ "GenMsgPDUConstants" BO_ 2527679497 "0x2c,0xb1,0x1a,0x75,0xbb,0x65,0x79,0x47,0x81,0x2b,0xcc,0x96,0x17,0xdb,0xc0,0x94";
BA_ "GenMsgNrOfRepetition" BO_ 2527679497 5;
BA_ "GenMsgILSupport" BO_ 2527679497 1;
BA_ "GenMsgCycleTimeFast" BO_ 2527679497 20;
BA_ "GenMsgCycleTime" BO_ 2527679497 1000;
BA_ "GenMsgSendType" BO_ 677 0;
BA_ "GenMsgPDUConstants" BO_ 677 "0xb7,0x72,0xed,0x2a,0x58,0xd9,0xe6,0x08,0xf4,0x92,0xb5,0xe3,0xb4,0xae,0xcb,0xa5";
BA_ "GenMsgNrOfRepetition" BO_ 677 5;
BA_ "GenMsgILSupport" BO_ 677 1;
BA_ "GenMsgCycleTimeFast" BO_ 677 20;
BA_ "GenMsgCycleTime" BO_ 677 1000;
BA_ "GenMsgSendType" BO_ 344 0;
BA_ "GenMsgNrOfRepetition" BO_ 344 5;
BA_ "GenMsgILSupport" BO_ 344 1;
BA_ "GenMsgCycleTimeFast" BO_ 344 20;
BA_ "GenMsgCycleTime" BO_ 344 100;
BA_ "GenMsgSendType" BO_ 345 0;
BA_ "GenMsgILSupport" BO_ 345 1;
BA_ "GenMsgDelayTime" BO_ 345 20;
BA_ "GenMsgCycleTime" BO_ 345 100;
BA_ "GenMsgSendType" BO_ 1365 0;
BA_ "GenMsgILSupport" BO_ 1365 1;
BA_ "GenMsgDelayTime" BO_ 1365 60;
BA_ "GenMsgCycleTimeFast" BO_ 1365 60;
BA_ "GenMsgCycleTime" BO_ 1365 1000;
BA_ "MsgType" BO_ 2536704256 5;
BA_ "MsgType" BO_ 2536704272 5;
BA_ "MsgType" BO_ 2536711427 5;
BA_ "MsgType" BO_ 2536711440 5;
BA_ "MsgType" BO_ 2536705794 5;
BA_ "MsgType" BO_ 2536705808 5;
BA_ "MsgType" BO_ 2536767264 5;
BA_ "MsgType" BO_ 2536767280 5;
BA_ "MsgType" BO_ 2536705280 5;
BA_ "MsgType" BO_ 2536705281 5;
BA_ "MsgType" BO_ 2536705282 5;
BA_ "MsgType" BO_ 2536705283 5;
BA_ "MsgType" BO_ 2536705296 5;
BA_ "MsgType" BO_ 2536707072 5;
BA_ "MsgType" BO_ 2536707088 5;
BA_ "MsgType" BO_ 2536704000 5;
BA_ "MsgType" BO_ 2536704016 5;
BA_ "MsgType" BO_ 2536702211 5;
BA_ "MsgType" BO_ 2536702224 5;
BA_ "MsgType" BO_ 2536705536 5;
BA_ "MsgType" BO_ 2536705552 5;
BA_ "MsgType" BO_ 2536704512 5;
BA_ "MsgType" BO_ 2536704513 5;
BA_ "MsgType" BO_ 2536704528 5;
BA_ "MsgType" BO_ 2536704529 5;
BA_ "MsgType" BO_ 2536702722 5;
BA_ "MsgType" BO_ 2536702736 5;
BA_ "MsgType" BO_ 2536703746 5;
BA_ "MsgType" BO_ 2536703760 5;
BA_ "MsgType" BO_ 2536713728 5;
BA_ "MsgType" BO_ 2536713729 5;
BA_ "MsgType" BO_ 2536713744 5;
BA_ "MsgType" BO_ 2536718080 5;
BA_ "MsgType" BO_ 2536718081 5;
BA_ "MsgType" BO_ 2536718096 5;
BA_ "MsgType" BO_ 2536717824 5;
BA_ "MsgType" BO_ 2536717825 5;
BA_ "MsgType" BO_ 2536717840 5;
BA_ "MsgType" BO_ 2536717056 5;
BA_ "GenSigSendType" SG_ 2617049857 DK_SAD_S_SL_ManZu 3;
BA_ "GenSigSwitchedByIgnition" SG_ 2617049857 DK_SAD_S_SL_ManZu 0;
BA_ "GenSigSendType" SG_ 2617049857 DK_SAD_S_SL_ManAuf 3;
BA_ "GenSigSwitchedByIgnition" SG_ 2617049857 DK_SAD_S_SL_ManAuf 0;
BA_ "GenSigSendType" SG_ 2617049857 DK_SAD_S_SL_AutoZu 3;
BA_ "GenSigSwitchedByIgnition" SG_ 2617049857 DK_SAD_S_SL_AutoZu 0;
BA_ "GenSigSendType" SG_ 2617049857 DK_SAD_S_SL_AutoAuf 3;
BA_ "GenSigSwitchedByIgnition" SG_ 2617049857 DK_SAD_S_SL_AutoAuf 0;
BA_ "GenSigSendType" SG_ 2617049857 DK_SAD_S_Schalter_Fehler 3;
BA_ "GenSigSwitchedByIgnition" SG_ 2617049857 DK_SAD_S_Schalter_Fehler 0;
BA_ "GenSigSendType" SG_ 2617049857 DK_SAD_S_AL_ManZu 3;
BA_ "GenSigSwitchedByIgnition" SG_ 2617049857 DK_SAD_S_AL_ManZu 0;
BA_ "GenSigSendType" SG_ 2617049857 DK_SAD_S_AL_ManAuf 3;
BA_ "GenSigSwitchedByIgnition" SG_ 2617049857 DK_SAD_S_AL_ManAuf 0;
BA_ "GenSigSendType" SG_ 2617049857 DK_SAD_S_AL_AutoZu 3;
BA_ "GenSigSwitchedByIgnition" SG_ 2617049857 DK_SAD_S_AL_AutoZu 0;
BA_ "GenSigSendType" SG_ 2617049857 DK_SAD_S_AL_AutoAuf 3;
BA_ "GenSigSwitchedByIgnition" SG_ 2617049857 DK_SAD_S_AL_AutoAuf 0;
BA_ "GenSigSendType" SG_ 2617049857 DK_Rollo_S_Schalter_Fehler 3;
BA_ "GenSigSwitchedByIgnition" SG_ 2617049857 DK_Rollo_S_Schalter_Fehler 0;
BA_ "GenSigSendType" SG_ 2617049857 DK_Rollo_S_ManZu 3;
BA_ "GenSigSwitchedByIgnition" SG_ 2617049857 DK_Rollo_S_ManZu 0;
BA_ "GenSigSendType" SG_ 2617049857 DK_Rollo_S_ManAuf 3;
BA_ "GenSigSwitchedByIgnition" SG_ 2617049857 DK_Rollo_S_ManAuf 0;
BA_ "GenSigSendType" SG_ 2617049857 DK_Rollo_S_AutoZu 3;
BA_ "GenSigSwitchedByIgnition" SG_ 2617049857 DK_Rollo_S_AutoZu 0;
BA_ "GenSigSendType" SG_ 2617049857 DK_Rollo_S_AutoAuf 3;
BA_ "GenSigSwitchedByIgnition" SG_ 2617049857 DK_Rollo_S_AutoAuf 0;
BA_ "GenSigSendType" SG_ 2617049904 SAD_S_SL_ManZu 3;
BA_ "GenSigSwitchedByIgnition" SG_ 2617049904 SAD_S_SL_ManZu 0;
BA_ "GenSigSendType" SG_ 2617049904 SAD_S_SL_ManAuf 3;
BA_ "GenSigSwitchedByIgnition" SG_ 2617049904 SAD_S_SL_ManAuf 0;
BA_ "GenSigSendType" SG_ 2617049904 SAD_S_SL_AutoZu 3;
BA_ "GenSigSwitchedByIgnition" SG_ 2617049904 SAD_S_SL_AutoZu 0;
BA_ "GenSigSendType" SG_ 2617049904 SAD_S_SL_AutoAuf 3;
BA_ "GenSigSwitchedByIgnition" SG_ 2617049904 SAD_S_SL_AutoAuf 0;
BA_ "GenSigSendType" SG_ 2617049904 SAD_S_Schalter_Fehler 3;
BA_ "GenSigSwitchedByIgnition" SG_ 2617049904 SAD_S_Schalter_Fehler 0;
BA_ "GenSigSendType" SG_ 2617049904 SAD_S_AL_ManZu 3;
BA_ "GenSigSwitchedByIgnition" SG_ 2617049904 SAD_S_AL_ManZu 0;
BA_ "GenSigSendType" SG_ 2617049904 SAD_S_AL_ManAuf 3;
BA_ "GenSigSwitchedByIgnition" SG_ 2617049904 SAD_S_AL_ManAuf 0;
BA_ "GenSigSendType" SG_ 2617049904 SAD_S_AL_AutoZu 3;
BA_ "GenSigSwitchedByIgnition" SG_ 2617049904 SAD_S_AL_AutoZu 0;
BA_ "GenSigSendType" SG_ 2617049904 SAD_S_AL_AutoAuf 3;
BA_ "GenSigSwitchedByIgnition" SG_ 2617049904 SAD_S_AL_AutoAuf 0;
BA_ "GenSigSendType" SG_ 2617049904 Rollo_S_Schalter_Fehler 3;
BA_ "GenSigSwitchedByIgnition" SG_ 2617049904 Rollo_S_Schalter_Fehler 0;
BA_ "GenSigSendType" SG_ 2617049904 Rollo_S_ManZu 3;
BA_ "GenSigSwitchedByIgnition" SG_ 2617049904 Rollo_S_ManZu 0;
BA_ "GenSigSendType" SG_ 2617049904 Rollo_S_ManAuf 3;
BA_ "GenSigSwitchedByIgnition" SG_ 2617049904 Rollo_S_ManAuf 0;
BA_ "GenSigSendType" SG_ 2617049904 Rollo_S_AutoZu 3;
BA_ "GenSigSwitchedByIgnition" SG_ 2617049904 Rollo_S_AutoZu 0;
BA_ "GenSigSendType" SG_ 2617049904 Rollo_S_AutoAuf 3;
BA_ "GenSigSwitchedByIgnition" SG_ 2617049904 Rollo_S_AutoAuf 0;
BA_ "GenSigSendType" SG_ 2617049906 Event_Logging 0;
BA_ "GenSigSwitchedByIgnition" SG_ 2617049906 Event_Logging 0;
BA_ "GenSigSwitchedByIgnition" SG_ 2617049905 KnockOut_Timer 0;
BA_ "GenSigSendType" SG_ 2617049905 KnockOut_Timer 0;
BA_ "GenSigSendType" SG_ 2617049905 Bus_KnockOut_Timer 0;
BA_ "GenSigSwitchedByIgnition" SG_ 2617049905 Bus_KnockOut_Timer 0;
BA_ "GenSigSendType" SG_ 2617049905 Awake_Reason 0;
BA_ "GenSigSwitchedByIgnition" SG_ 2617049905 Awake_Reason 0;
BA_ "GenSigSendType" SG_ 2617049905 Ueberspannung_aktiv 0;
BA_ "GenSigSwitchedByIgnition" SG_ 2617049905 Ueberspannung_aktiv 0;
BA_ "GenSigSendType" SG_ 2617049905 Unterspannugn_aktiv 0;
BA_ "GenSigSwitchedByIgnition" SG_ 2617049905 Unterspannugn_aktiv 0;
BA_ "GenSigSwitchedByIgnition" SG_ 2617049905 Transportschutz_aktiv 0;
BA_ "GenSigSendType" SG_ 2617049905 Transportschutz_aktiv 0;
BA_ "GenSigSwitchedByIgnition" SG_ 2617049905 Transportmodus_aktiv 0;
BA_ "GenSigSendType" SG_ 2617049905 Transportmodus_aktiv 0;
BA_ "GenSigSwitchedByIgnition" SG_ 2617049905 Temperatur_SG_SAD 0;
BA_ "GenSigSendType" SG_ 2617049905 Temperatur_SG_SAD 0;
BA_ "GenSigSwitchedByIgnition" SG_ 2617049905 P_Mode_aktiv 0;
BA_ "GenSigSendType" SG_ 2617049905 P_Mode_aktiv 3;
BA_ "GenSigSendType" SG_ 2617049889 Position_Uncertainty_Motor_Rollo 0;
BA_ "GenSigSwitchedByIgnition" SG_ 2617049889 Position_Uncertainty_Motor_Rollo 0;
BA_ "GenSigSendType" SG_ 2617049889 Denorm_Reason_Motor_Dachrollo 0;
BA_ "GenSigSwitchedByIgnition" SG_ 2617049889 Denorm_Reason_Motor_Dachrollo 0;
BA_ "GenSigSendType" SG_ 2617049889 Stop_Reason_Motor_Dachrollo 0;
BA_ "GenSigSwitchedByIgnition" SG_ 2617049889 Stop_Reason_Motor_Dachrollo 0;
BA_ "GenSigSendType" SG_ 2617049889 Hall_Inkremente_Motor_Dachrollo 0;
BA_ "GenSigSwitchedByIgnition" SG_ 2617049889 Hall_Inkremente_Motor_Dachrollo 0;
BA_ "GenSigSendType" SG_ 2617049889 Spannung_Motor_Dachrollo 0;
BA_ "GenSigSwitchedByIgnition" SG_ 2617049889 Spannung_Motor_Dachrollo 0;
BA_ "GenSigSendType" SG_ 2617049888 Dachrollo_Funktionsabbruch_aktiv 0;
BA_ "GenSigSwitchedByIgnition" SG_ 2617049888 Dachrollo_Funktionsabbruch_aktiv 0;
BA_ "GenSigSwitchedByIgnition" SG_ 2617049888 Temperatur_Motor_Dachrollo 0;
BA_ "GenSigSendType" SG_ 2617049888 Temperatur_Motor_Dachrollo 0;
BA_ "GenSigSwitchedByIgnition" SG_ 2617049888 Dachrollo_Normierlauf_RP_RF 0;
BA_ "GenSigSendType" SG_ 2617049888 Dachrollo_Normierlauf_RP_RF 0;
BA_ "GenSigSwitchedByIgnition" SG_ 2617049888 Dachrollo_initialisiert_RP 0;
BA_ "GenSigSendType" SG_ 2617049888 Dachrollo_initialisiert_RP 0;
BA_ "GenSigSwitchedByIgnition" SG_ 2617049888 Dachrollo_Bewegung_zu 0;
BA_ "GenSigSendType" SG_ 2617049888 Dachrollo_Bewegung_zu 0;
BA_ "GenSigSwitchedByIgnition" SG_ 2617049888 Dachrollo_Bewegung_auf 0;
BA_ "GenSigSendType" SG_ 2617049888 Dachrollo_Bewegung_auf 0;
BA_ "GenSigSendType" SG_ 2617049873 Position_Uncertainty_Motor_SAD 0;
BA_ "GenSigSwitchedByIgnition" SG_ 2617049873 Position_Uncertainty_Motor_SAD 0;
BA_ "GenSigSendType" SG_ 2617049873 Denorm_Reason_Motor_SAD 0;
BA_ "GenSigSwitchedByIgnition" SG_ 2617049873 Denorm_Reason_Motor_SAD 0;
BA_ "GenSigSendType" SG_ 2617049873 Stop_Reason_Motor_SAD 0;
BA_ "GenSigSwitchedByIgnition" SG_ 2617049873 Stop_Reason_Motor_SAD 0;
BA_ "GenSigSendType" SG_ 2617049873 Hall_Inkremente_Motor_SAD 0;
BA_ "GenSigSwitchedByIgnition" SG_ 2617049873 Hall_Inkremente_Motor_SAD 0;
BA_ "GenSigSendType" SG_ 2617049873 Spannung_Motor_SAD 0;
BA_ "GenSigSwitchedByIgnition" SG_ 2617049873 Spannung_Motor_SAD 0;
BA_ "GenSigSendType" SG_ 2617049872 SAD_Funktionsabbruch_aktiv 0;
BA_ "GenSigSwitchedByIgnition" SG_ 2617049872 SAD_Funktionsabbruch_aktiv 0;
BA_ "GenSigSwitchedByIgnition" SG_ 2617049872 Temperatur_Motor_SAD 0;
BA_ "GenSigSendType" SG_ 2617049872 Temperatur_Motor_SAD 0;
BA_ "GenSigSwitchedByIgnition" SG_ 2617049872 SAD_Normierlauf_RP_RF 0;
BA_ "GenSigSendType" SG_ 2617049872 SAD_Normierlauf_RP_RF 0;
BA_ "GenSigSwitchedByIgnition" SG_ 2617049872 SAD_initialisiert_RP 0;
BA_ "GenSigSendType" SG_ 2617049872 SAD_initialisiert_RP 0;
BA_ "GenSigSwitchedByIgnition" SG_ 2617049872 SAD_Bewegung_zu 0;
BA_ "GenSigSendType" SG_ 2617049872 SAD_Bewegung_zu 0;
BA_ "GenSigSwitchedByIgnition" SG_ 2617049872 SAD_Bewegung_auf 0;
BA_ "GenSigSendType" SG_ 2617049872 SAD_Bewegung_auf 0;
BA_ "GenSigSendType" SG_ 2616992562 Event_Logging 0;
BA_ "GenSigSwitchedByIgnition" SG_ 2616992562 Event_Logging 0;
BA_ "GenSigSendType" SG_ 2616992545 Position_Uncertainty_Motor_Rollo 0;
BA_ "GenSigSwitchedByIgnition" SG_ 2616992545 Position_Uncertainty_Motor_Rollo 0;
BA_ "GenSigSendType" SG_ 2616992545 Denorm_Reason_Motor_Dachrollo 0;
BA_ "GenSigSwitchedByIgnition" SG_ 2616992545 Denorm_Reason_Motor_Dachrollo 0;
BA_ "GenSigSendType" SG_ 2616992545 Stop_Reason_Motor_Dachrollo 0;
BA_ "GenSigSwitchedByIgnition" SG_ 2616992545 Stop_Reason_Motor_Dachrollo 0;
BA_ "GenSigSendType" SG_ 2616992545 Hall_Inkremente_Motor_Dachrollo 0;
BA_ "GenSigSwitchedByIgnition" SG_ 2616992545 Hall_Inkremente_Motor_Dachrollo 0;
BA_ "GenSigSendType" SG_ 2616992545 Spannung_Motor_Dachrollo 0;
BA_ "GenSigSwitchedByIgnition" SG_ 2616992545 Spannung_Motor_Dachrollo 0;
BA_ "GenSigSendType" SG_ 2616992529 Position_Uncertainty_Motor_SAD 0;
BA_ "GenSigSwitchedByIgnition" SG_ 2616992529 Position_Uncertainty_Motor_SAD 0;
BA_ "GenSigSendType" SG_ 2616992529 Denorm_Reason_Motor_SAD 0;
BA_ "GenSigSwitchedByIgnition" SG_ 2616992529 Denorm_Reason_Motor_SAD 0;
BA_ "GenSigSendType" SG_ 2616992529 Stop_Reason_Motor_SAD 0;
BA_ "GenSigSwitchedByIgnition" SG_ 2616992529 Stop_Reason_Motor_SAD 0;
BA_ "GenSigSendType" SG_ 2616992529 Hall_Inkremente_Motor_SAD 0;
BA_ "GenSigSwitchedByIgnition" SG_ 2616992529 Hall_Inkremente_Motor_SAD 0;
BA_ "GenSigSendType" SG_ 2616992529 Spannung_Motor_SAD 0;
BA_ "GenSigSwitchedByIgnition" SG_ 2616992529 Spannung_Motor_SAD 0;
BA_ "GenSigSendType" SG_ 2616992560 SAD_S_SL_ManZu 3;
BA_ "GenSigSwitchedByIgnition" SG_ 2616992560 SAD_S_SL_ManZu 0;
BA_ "GenSigSendType" SG_ 2616992560 SAD_S_SL_ManAuf 3;
BA_ "GenSigSwitchedByIgnition" SG_ 2616992560 SAD_S_SL_ManAuf 0;
BA_ "GenSigSendType" SG_ 2616992560 SAD_S_SL_AutoZu 3;
BA_ "GenSigSwitchedByIgnition" SG_ 2616992560 SAD_S_SL_AutoZu 0;
BA_ "GenSigSendType" SG_ 2616992560 SAD_S_SL_AutoAuf 3;
BA_ "GenSigSwitchedByIgnition" SG_ 2616992560 SAD_S_SL_AutoAuf 0;
BA_ "GenSigSendType" SG_ 2616992560 SAD_S_Schalter_Fehler 3;
BA_ "GenSigSwitchedByIgnition" SG_ 2616992560 SAD_S_Schalter_Fehler 0;
BA_ "GenSigSendType" SG_ 2616992560 SAD_S_AL_ManZu 3;
BA_ "GenSigSwitchedByIgnition" SG_ 2616992560 SAD_S_AL_ManZu 0;
BA_ "GenSigSendType" SG_ 2616992560 SAD_S_AL_ManAuf 3;
BA_ "GenSigSwitchedByIgnition" SG_ 2616992560 SAD_S_AL_ManAuf 0;
BA_ "GenSigSendType" SG_ 2616992560 SAD_S_AL_AutoZu 3;
BA_ "GenSigSwitchedByIgnition" SG_ 2616992560 SAD_S_AL_AutoZu 0;
BA_ "GenSigSendType" SG_ 2616992560 SAD_S_AL_AutoAuf 3;
BA_ "GenSigSwitchedByIgnition" SG_ 2616992560 SAD_S_AL_AutoAuf 0;
BA_ "GenSigSendType" SG_ 2616992560 Rollo_S_Schalter_Fehler 3;
BA_ "GenSigSwitchedByIgnition" SG_ 2616992560 Rollo_S_Schalter_Fehler 0;
BA_ "GenSigSendType" SG_ 2616992560 Rollo_S_ManZu 3;
BA_ "GenSigSwitchedByIgnition" SG_ 2616992560 Rollo_S_ManZu 0;
BA_ "GenSigSendType" SG_ 2616992560 Rollo_S_ManAuf 3;
BA_ "GenSigSwitchedByIgnition" SG_ 2616992560 Rollo_S_ManAuf 0;
BA_ "GenSigSendType" SG_ 2616992560 Rollo_S_AutoZu 3;
BA_ "GenSigSwitchedByIgnition" SG_ 2616992560 Rollo_S_AutoZu 0;
BA_ "GenSigSendType" SG_ 2616992560 Rollo_S_AutoAuf 3;
BA_ "GenSigSwitchedByIgnition" SG_ 2616992560 Rollo_S_AutoAuf 0;
BA_ "GenSigSwitchedByIgnition" SG_ 2616992561 KnockOut_Timer 0;
BA_ "GenSigSendType" SG_ 2616992561 KnockOut_Timer 0;
BA_ "GenSigSendType" SG_ 2616992561 Bus_KnockOut_Timer 0;
BA_ "GenSigSwitchedByIgnition" SG_ 2616992561 Bus_KnockOut_Timer 0;
BA_ "GenSigSendType" SG_ 2616992561 Awake_Reason 0;
BA_ "GenSigSwitchedByIgnition" SG_ 2616992561 Awake_Reason 0;
BA_ "GenSigSendType" SG_ 2616992561 Ueberspannung_aktiv 0;
BA_ "GenSigSwitchedByIgnition" SG_ 2616992561 Ueberspannung_aktiv 0;
BA_ "GenSigSendType" SG_ 2616992561 Unterspannugn_aktiv 0;
BA_ "GenSigSwitchedByIgnition" SG_ 2616992561 Unterspannugn_aktiv 0;
BA_ "GenSigSwitchedByIgnition" SG_ 2616992561 Transportschutz_aktiv 0;
BA_ "GenSigSendType" SG_ 2616992561 Transportschutz_aktiv 0;
BA_ "GenSigSwitchedByIgnition" SG_ 2616992561 Transportmodus_aktiv 0;
BA_ "GenSigSendType" SG_ 2616992561 Transportmodus_aktiv 0;
BA_ "GenSigSwitchedByIgnition" SG_ 2616992561 Temperatur_SG_SAD 0;
BA_ "GenSigSendType" SG_ 2616992561 Temperatur_SG_SAD 0;
BA_ "GenSigSwitchedByIgnition" SG_ 2616992561 P_Mode_aktiv 0;
BA_ "GenSigSendType" SG_ 2616992561 P_Mode_aktiv 3;
BA_ "GenSigSendType" SG_ 2616992544 Dachrollo_Funktionsabbruch_aktiv 0;
BA_ "GenSigSwitchedByIgnition" SG_ 2616992544 Dachrollo_Funktionsabbruch_aktiv 0;
BA_ "GenSigSwitchedByIgnition" SG_ 2616992544 Temperatur_Motor_Dachrollo 0;
BA_ "GenSigSendType" SG_ 2616992544 Temperatur_Motor_Dachrollo 0;
BA_ "GenSigSwitchedByIgnition" SG_ 2616992544 Dachrollo_Normierlauf_RP_RF 0;
BA_ "GenSigSendType" SG_ 2616992544 Dachrollo_Normierlauf_RP_RF 0;
BA_ "GenSigSwitchedByIgnition" SG_ 2616992544 Dachrollo_initialisiert_RP 0;
BA_ "GenSigSendType" SG_ 2616992544 Dachrollo_initialisiert_RP 0;
BA_ "GenSigSwitchedByIgnition" SG_ 2616992544 Dachrollo_Bewegung_zu 0;
BA_ "GenSigSendType" SG_ 2616992544 Dachrollo_Bewegung_zu 0;
BA_ "GenSigSwitchedByIgnition" SG_ 2616992544 Dachrollo_Bewegung_auf 0;
BA_ "GenSigSendType" SG_ 2616992544 Dachrollo_Bewegung_auf 0;
BA_ "GenSigSendType" SG_ 2616992528 SAD_Funktionsabbruch_aktiv 0;
BA_ "GenSigSwitchedByIgnition" SG_ 2616992528 SAD_Funktionsabbruch_aktiv 0;
BA_ "GenSigSwitchedByIgnition" SG_ 2616992528 Temperatur_Motor_SAD 0;
BA_ "GenSigSendType" SG_ 2616992528 Temperatur_Motor_SAD 0;
BA_ "GenSigSwitchedByIgnition" SG_ 2616992528 SAD_Normierlauf_RP_RF 0;
BA_ "GenSigSendType" SG_ 2616992528 SAD_Normierlauf_RP_RF 0;
BA_ "GenSigSwitchedByIgnition" SG_ 2616992528 SAD_initialisiert_RP 0;
BA_ "GenSigSendType" SG_ 2616992528 SAD_initialisiert_RP 0;
BA_ "GenSigSwitchedByIgnition" SG_ 2616992528 SAD_Bewegung_zu 0;
BA_ "GenSigSendType" SG_ 2616992528 SAD_Bewegung_zu 0;
BA_ "GenSigSwitchedByIgnition" SG_ 2616992528 SAD_Bewegung_auf 0;
BA_ "GenSigSendType" SG_ 2616992528 SAD_Bewegung_auf 0;
BA_ "GenSigSwitchedByIgnition" SG_ 2616992513 DK_SAD_S_SL_ManZu 0;
BA_ "GenSigSendType" SG_ 2616992513 DK_SAD_S_SL_ManZu 3;
BA_ "GenSigSwitchedByIgnition" SG_ 2616992513 DK_SAD_S_SL_ManAuf 0;
BA_ "GenSigSendType" SG_ 2616992513 DK_SAD_S_SL_ManAuf 3;
BA_ "GenSigSwitchedByIgnition" SG_ 2616992513 DK_SAD_S_SL_AutoZu 0;
BA_ "GenSigSendType" SG_ 2616992513 DK_SAD_S_SL_AutoZu 3;
BA_ "GenSigSwitchedByIgnition" SG_ 2616992513 DK_SAD_S_SL_AutoAuf 0;
BA_ "GenSigSendType" SG_ 2616992513 DK_SAD_S_SL_AutoAuf 3;
BA_ "GenSigSwitchedByIgnition" SG_ 2616992513 DK_SAD_S_Schalter_Fehler 0;
BA_ "GenSigSendType" SG_ 2616992513 DK_SAD_S_Schalter_Fehler 3;
BA_ "GenSigSwitchedByIgnition" SG_ 2616992513 DK_SAD_S_AL_ManZu 0;
BA_ "GenSigSendType" SG_ 2616992513 DK_SAD_S_AL_ManZu 3;
BA_ "GenSigSwitchedByIgnition" SG_ 2616992513 DK_SAD_S_AL_AutoZu 0;
BA_ "GenSigSendType" SG_ 2616992513 DK_SAD_S_AL_AutoZu 3;
BA_ "GenSigSwitchedByIgnition" SG_ 2616992513 DK_Rollo_S_Schalter_Fehler 0;
BA_ "GenSigSendType" SG_ 2616992513 DK_Rollo_S_Schalter_Fehler 3;
BA_ "GenSigSwitchedByIgnition" SG_ 2616992513 DK_Rollo_S_ManZu 0;
BA_ "GenSigSendType" SG_ 2616992513 DK_Rollo_S_ManZu 3;
BA_ "GenSigSwitchedByIgnition" SG_ 2616992513 DK_Rollo_S_ManAuf 0;
BA_ "GenSigSendType" SG_ 2616992513 DK_Rollo_S_ManAuf 3;
BA_ "GenSigSwitchedByIgnition" SG_ 2616992513 DK_Rollo_S_AutoZu 0;
BA_ "GenSigSendType" SG_ 2616992513 DK_Rollo_S_AutoZu 3;
BA_ "GenSigSwitchedByIgnition" SG_ 2616992513 DK_Rollo_S_AutoAuf 0;
BA_ "GenSigSendType" SG_ 2616992513 DK_Rollo_S_AutoAuf 3;
BA_ "GenSigSwitchedByIgnition" SG_ 2616992513 DK_SAD_S_AL_ManAuf 0;
BA_ "GenSigSendType" SG_ 2616992513 DK_SAD_S_AL_ManAuf 3;
BA_ "GenSigSwitchedByIgnition" SG_ 2616992513 DK_SAD_S_AL_AutoAuf 0;
BA_ "GenSigSendType" SG_ 2616992513 DK_SAD_S_AL_AutoAuf 3;
BA_ "GenSigSwitchedByIgnition" SG_ 2617058113 SAD_TM_lin_err_count 0;
BA_ "GenSigSendType" SG_ 2617058113 SAD_TM_lin_err_count 0;
BA_ "GenSigSwitchedByIgnition" SG_ 2617058113 SAD_TM_rollo_sw_state 0;
BA_ "GenSigSendType" SG_ 2617058113 SAD_TM_rollo_sw_state 0;
BA_ "GenSigSwitchedByIgnition" SG_ 2617058113 SAD_TM_sunroof_sw_state 0;
BA_ "GenSigSendType" SG_ 2617058113 SAD_TM_sunroof_sw_state 0;
BA_ "GenSigSwitchedByIgnition" SG_ 2617058113 SAD_TM_sunroof_sw_count 0;
BA_ "GenSigSendType" SG_ 2617058113 SAD_TM_sunroof_sw_count 0;
BA_ "GenSigSwitchedByIgnition" SG_ 2617058113 SAD_TM_rollo_sw_count 0;
BA_ "GenSigSendType" SG_ 2617058113 SAD_TM_rollo_sw_count 0;
BA_ "GenSigSwitchedByIgnition" SG_ 2617058113 SAD_TM_hall_Aa 0;
BA_ "GenSigSendType" SG_ 2617058113 SAD_TM_hall_Aa 0;
BA_ "GenSigSwitchedByIgnition" SG_ 2617058113 SAD_TM_hall_Ab 0;
BA_ "GenSigSendType" SG_ 2617058113 SAD_TM_hall_Ab 0;
BA_ "GenSigSwitchedByIgnition" SG_ 2617058113 SAD_TM_hall_Ba 0;
BA_ "GenSigSendType" SG_ 2617058113 SAD_TM_hall_Ba 0;
BA_ "GenSigSwitchedByIgnition" SG_ 2617058113 SAD_TM_hall_Bb 0;
BA_ "GenSigSendType" SG_ 2617058113 SAD_TM_hall_Bb 0;
BA_ "GenSigSwitchedByIgnition" SG_ 2617058113 SAD_TM_hs_on 0;
BA_ "GenSigSendType" SG_ 2617058113 SAD_TM_hs_on 0;
BA_ "GenSigSwitchedByIgnition" SG_ 2617058113 SAD_TM_hs_stable 0;
BA_ "GenSigSendType" SG_ 2617058113 SAD_TM_hs_stable 0;
BA_ "GenSigSwitchedByIgnition" SG_ 2617058113 SAD_TM_hs_failure 0;
BA_ "GenSigSendType" SG_ 2617058113 SAD_TM_hs_failure 0;
BA_ "GenSigSwitchedByIgnition" SG_ 2617058112 SAD_TM_sunroof_sw_expected 0;
BA_ "GenSigSendType" SG_ 2617058112 SAD_TM_sunroof_sw_expected 0;
BA_ "GenSigSwitchedByIgnition" SG_ 2617058112 SAD_TM_rollo_sw_expected 0;
BA_ "GenSigSendType" SG_ 2617058112 SAD_TM_rollo_sw_expected 0;
BA_ "GenSigSendType" SG_ 2617058112 SAD_TM_l99h01_en 0;
BA_ "GenSigSwitchedByIgnition" SG_ 2617058112 SAD_TM_Mode 0;
BA_ "GenSigSendType" SG_ 2617058112 SAD_TM_Mode 0;
BA_ "GenSigSwitchedByIgnition" SG_ 2617058112 SAD_TM_lin_en 0;
BA_ "GenSigSendType" SG_ 2617058112 SAD_TM_lin_en 0;
BA_ "GenSigSwitchedByIgnition" SG_ 2617058112 SAD_TM_swil_en 0;
BA_ "GenSigSendType" SG_ 2617058112 SAD_TM_swil_en 0;
BA_ "GenSigSwitchedByIgnition" SG_ 2617058112 SAD_TM_hs_en 0;
BA_ "GenSigSendType" SG_ 2617058112 SAD_TM_hs_en 0;
BA_ "GenSigSwitchedByIgnition" SG_ 2617058112 SAD_TM_lpwm_en 0;
BA_ "GenSigSendType" SG_ 2617058112 SAD_TM_lpwm_en 0;
BA_ "GenSigSwitchedByIgnition" SG_ 2617058112 SAD_TM_sws_en 0;
BA_ "GenSigSendType" SG_ 2617058112 SAD_TM_sws_en 0;
BA_ "GenSigSwitchedByIgnition" SG_ 2617058112 SAD_TM_sws 0;
BA_ "GenSigSendType" SG_ 2617058112 SAD_TM_sws 0;
BA_ "GenSigSwitchedByIgnition" SG_ 2617058112 SAD_TM_clr_lin 0;
BA_ "GenSigSendType" SG_ 2617058112 SAD_TM_clr_lin 0;
BA_ "GenSigSwitchedByIgnition" SG_ 2617058112 SAD_TM_clr_swil_fdbk 0;
BA_ "GenSigSendType" SG_ 2617058112 SAD_TM_clr_swil_fdbk 0;
BA_ "GenSigSwitchedByIgnition" SG_ 2617058112 SAD_TM_clr_hs_fdbk 0;
BA_ "GenSigSendType" SG_ 2617058112 SAD_TM_clr_hs_fdbk 0;
BA_ "GenSigSwitchedByIgnition" SG_ 2617058112 SAD_TM_clr_lpwm_fdbk 0;
BA_ "GenSigSendType" SG_ 2617058112 SAD_TM_clr_lpwm_fdbk 0;
BA_ "GenSigSwitchedByIgnition" SG_ 2617058112 SAD_TM_clr_sw_fdbk 0;
BA_ "GenSigSendType" SG_ 2617058112 SAD_TM_clr_sw_fdbk 0;
BA_ "GenSigSwitchedByIgnition" SG_ 2617058112 SAD_TM_switch_illum 0;
BA_ "GenSigSendType" SG_ 2617058112 SAD_TM_switch_illum 0;
BA_ "GenSigSwitchedByIgnition" SG_ 2617058112 SAD_TM_hall_supply 0;
BA_ "GenSigSendType" SG_ 2617058112 SAD_TM_hall_supply 0;
BA_ "GenSigSwitchedByIgnition" SG_ 2617058112 SAD_TM_led_pwm 0;
BA_ "GenSigSendType" SG_ 2617058112 SAD_TM_led_pwm 0;
BA_ "GenSigSendType" SG_ 2617058128 SAD_PWM_SweepMin 0;
BA_ "GenSigStartValue" SG_ 2617058128 SAD_PWM_SweepMin 18000;
BA_ "GenSigSwitchedByIgnition" SG_ 2617058128 SAD_PWM_SweepMin 0;
BA_ "GenSigSendType" SG_ 2617058128 SAD_PWM_SweepMax 0;
BA_ "GenSigStartValue" SG_ 2617058128 SAD_PWM_SweepMax 20000;
BA_ "GenSigSwitchedByIgnition" SG_ 2617058128 SAD_PWM_SweepMax 0;
BA_ "GenSigSendType" SG_ 2617058128 SAD_PWM_SweepEnable 0;
BA_ "GenSigSwitchedByIgnition" SG_ 2617058128 SAD_PWM_SweepEnable 0;
BA_ "GenSigSendType" SG_ 2617058128 SAD_PWM_PWMPeriodReg 0;
BA_ "GenSigStartValue" SG_ 2617058128 SAD_PWM_PWMPeriodReg 1333;
BA_ "GenSigSwitchedByIgnition" SG_ 2617058128 SAD_PWM_PWMPeriodReg 0;
BA_ "GenSigSendType" SG_ 2617058161 SAD_L99H01_B_WDTO 0;
BA_ "GenSigSwitchedByIgnition" SG_ 2617058161 SAD_L99H01_B_WDTO 0;
BA_ "GenSigSendType" SG_ 2617058161 SAD_L99H01_B_UV 0;
BA_ "GenSigSwitchedByIgnition" SG_ 2617058161 SAD_L99H01_B_UV 0;
BA_ "GenSigSendType" SG_ 2617058161 SAD_L99H01_B_TW 0;
BA_ "GenSigSwitchedByIgnition" SG_ 2617058161 SAD_L99H01_B_TW 0;
BA_ "GenSigSendType" SG_ 2617058161 SAD_L99H01_B_TSD 0;
BA_ "GenSigSwitchedByIgnition" SG_ 2617058161 SAD_L99H01_B_TSD 0;
BA_ "GenSigSendType" SG_ 2617058161 SAD_L99H01_B_STK_RESET_Q 0;
BA_ "GenSigSwitchedByIgnition" SG_ 2617058161 SAD_L99H01_B_STK_RESET_Q 0;
BA_ "GenSigSendType" SG_ 2617058161 SAD_L99H01_B_rOT_EXT 0;
BA_ "GenSigSwitchedByIgnition" SG_ 2617058161 SAD_L99H01_B_rOT_EXT 0;
BA_ "GenSigSendType" SG_ 2617058161 SAD_L99H01_B_rDS_MON_3 0;
BA_ "GenSigSwitchedByIgnition" SG_ 2617058161 SAD_L99H01_B_rDS_MON_3 0;
BA_ "GenSigSendType" SG_ 2617058161 SAD_L99H01_B_rDS_MON_2 0;
BA_ "GenSigSwitchedByIgnition" SG_ 2617058161 SAD_L99H01_B_rDS_MON_2 0;
BA_ "GenSigSendType" SG_ 2617058161 SAD_L99H01_B_rDS_MON_1 0;
BA_ "GenSigSwitchedByIgnition" SG_ 2617058161 SAD_L99H01_B_rDS_MON_1 0;
BA_ "GenSigSendType" SG_ 2617058161 SAD_L99H01_B_rDS_MON_0 0;
BA_ "GenSigSwitchedByIgnition" SG_ 2617058161 SAD_L99H01_B_rDS_MON_0 0;
BA_ "GenSigSendType" SG_ 2617058161 SAD_L99H01_B_rCP_LOW 0;
BA_ "GenSigSwitchedByIgnition" SG_ 2617058161 SAD_L99H01_B_rCP_LOW 0;
BA_ "GenSigSendType" SG_ 2617058161 SAD_L99H01_B_OV 0;
BA_ "GenSigSwitchedByIgnition" SG_ 2617058161 SAD_L99H01_B_OV 0;
BA_ "GenSigSendType" SG_ 2617058161 SAD_L99H01_B_GL_ER 0;
BA_ "GenSigSwitchedByIgnition" SG_ 2617058161 SAD_L99H01_B_GL_ER 0;
BA_ "GenSigSendType" SG_ 2617058161 SAD_L99H01_B_FE 0;
BA_ "GenSigSwitchedByIgnition" SG_ 2617058161 SAD_L99H01_B_FE 0;
BA_ "GenSigSendType" SG_ 2617058161 SAD_L99H01_B_Error 0;
BA_ "GenSigSwitchedByIgnition" SG_ 2617058161 SAD_L99H01_B_Error 0;
BA_ "GenSigSendType" SG_ 2617058161 SAD_L99H01_B_State 0;
BA_ "GenSigSwitchedByIgnition" SG_ 2617058161 SAD_L99H01_B_State 0;
BA_ "GenSigSendType" SG_ 2617058161 SAD_L99H01_B_SC2GND 0;
BA_ "GenSigSwitchedByIgnition" SG_ 2617058161 SAD_L99H01_B_SC2GND 0;
BA_ "GenSigSendType" SG_ 2617058161 SAD_L99H01_B_SC2BAT_LS 0;
BA_ "GenSigSwitchedByIgnition" SG_ 2617058161 SAD_L99H01_B_SC2BAT_LS 0;
BA_ "GenSigSendType" SG_ 2617058161 SAD_L99H01_B_SC2BAT_HS 0;
BA_ "GenSigSwitchedByIgnition" SG_ 2617058161 SAD_L99H01_B_SC2BAT_HS 0;
BA_ "GenSigSendType" SG_ 2617058160 SAD_L99H01_B_EnableFdbkMon 0;
BA_ "GenSigSwitchedByIgnition" SG_ 2617058160 SAD_L99H01_B_EnableFdbkMon 0;
BA_ "GenSigSendType" SG_ 2617058160 SAD_L99H01_B_DirSwitchTime 0;
BA_ "GenSigStartValue" SG_ 2617058160 SAD_L99H01_B_DirSwitchTime 2;
BA_ "GenSigSwitchedByIgnition" SG_ 2617058160 SAD_L99H01_B_DirSwitchTime 0;
BA_ "GenSigSendType" SG_ 2617058160 SAD_L99H01_B_OVT 0;
BA_ "GenSigSwitchedByIgnition" SG_ 2617058160 SAD_L99H01_B_OVT 0;
BA_ "GenSigSendType" SG_ 2617058160 SAD_L99H01_B_OV_UV_RD 0;
BA_ "GenSigSwitchedByIgnition" SG_ 2617058160 SAD_L99H01_B_OV_UV_RD 0;
BA_ "GenSigSendType" SG_ 2617058160 SAD_L99H01_B_OFF_CAL 0;
BA_ "GenSigSwitchedByIgnition" SG_ 2617058160 SAD_L99H01_B_OFF_CAL 0;
BA_ "GenSigSendType" SG_ 2617058160 SAD_L99H01_B_FW_PAS 0;
BA_ "GenSigSwitchedByIgnition" SG_ 2617058160 SAD_L99H01_B_FW_PAS 0;
BA_ "GenSigSendType" SG_ 2617058160 SAD_L99H01_B_FW 0;
BA_ "GenSigSwitchedByIgnition" SG_ 2617058160 SAD_L99H01_B_FW 0;
BA_ "GenSigSendType" SG_ 2617058160 SAD_L99H01_B_EXT_TS 0;
BA_ "GenSigStartValue" SG_ 2617058160 SAD_L99H01_B_EXT_TS 1;
BA_ "GenSigSwitchedByIgnition" SG_ 2617058160 SAD_L99H01_B_EXT_TS 0;
BA_ "GenSigSendType" SG_ 2617058160 SAD_L99H01_B_ENABLE 0;
BA_ "GenSigSwitchedByIgnition" SG_ 2617058160 SAD_L99H01_B_ENABLE 0;
BA_ "GenSigSendType" SG_ 2617058160 SAD_L99H01_B_DIR 0;
BA_ "GenSigSwitchedByIgnition" SG_ 2617058160 SAD_L99H01_B_DIR 0;
BA_ "GenSigSendType" SG_ 2617058160 SAD_L99H01_B_CLR_STAT 0;
BA_ "GenSigSwitchedByIgnition" SG_ 2617058160 SAD_L99H01_B_CLR_STAT 0;
BA_ "GenSigSendType" SG_ 2617058160 SAD_L99H01_B_CLK_SPCTR 0;
BA_ "GenSigStartValue" SG_ 2617058160 SAD_L99H01_B_CLK_SPCTR 1;
BA_ "GenSigSwitchedByIgnition" SG_ 2617058160 SAD_L99H01_B_CLK_SPCTR 0;
BA_ "GenSigSendType" SG_ 2617058160 SAD_L99H01_B_EXTTH_n 0;
BA_ "GenSigStartValue" SG_ 2617058160 SAD_L99H01_B_EXTTH_n 4;
BA_ "GenSigSwitchedByIgnition" SG_ 2617058160 SAD_L99H01_B_EXTTH_n 0;
BA_ "GenSigSendType" SG_ 2617058160 SAD_L99H01_B_DIAG 0;
BA_ "GenSigSwitchedByIgnition" SG_ 2617058160 SAD_L99H01_B_DIAG 0;
BA_ "GenSigSendType" SG_ 2617058160 SAD_L99H01_B_EXTTH_m 0;
BA_ "GenSigStartValue" SG_ 2617058160 SAD_L99H01_B_EXTTH_m 6;
BA_ "GenSigSwitchedByIgnition" SG_ 2617058160 SAD_L99H01_B_EXTTH_m 0;
BA_ "GenSigSendType" SG_ 2617058160 SAD_L99H01_B_COPT 0;
BA_ "GenSigStartValue" SG_ 2617058160 SAD_L99H01_B_COPT 3;
BA_ "GenSigSwitchedByIgnition" SG_ 2617058160 SAD_L99H01_B_COPT 0;
BA_ "GenSigSendType" SG_ 2617058160 SAD_L99H01_B_PWM 0;
BA_ "GenSigSwitchedByIgnition" SG_ 2617058160 SAD_L99H01_B_PWM 0;
BA_ "GenSigSendType" SG_ 2617058145 SAD_L99H01_A_WDTO 0;
BA_ "GenSigSwitchedByIgnition" SG_ 2617058145 SAD_L99H01_A_WDTO 0;
BA_ "GenSigSendType" SG_ 2617058145 SAD_L99H01_A_UV 0;
BA_ "GenSigSwitchedByIgnition" SG_ 2617058145 SAD_L99H01_A_UV 0;
BA_ "GenSigSendType" SG_ 2617058145 SAD_L99H01_A_TW 0;
BA_ "GenSigSwitchedByIgnition" SG_ 2617058145 SAD_L99H01_A_TW 0;
BA_ "GenSigSendType" SG_ 2617058145 SAD_L99H01_A_TSD 0;
BA_ "GenSigSwitchedByIgnition" SG_ 2617058145 SAD_L99H01_A_TSD 0;
BA_ "GenSigSendType" SG_ 2617058145 SAD_L99H01_A_STK_RESET_Q 0;
BA_ "GenSigSwitchedByIgnition" SG_ 2617058145 SAD_L99H01_A_STK_RESET_Q 0;
BA_ "GenSigSendType" SG_ 2617058145 SAD_L99H01_A_rOT_EXT 0;
BA_ "GenSigSwitchedByIgnition" SG_ 2617058145 SAD_L99H01_A_rOT_EXT 0;
BA_ "GenSigSendType" SG_ 2617058145 SAD_L99H01_A_rDS_MON_3 0;
BA_ "GenSigSwitchedByIgnition" SG_ 2617058145 SAD_L99H01_A_rDS_MON_3 0;
BA_ "GenSigSendType" SG_ 2617058145 SAD_L99H01_A_rDS_MON_2 0;
BA_ "GenSigSwitchedByIgnition" SG_ 2617058145 SAD_L99H01_A_rDS_MON_2 0;
BA_ "GenSigSendType" SG_ 2617058145 SAD_L99H01_A_rDS_MON_1 0;
BA_ "GenSigSwitchedByIgnition" SG_ 2617058145 SAD_L99H01_A_rDS_MON_1 0;
BA_ "GenSigSendType" SG_ 2617058145 SAD_L99H01_A_rDS_MON_0 0;
BA_ "GenSigSwitchedByIgnition" SG_ 2617058145 SAD_L99H01_A_rDS_MON_0 0;
BA_ "GenSigSendType" SG_ 2617058145 SAD_L99H01_A_rCP_LOW 0;
BA_ "GenSigSwitchedByIgnition" SG_ 2617058145 SAD_L99H01_A_rCP_LOW 0;
BA_ "GenSigSendType" SG_ 2617058145 SAD_L99H01_A_OV 0;
BA_ "GenSigSwitchedByIgnition" SG_ 2617058145 SAD_L99H01_A_OV 0;
BA_ "GenSigSendType" SG_ 2617058145 SAD_L99H01_A_GL_ER 0;
BA_ "GenSigSwitchedByIgnition" SG_ 2617058145 SAD_L99H01_A_GL_ER 0;
BA_ "GenSigSendType" SG_ 2617058145 SAD_L99H01_A_FE 0;
BA_ "GenSigSwitchedByIgnition" SG_ 2617058145 SAD_L99H01_A_FE 0;
BA_ "GenSigSendType" SG_ 2617058145 SAD_L99H01_A_Error 0;
BA_ "GenSigSwitchedByIgnition" SG_ 2617058145 SAD_L99H01_A_Error 0;
BA_ "GenSigSendType" SG_ 2617058145 SAD_L99H01_A_State 0;
BA_ "GenSigSwitchedByIgnition" SG_ 2617058145 SAD_L99H01_A_State 0;
BA_ "GenSigSendType" SG_ 2617058145 SAD_L99H01_A_SC2GND 0;
BA_ "GenSigSwitchedByIgnition" SG_ 2617058145 SAD_L99H01_A_SC2GND 0;
BA_ "GenSigSendType" SG_ 2617058145 SAD_L99H01_A_SC2BAT_LS 0;
BA_ "GenSigSwitchedByIgnition" SG_ 2617058145 SAD_L99H01_A_SC2BAT_LS 0;
BA_ "GenSigSendType" SG_ 2617058145 SAD_L99H01_A_SC2BAT_HS 0;
BA_ "GenSigSwitchedByIgnition" SG_ 2617058145 SAD_L99H01_A_SC2BAT_HS 0;
BA_ "GenSigSendType" SG_ 2617058144 SAD_L99H01_A_EnableFdbkMon 0;
BA_ "GenSigSwitchedByIgnition" SG_ 2617058144 SAD_L99H01_A_EnableFdbkMon 0;
BA_ "GenSigSendType" SG_ 2617058144 SAD_L99H01_A_DirSwitchTime 0;
BA_ "GenSigStartValue" SG_ 2617058144 SAD_L99H01_A_DirSwitchTime 2;
BA_ "GenSigSwitchedByIgnition" SG_ 2617058144 SAD_L99H01_A_DirSwitchTime 0;
BA_ "GenSigSendType" SG_ 2617058144 SAD_L99H01_A_OVT 0;
BA_ "GenSigSwitchedByIgnition" SG_ 2617058144 SAD_L99H01_A_OVT 0;
BA_ "GenSigSendType" SG_ 2617058144 SAD_L99H01_A_OV_UV_RD 0;
BA_ "GenSigSwitchedByIgnition" SG_ 2617058144 SAD_L99H01_A_OV_UV_RD 0;
BA_ "GenSigSendType" SG_ 2617058144 SAD_L99H01_A_OFF_CAL 0;
BA_ "GenSigSwitchedByIgnition" SG_ 2617058144 SAD_L99H01_A_OFF_CAL 0;
BA_ "GenSigSendType" SG_ 2617058144 SAD_L99H01_A_FW_PAS 0;
BA_ "GenSigSwitchedByIgnition" SG_ 2617058144 SAD_L99H01_A_FW_PAS 0;
BA_ "GenSigSendType" SG_ 2617058144 SAD_L99H01_A_FW 0;
BA_ "GenSigSwitchedByIgnition" SG_ 2617058144 SAD_L99H01_A_FW 0;
BA_ "GenSigSendType" SG_ 2617058144 SAD_L99H01_A_EXT_TS 0;
BA_ "GenSigStartValue" SG_ 2617058144 SAD_L99H01_A_EXT_TS 1;
BA_ "GenSigSwitchedByIgnition" SG_ 2617058144 SAD_L99H01_A_EXT_TS 0;
BA_ "GenSigSendType" SG_ 2617058144 SAD_L99H01_A_ENABLE 0;
BA_ "GenSigSwitchedByIgnition" SG_ 2617058144 SAD_L99H01_A_ENABLE 0;
BA_ "GenSigSendType" SG_ 2617058144 SAD_L99H01_A_DIR 0;
BA_ "GenSigSwitchedByIgnition" SG_ 2617058144 SAD_L99H01_A_DIR 0;
BA_ "GenSigSendType" SG_ 2617058144 SAD_L99H01_A_CLR_STAT 0;
BA_ "GenSigSwitchedByIgnition" SG_ 2617058144 SAD_L99H01_A_CLR_STAT 0;
BA_ "GenSigSendType" SG_ 2617058144 SAD_L99H01_A_CLK_SPCTR 0;
BA_ "GenSigStartValue" SG_ 2617058144 SAD_L99H01_A_CLK_SPCTR 1;
BA_ "GenSigSwitchedByIgnition" SG_ 2617058144 SAD_L99H01_A_CLK_SPCTR 0;
BA_ "GenSigSendType" SG_ 2617058144 SAD_L99H01_A_EXTTH_n 0;
BA_ "GenSigStartValue" SG_ 2617058144 SAD_L99H01_A_EXTTH_n 4;
BA_ "GenSigSwitchedByIgnition" SG_ 2617058144 SAD_L99H01_A_EXTTH_n 0;
BA_ "GenSigSendType" SG_ 2617058144 SAD_L99H01_A_DIAG 0;
BA_ "GenSigSwitchedByIgnition" SG_ 2617058144 SAD_L99H01_A_DIAG 0;
BA_ "GenSigSendType" SG_ 2617058144 SAD_L99H01_A_EXTTH_m 0;
BA_ "GenSigStartValue" SG_ 2617058144 SAD_L99H01_A_EXTTH_m 6;
BA_ "GenSigSwitchedByIgnition" SG_ 2617058144 SAD_L99H01_A_EXTTH_m 0;
BA_ "GenSigSendType" SG_ 2617058144 SAD_L99H01_A_COPT 0;
BA_ "GenSigStartValue" SG_ 2617058144 SAD_L99H01_A_COPT 3;
BA_ "GenSigSwitchedByIgnition" SG_ 2617058144 SAD_L99H01_A_COPT 0;
BA_ "GenSigSendType" SG_ 2617058144 SAD_L99H01_A_PWM 0;
BA_ "GenSigSwitchedByIgnition" SG_ 2617058144 SAD_L99H01_A_PWM 0;
BA_ "GenSigSendType" SG_ 2617058116 SAD_ADC_Switch_REF_Sense_3_4 0;
BA_ "GenSigSwitchedByIgnition" SG_ 2617058116 SAD_ADC_Switch_REF_Sense_3_4 0;
BA_ "GenSigSendType" SG_ 2617058116 SAD_ADC_LED_Supply_Sense 0;
BA_ "GenSigSwitchedByIgnition" SG_ 2617058116 SAD_ADC_LED_Supply_Sense 0;
BA_ "GenSigSendType" SG_ 2617058116 SAD_ADC_Temp_Sense 0;
BA_ "GenSigSwitchedByIgnition" SG_ 2617058116 SAD_ADC_Temp_Sense 0;
BA_ "GenSigSendType" SG_ 2617058116 SAD_ADC_Switch_REF_Sense_1_2 0;
BA_ "GenSigSwitchedByIgnition" SG_ 2617058116 SAD_ADC_Switch_REF_Sense_1_2 0;
BA_ "GenSigSendType" SG_ 2617058116 SAD_ADC_Switch_Illum_Sense 0;
BA_ "GenSigSwitchedByIgnition" SG_ 2617058116 SAD_ADC_Switch_Illum_Sense 0;
BA_ "GenSigSendType" SG_ 2617058116 SAD_ADC_KL30_Sense 0;
BA_ "GenSigSwitchedByIgnition" SG_ 2617058116 SAD_ADC_KL30_Sense 0;
BA_ "GenSigSendType" SG_ 2617058116 SAD_ADC_Hall_Supply_Sense 0;
BA_ "GenSigSwitchedByIgnition" SG_ 2617058116 SAD_ADC_Hall_Supply_Sense 0;
BA_ "GenSigSendType" SG_ 2617058114 SAD_ADC_Switch_4 0;
BA_ "GenSigSwitchedByIgnition" SG_ 2617058114 SAD_ADC_Switch_4 0;
BA_ "GenSigSendType" SG_ 2617058114 SAD_ADC_Switch_3 0;
BA_ "GenSigSwitchedByIgnition" SG_ 2617058114 SAD_ADC_Switch_3 0;
BA_ "GenSigSendType" SG_ 2617058114 SAD_ADC_Switch_2 0;
BA_ "GenSigSwitchedByIgnition" SG_ 2617058114 SAD_ADC_Switch_2 0;
BA_ "GenSigSendType" SG_ 2617058114 SAD_ADC_Switch_1 0;
BA_ "GenSigSwitchedByIgnition" SG_ 2617058114 SAD_ADC_Switch_1 0;
BA_ "GenSigSendType" SG_ 2617058114 SAD_ADC_Motor_B_Sense_b 0;
BA_ "GenSigSwitchedByIgnition" SG_ 2617058114 SAD_ADC_Motor_B_Sense_b 0;
BA_ "GenSigSendType" SG_ 2617058114 SAD_ADC_Motor_B_Sense_a 0;
BA_ "GenSigSwitchedByIgnition" SG_ 2617058114 SAD_ADC_Motor_B_Sense_a 0;
BA_ "GenSigSendType" SG_ 2617058114 SAD_ADC_Motor_A_Sense_b 0;
BA_ "GenSigSwitchedByIgnition" SG_ 2617058114 SAD_ADC_Motor_A_Sense_b 0;
BA_ "GenSigSendType" SG_ 2617058114 SAD_ADC_Motor_A_Sense_a 0;
BA_ "GenSigSwitchedByIgnition" SG_ 2617058114 SAD_ADC_Motor_A_Sense_a 0;
BA_ "GenSigSwitchedByIgnition" SG_ 2616992577 SAD_TM_lin_err_count 0;
BA_ "GenSigSendType" SG_ 2616992577 SAD_TM_lin_err_count 0;
BA_ "GenSigSwitchedByIgnition" SG_ 2616992577 SAD_TM_rollo_sw_state 0;
BA_ "GenSigSendType" SG_ 2616992577 SAD_TM_rollo_sw_state 0;
BA_ "GenSigSwitchedByIgnition" SG_ 2616992577 SAD_TM_sunroof_sw_state 0;
BA_ "GenSigSendType" SG_ 2616992577 SAD_TM_sunroof_sw_state 0;
BA_ "GenSigSwitchedByIgnition" SG_ 2616992577 SAD_TM_sunroof_sw_count 0;
BA_ "GenSigSendType" SG_ 2616992577 SAD_TM_sunroof_sw_count 0;
BA_ "GenSigSwitchedByIgnition" SG_ 2616992577 SAD_TM_rollo_sw_count 0;
BA_ "GenSigSendType" SG_ 2616992577 SAD_TM_rollo_sw_count 0;
BA_ "GenSigSwitchedByIgnition" SG_ 2616992577 SAD_TM_hall_Aa 0;
BA_ "GenSigSendType" SG_ 2616992577 SAD_TM_hall_Aa 0;
BA_ "GenSigSwitchedByIgnition" SG_ 2616992577 SAD_TM_hall_Ab 0;
BA_ "GenSigSendType" SG_ 2616992577 SAD_TM_hall_Ab 0;
BA_ "GenSigSwitchedByIgnition" SG_ 2616992577 SAD_TM_hall_Ba 0;
BA_ "GenSigSendType" SG_ 2616992577 SAD_TM_hall_Ba 0;
BA_ "GenSigSwitchedByIgnition" SG_ 2616992577 SAD_TM_hall_Bb 0;
BA_ "GenSigSendType" SG_ 2616992577 SAD_TM_hall_Bb 0;
BA_ "GenSigSwitchedByIgnition" SG_ 2616992577 SAD_TM_hs_on 0;
BA_ "GenSigSendType" SG_ 2616992577 SAD_TM_hs_on 0;
BA_ "GenSigSwitchedByIgnition" SG_ 2616992577 SAD_TM_hs_stable 0;
BA_ "GenSigSendType" SG_ 2616992577 SAD_TM_hs_stable 0;
BA_ "GenSigSwitchedByIgnition" SG_ 2616992577 SAD_TM_hs_failure 0;
BA_ "GenSigSendType" SG_ 2616992577 SAD_TM_hs_failure 0;
BA_ "GenSigSendType" SG_ 2616992592 SAD_PWM_SweepMin 0;
BA_ "GenSigStartValue" SG_ 2616992592 SAD_PWM_SweepMin 18000;
BA_ "GenSigSwitchedByIgnition" SG_ 2616992592 SAD_PWM_SweepMin 0;
BA_ "GenSigSendType" SG_ 2616992592 SAD_PWM_SweepMax 0;
BA_ "GenSigStartValue" SG_ 2616992592 SAD_PWM_SweepMax 20000;
BA_ "GenSigSwitchedByIgnition" SG_ 2616992592 SAD_PWM_SweepMax 0;
BA_ "GenSigSendType" SG_ 2616992592 SAD_PWM_SweepEnable 0;
BA_ "GenSigSwitchedByIgnition" SG_ 2616992592 SAD_PWM_SweepEnable 0;
BA_ "GenSigSendType" SG_ 2616992592 SAD_PWM_PWMPeriodReg 0;
BA_ "GenSigStartValue" SG_ 2616992592 SAD_PWM_PWMPeriodReg 1333;
BA_ "GenSigSwitchedByIgnition" SG_ 2616992592 SAD_PWM_PWMPeriodReg 0;
BA_ "GenSigSwitchedByIgnition" SG_ 2616992576 SAD_TM_sunroof_sw_expected 0;
BA_ "GenSigSendType" SG_ 2616992576 SAD_TM_sunroof_sw_expected 0;
BA_ "GenSigSwitchedByIgnition" SG_ 2616992576 SAD_TM_rollo_sw_expected 0;
BA_ "GenSigSendType" SG_ 2616992576 SAD_TM_rollo_sw_expected 0;
BA_ "GenSigSendType" SG_ 2616992576 SAD_TM_l99h01_en 0;
BA_ "GenSigSwitchedByIgnition" SG_ 2616992576 SAD_TM_Mode 0;
BA_ "GenSigSendType" SG_ 2616992576 SAD_TM_Mode 0;
BA_ "GenSigSwitchedByIgnition" SG_ 2616992576 SAD_TM_lin_en 0;
BA_ "GenSigSendType" SG_ 2616992576 SAD_TM_lin_en 0;
BA_ "GenSigSwitchedByIgnition" SG_ 2616992576 SAD_TM_swil_en 0;
BA_ "GenSigSendType" SG_ 2616992576 SAD_TM_swil_en 0;
BA_ "GenSigSwitchedByIgnition" SG_ 2616992576 SAD_TM_hs_en 0;
BA_ "GenSigSendType" SG_ 2616992576 SAD_TM_hs_en 0;
BA_ "GenSigSwitchedByIgnition" SG_ 2616992576 SAD_TM_lpwm_en 0;
BA_ "GenSigSendType" SG_ 2616992576 SAD_TM_lpwm_en 0;
BA_ "GenSigSwitchedByIgnition" SG_ 2616992576 SAD_TM_sws_en 0;
BA_ "GenSigSendType" SG_ 2616992576 SAD_TM_sws_en 0;
BA_ "GenSigSwitchedByIgnition" SG_ 2616992576 SAD_TM_sws 0;
BA_ "GenSigSendType" SG_ 2616992576 SAD_TM_sws 0;
BA_ "GenSigSwitchedByIgnition" SG_ 2616992576 SAD_TM_clr_lin 0;
BA_ "GenSigSendType" SG_ 2616992576 SAD_TM_clr_lin 0;
BA_ "GenSigSwitchedByIgnition" SG_ 2616992576 SAD_TM_clr_swil_fdbk 0;
BA_ "GenSigSendType" SG_ 2616992576 SAD_TM_clr_swil_fdbk 0;
BA_ "GenSigSwitchedByIgnition" SG_ 2616992576 SAD_TM_clr_hs_fdbk 0;
BA_ "GenSigSendType" SG_ 2616992576 SAD_TM_clr_hs_fdbk 0;
BA_ "GenSigSwitchedByIgnition" SG_ 2616992576 SAD_TM_clr_lpwm_fdbk 0;
BA_ "GenSigSendType" SG_ 2616992576 SAD_TM_clr_lpwm_fdbk 0;
BA_ "GenSigSwitchedByIgnition" SG_ 2616992576 SAD_TM_clr_sw_fdbk 0;
BA_ "GenSigSendType" SG_ 2616992576 SAD_TM_clr_sw_fdbk 0;
BA_ "GenSigSwitchedByIgnition" SG_ 2616992576 SAD_TM_switch_illum 0;
BA_ "GenSigSendType" SG_ 2616992576 SAD_TM_switch_illum 0;
BA_ "GenSigSwitchedByIgnition" SG_ 2616992576 SAD_TM_hall_supply 0;
BA_ "GenSigSendType" SG_ 2616992576 SAD_TM_hall_supply 0;
BA_ "GenSigSwitchedByIgnition" SG_ 2616992576 SAD_TM_led_pwm 0;
BA_ "GenSigSendType" SG_ 2616992576 SAD_TM_led_pwm 0;
BA_ "GenSigSendType" SG_ 2616992580 SAD_ADC_Switch_REF_Sense_3_4 0;
BA_ "GenSigSwitchedByIgnition" SG_ 2616992580 SAD_ADC_Switch_REF_Sense_3_4 0;
BA_ "GenSigSendType" SG_ 2616992580 SAD_ADC_LED_Supply_Sense 0;
BA_ "GenSigSwitchedByIgnition" SG_ 2616992580 SAD_ADC_LED_Supply_Sense 0;
BA_ "GenSigSendType" SG_ 2616992580 SAD_ADC_Temp_Sense 0;
BA_ "GenSigSwitchedByIgnition" SG_ 2616992580 SAD_ADC_Temp_Sense 0;
BA_ "GenSigSendType" SG_ 2616992580 SAD_ADC_Switch_REF_Sense_1_2 0;
BA_ "GenSigSwitchedByIgnition" SG_ 2616992580 SAD_ADC_Switch_REF_Sense_1_2 0;
BA_ "GenSigSendType" SG_ 2616992580 SAD_ADC_Switch_Illum_Sense 0;
BA_ "GenSigSwitchedByIgnition" SG_ 2616992580 SAD_ADC_Switch_Illum_Sense 0;
BA_ "GenSigSendType" SG_ 2616992580 SAD_ADC_KL30_Sense 0;
BA_ "GenSigSwitchedByIgnition" SG_ 2616992580 SAD_ADC_KL30_Sense 0;
BA_ "GenSigSendType" SG_ 2616992580 SAD_ADC_Hall_Supply_Sense 0;
BA_ "GenSigSwitchedByIgnition" SG_ 2616992580 SAD_ADC_Hall_Supply_Sense 0;
BA_ "GenSigSendType" SG_ 2616992578 SAD_ADC_Switch_4 0;
BA_ "GenSigSwitchedByIgnition" SG_ 2616992578 SAD_ADC_Switch_4 0;
BA_ "GenSigSendType" SG_ 2616992578 SAD_ADC_Switch_3 0;
BA_ "GenSigSwitchedByIgnition" SG_ 2616992578 SAD_ADC_Switch_3 0;
BA_ "GenSigSendType" SG_ 2616992578 SAD_ADC_Switch_2 0;
BA_ "GenSigSwitchedByIgnition" SG_ 2616992578 SAD_ADC_Switch_2 0;
BA_ "GenSigSendType" SG_ 2616992578 SAD_ADC_Switch_1 0;
BA_ "GenSigSwitchedByIgnition" SG_ 2616992578 SAD_ADC_Switch_1 0;
BA_ "GenSigSendType" SG_ 2616992578 SAD_ADC_Motor_B_Sense_b 0;
BA_ "GenSigSwitchedByIgnition" SG_ 2616992578 SAD_ADC_Motor_B_Sense_b 0;
BA_ "GenSigSendType" SG_ 2616992578 SAD_ADC_Motor_B_Sense_a 0;
BA_ "GenSigSwitchedByIgnition" SG_ 2616992578 SAD_ADC_Motor_B_Sense_a 0;
BA_ "GenSigSendType" SG_ 2616992578 SAD_ADC_Motor_A_Sense_b 0;
BA_ "GenSigSwitchedByIgnition" SG_ 2616992578 SAD_ADC_Motor_A_Sense_b 0;
BA_ "GenSigSendType" SG_ 2616992578 SAD_ADC_Motor_A_Sense_a 0;
BA_ "GenSigSwitchedByIgnition" SG_ 2616992578 SAD_ADC_Motor_A_Sense_a 0;
BA_ "GenSigSendType" SG_ 2616992624 SAD_L99H01_B_EnableFdbkMon 0;
BA_ "GenSigSwitchedByIgnition" SG_ 2616992624 SAD_L99H01_B_EnableFdbkMon 0;
BA_ "GenSigSendType" SG_ 2616992624 SAD_L99H01_B_DirSwitchTime 0;
BA_ "GenSigStartValue" SG_ 2616992624 SAD_L99H01_B_DirSwitchTime 2;
BA_ "GenSigSwitchedByIgnition" SG_ 2616992624 SAD_L99H01_B_DirSwitchTime 0;
BA_ "GenSigSendType" SG_ 2616992624 SAD_L99H01_B_OVT 0;
BA_ "GenSigSwitchedByIgnition" SG_ 2616992624 SAD_L99H01_B_OVT 0;
BA_ "GenSigSendType" SG_ 2616992624 SAD_L99H01_B_OV_UV_RD 0;
BA_ "GenSigSwitchedByIgnition" SG_ 2616992624 SAD_L99H01_B_OV_UV_RD 0;
BA_ "GenSigSendType" SG_ 2616992624 SAD_L99H01_B_OFF_CAL 0;
BA_ "GenSigSwitchedByIgnition" SG_ 2616992624 SAD_L99H01_B_OFF_CAL 0;
BA_ "GenSigSendType" SG_ 2616992624 SAD_L99H01_B_FW_PAS 0;
BA_ "GenSigSwitchedByIgnition" SG_ 2616992624 SAD_L99H01_B_FW_PAS 0;
BA_ "GenSigSendType" SG_ 2616992624 SAD_L99H01_B_FW 0;
BA_ "GenSigSwitchedByIgnition" SG_ 2616992624 SAD_L99H01_B_FW 0;
BA_ "GenSigSendType" SG_ 2616992624 SAD_L99H01_B_EXT_TS 0;
BA_ "GenSigStartValue" SG_ 2616992624 SAD_L99H01_B_EXT_TS 1;
BA_ "GenSigSwitchedByIgnition" SG_ 2616992624 SAD_L99H01_B_EXT_TS 0;
BA_ "GenSigSendType" SG_ 2616992624 SAD_L99H01_B_ENABLE 0;
BA_ "GenSigSwitchedByIgnition" SG_ 2616992624 SAD_L99H01_B_ENABLE 0;
BA_ "GenSigSendType" SG_ 2616992624 SAD_L99H01_B_DIR 0;
BA_ "GenSigSwitchedByIgnition" SG_ 2616992624 SAD_L99H01_B_DIR 0;
BA_ "GenSigSendType" SG_ 2616992624 SAD_L99H01_B_CLR_STAT 0;
BA_ "GenSigSwitchedByIgnition" SG_ 2616992624 SAD_L99H01_B_CLR_STAT 0;
BA_ "GenSigSendType" SG_ 2616992624 SAD_L99H01_B_CLK_SPCTR 0;
BA_ "GenSigStartValue" SG_ 2616992624 SAD_L99H01_B_CLK_SPCTR 1;
BA_ "GenSigSwitchedByIgnition" SG_ 2616992624 SAD_L99H01_B_CLK_SPCTR 0;
BA_ "GenSigSendType" SG_ 2616992624 SAD_L99H01_B_EXTTH_n 0;
BA_ "GenSigStartValue" SG_ 2616992624 SAD_L99H01_B_EXTTH_n 4;
BA_ "GenSigSwitchedByIgnition" SG_ 2616992624 SAD_L99H01_B_EXTTH_n 0;
BA_ "GenSigSendType" SG_ 2616992624 SAD_L99H01_B_DIAG 0;
BA_ "GenSigSwitchedByIgnition" SG_ 2616992624 SAD_L99H01_B_DIAG 0;
BA_ "GenSigSendType" SG_ 2616992624 SAD_L99H01_B_EXTTH_m 0;
BA_ "GenSigStartValue" SG_ 2616992624 SAD_L99H01_B_EXTTH_m 6;
BA_ "GenSigSwitchedByIgnition" SG_ 2616992624 SAD_L99H01_B_EXTTH_m 0;
BA_ "GenSigSendType" SG_ 2616992624 SAD_L99H01_B_COPT 0;
BA_ "GenSigStartValue" SG_ 2616992624 SAD_L99H01_B_COPT 3;
BA_ "GenSigSwitchedByIgnition" SG_ 2616992624 SAD_L99H01_B_COPT 0;
BA_ "GenSigSendType" SG_ 2616992624 SAD_L99H01_B_PWM 0;
BA_ "GenSigSwitchedByIgnition" SG_ 2616992624 SAD_L99H01_B_PWM 0;
BA_ "GenSigSendType" SG_ 2616992608 SAD_L99H01_A_EnableFdbkMon 0;
BA_ "GenSigSwitchedByIgnition" SG_ 2616992608 SAD_L99H01_A_EnableFdbkMon 0;
BA_ "GenSigSendType" SG_ 2616992608 SAD_L99H01_A_DirSwitchTime 0;
BA_ "GenSigStartValue" SG_ 2616992608 SAD_L99H01_A_DirSwitchTime 2;
BA_ "GenSigSwitchedByIgnition" SG_ 2616992608 SAD_L99H01_A_DirSwitchTime 0;
BA_ "GenSigSendType" SG_ 2616992608 SAD_L99H01_A_OVT 0;
BA_ "GenSigSwitchedByIgnition" SG_ 2616992608 SAD_L99H01_A_OVT 0;
BA_ "GenSigSendType" SG_ 2616992608 SAD_L99H01_A_OV_UV_RD 0;
BA_ "GenSigSwitchedByIgnition" SG_ 2616992608 SAD_L99H01_A_OV_UV_RD 0;
BA_ "GenSigSendType" SG_ 2616992608 SAD_L99H01_A_OFF_CAL 0;
BA_ "GenSigSwitchedByIgnition" SG_ 2616992608 SAD_L99H01_A_OFF_CAL 0;
BA_ "GenSigSendType" SG_ 2616992608 SAD_L99H01_A_FW_PAS 0;
BA_ "GenSigSwitchedByIgnition" SG_ 2616992608 SAD_L99H01_A_FW_PAS 0;
BA_ "GenSigSendType" SG_ 2616992608 SAD_L99H01_A_FW 0;
BA_ "GenSigSwitchedByIgnition" SG_ 2616992608 SAD_L99H01_A_FW 0;
BA_ "GenSigSendType" SG_ 2616992608 SAD_L99H01_A_EXT_TS 0;
BA_ "GenSigStartValue" SG_ 2616992608 SAD_L99H01_A_EXT_TS 1;
BA_ "GenSigSwitchedByIgnition" SG_ 2616992608 SAD_L99H01_A_EXT_TS 0;
BA_ "GenSigSendType" SG_ 2616992608 SAD_L99H01_A_ENABLE 0;
BA_ "GenSigSwitchedByIgnition" SG_ 2616992608 SAD_L99H01_A_ENABLE 0;
BA_ "GenSigSendType" SG_ 2616992608 SAD_L99H01_A_DIR 0;
BA_ "GenSigSwitchedByIgnition" SG_ 2616992608 SAD_L99H01_A_DIR 0;
BA_ "GenSigSendType" SG_ 2616992608 SAD_L99H01_A_CLR_STAT 0;
BA_ "GenSigSwitchedByIgnition" SG_ 2616992608 SAD_L99H01_A_CLR_STAT 0;
BA_ "GenSigSendType" SG_ 2616992608 SAD_L99H01_A_CLK_SPCTR 0;
BA_ "GenSigStartValue" SG_ 2616992608 SAD_L99H01_A_CLK_SPCTR 1;
BA_ "GenSigSwitchedByIgnition" SG_ 2616992608 SAD_L99H01_A_CLK_SPCTR 0;
BA_ "GenSigSendType" SG_ 2616992608 SAD_L99H01_A_EXTTH_n 0;
BA_ "GenSigStartValue" SG_ 2616992608 SAD_L99H01_A_EXTTH_n 4;
BA_ "GenSigSwitchedByIgnition" SG_ 2616992608 SAD_L99H01_A_EXTTH_n 0;
BA_ "GenSigSendType" SG_ 2616992608 SAD_L99H01_A_DIAG 0;
BA_ "GenSigSwitchedByIgnition" SG_ 2616992608 SAD_L99H01_A_DIAG 0;
BA_ "GenSigSendType" SG_ 2616992608 SAD_L99H01_A_EXTTH_m 0;
BA_ "GenSigStartValue" SG_ 2616992608 SAD_L99H01_A_EXTTH_m 6;
BA_ "GenSigSwitchedByIgnition" SG_ 2616992608 SAD_L99H01_A_EXTTH_m 0;
BA_ "GenSigSendType" SG_ 2616992608 SAD_L99H01_A_COPT 0;
BA_ "GenSigStartValue" SG_ 2616992608 SAD_L99H01_A_COPT 3;
BA_ "GenSigSwitchedByIgnition" SG_ 2616992608 SAD_L99H01_A_COPT 0;
BA_ "GenSigSendType" SG_ 2616992608 SAD_L99H01_A_PWM 0;
BA_ "GenSigSwitchedByIgnition" SG_ 2616992608 SAD_L99H01_A_PWM 0;
BA_ "GenSigSendType" SG_ 2616992625 SAD_L99H01_B_WDTO 0;
BA_ "GenSigSwitchedByIgnition" SG_ 2616992625 SAD_L99H01_B_WDTO 0;
BA_ "GenSigSendType" SG_ 2616992625 SAD_L99H01_B_UV 0;
BA_ "GenSigSwitchedByIgnition" SG_ 2616992625 SAD_L99H01_B_UV 0;
BA_ "GenSigSendType" SG_ 2616992625 SAD_L99H01_B_TW 0;
BA_ "GenSigSwitchedByIgnition" SG_ 2616992625 SAD_L99H01_B_TW 0;
BA_ "GenSigSendType" SG_ 2616992625 SAD_L99H01_B_TSD 0;
BA_ "GenSigSwitchedByIgnition" SG_ 2616992625 SAD_L99H01_B_TSD 0;
BA_ "GenSigSendType" SG_ 2616992625 SAD_L99H01_B_STK_RESET_Q 0;
BA_ "GenSigSwitchedByIgnition" SG_ 2616992625 SAD_L99H01_B_STK_RESET_Q 0;
BA_ "GenSigSendType" SG_ 2616992625 SAD_L99H01_B_rOT_EXT 0;
BA_ "GenSigSwitchedByIgnition" SG_ 2616992625 SAD_L99H01_B_rOT_EXT 0;
BA_ "GenSigSendType" SG_ 2616992625 SAD_L99H01_B_rDS_MON_3 0;
BA_ "GenSigSwitchedByIgnition" SG_ 2616992625 SAD_L99H01_B_rDS_MON_3 0;
BA_ "GenSigSendType" SG_ 2616992625 SAD_L99H01_B_rDS_MON_2 0;
BA_ "GenSigSwitchedByIgnition" SG_ 2616992625 SAD_L99H01_B_rDS_MON_2 0;
BA_ "GenSigSendType" SG_ 2616992625 SAD_L99H01_B_rDS_MON_1 0;
BA_ "GenSigSwitchedByIgnition" SG_ 2616992625 SAD_L99H01_B_rDS_MON_1 0;
BA_ "GenSigSendType" SG_ 2616992625 SAD_L99H01_B_rDS_MON_0 0;
BA_ "GenSigSwitchedByIgnition" SG_ 2616992625 SAD_L99H01_B_rDS_MON_0 0;
BA_ "GenSigSendType" SG_ 2616992625 SAD_L99H01_B_rCP_LOW 0;
BA_ "GenSigSwitchedByIgnition" SG_ 2616992625 SAD_L99H01_B_rCP_LOW 0;
BA_ "GenSigSendType" SG_ 2616992625 SAD_L99H01_B_OV 0;
BA_ "GenSigSwitchedByIgnition" SG_ 2616992625 SAD_L99H01_B_OV 0;
BA_ "GenSigSendType" SG_ 2616992625 SAD_L99H01_B_GL_ER 0;
BA_ "GenSigSwitchedByIgnition" SG_ 2616992625 SAD_L99H01_B_GL_ER 0;
BA_ "GenSigSendType" SG_ 2616992625 SAD_L99H01_B_FE 0;
BA_ "GenSigSwitchedByIgnition" SG_ 2616992625 SAD_L99H01_B_FE 0;
BA_ "GenSigSendType" SG_ 2616992625 SAD_L99H01_B_Error 0;
BA_ "GenSigSwitchedByIgnition" SG_ 2616992625 SAD_L99H01_B_Error 0;
BA_ "GenSigSendType" SG_ 2616992625 SAD_L99H01_B_State 0;
BA_ "GenSigSwitchedByIgnition" SG_ 2616992625 SAD_L99H01_B_State 0;
BA_ "GenSigSendType" SG_ 2616992625 SAD_L99H01_B_SC2GND 0;
BA_ "GenSigSwitchedByIgnition" SG_ 2616992625 SAD_L99H01_B_SC2GND 0;
BA_ "GenSigSendType" SG_ 2616992625 SAD_L99H01_B_SC2BAT_LS 0;
BA_ "GenSigSwitchedByIgnition" SG_ 2616992625 SAD_L99H01_B_SC2BAT_LS 0;
BA_ "GenSigSendType" SG_ 2616992625 SAD_L99H01_B_SC2BAT_HS 0;
BA_ "GenSigSwitchedByIgnition" SG_ 2616992625 SAD_L99H01_B_SC2BAT_HS 0;
BA_ "GenSigSendType" SG_ 2616992609 SAD_L99H01_A_WDTO 0;
BA_ "GenSigSwitchedByIgnition" SG_ 2616992609 SAD_L99H01_A_WDTO 0;
BA_ "GenSigSendType" SG_ 2616992609 SAD_L99H01_A_UV 0;
BA_ "GenSigSwitchedByIgnition" SG_ 2616992609 SAD_L99H01_A_UV 0;
BA_ "GenSigSendType" SG_ 2616992609 SAD_L99H01_A_TW 0;
BA_ "GenSigSwitchedByIgnition" SG_ 2616992609 SAD_L99H01_A_TW 0;
BA_ "GenSigSendType" SG_ 2616992609 SAD_L99H01_A_TSD 0;
BA_ "GenSigSwitchedByIgnition" SG_ 2616992609 SAD_L99H01_A_TSD 0;
BA_ "GenSigSendType" SG_ 2616992609 SAD_L99H01_A_STK_RESET_Q 0;
BA_ "GenSigSwitchedByIgnition" SG_ 2616992609 SAD_L99H01_A_STK_RESET_Q 0;
BA_ "GenSigSendType" SG_ 2616992609 SAD_L99H01_A_rOT_EXT 0;
BA_ "GenSigSwitchedByIgnition" SG_ 2616992609 SAD_L99H01_A_rOT_EXT 0;
BA_ "GenSigSendType" SG_ 2616992609 SAD_L99H01_A_rDS_MON_3 0;
BA_ "GenSigSwitchedByIgnition" SG_ 2616992609 SAD_L99H01_A_rDS_MON_3 0;
BA_ "GenSigSendType" SG_ 2616992609 SAD_L99H01_A_rDS_MON_2 0;
BA_ "GenSigSwitchedByIgnition" SG_ 2616992609 SAD_L99H01_A_rDS_MON_2 0;
BA_ "GenSigSendType" SG_ 2616992609 SAD_L99H01_A_rDS_MON_1 0;
BA_ "GenSigSwitchedByIgnition" SG_ 2616992609 SAD_L99H01_A_rDS_MON_1 0;
BA_ "GenSigSendType" SG_ 2616992609 SAD_L99H01_A_rDS_MON_0 0;
BA_ "GenSigSwitchedByIgnition" SG_ 2616992609 SAD_L99H01_A_rDS_MON_0 0;
BA_ "GenSigSendType" SG_ 2616992609 SAD_L99H01_A_rCP_LOW 0;
BA_ "GenSigSwitchedByIgnition" SG_ 2616992609 SAD_L99H01_A_rCP_LOW 0;
BA_ "GenSigSendType" SG_ 2616992609 SAD_L99H01_A_OV 0;
BA_ "GenSigSwitchedByIgnition" SG_ 2616992609 SAD_L99H01_A_OV 0;
BA_ "GenSigSendType" SG_ 2616992609 SAD_L99H01_A_GL_ER 0;
BA_ "GenSigSwitchedByIgnition" SG_ 2616992609 SAD_L99H01_A_GL_ER 0;
BA_ "GenSigSendType" SG_ 2616992609 SAD_L99H01_A_FE 0;
BA_ "GenSigSwitchedByIgnition" SG_ 2616992609 SAD_L99H01_A_FE 0;
BA_ "GenSigSendType" SG_ 2616992609 SAD_L99H01_A_Error 0;
BA_ "GenSigSwitchedByIgnition" SG_ 2616992609 SAD_L99H01_A_Error 0;
BA_ "GenSigSendType" SG_ 2616992609 SAD_L99H01_A_State 0;
BA_ "GenSigSwitchedByIgnition" SG_ 2616992609 SAD_L99H01_A_State 0;
BA_ "GenSigSendType" SG_ 2616992609 SAD_L99H01_A_SC2GND 0;
BA_ "GenSigSwitchedByIgnition" SG_ 2616992609 SAD_L99H01_A_SC2GND 0;
BA_ "GenSigSendType" SG_ 2616992609 SAD_L99H01_A_SC2BAT_LS 0;
BA_ "GenSigSwitchedByIgnition" SG_ 2616992609 SAD_L99H01_A_SC2BAT_LS 0;
BA_ "GenSigSendType" SG_ 2616992609 SAD_L99H01_A_SC2BAT_HS 0;
BA_ "GenSigSwitchedByIgnition" SG_ 2616992609 SAD_L99H01_A_SC2BAT_HS 0;
BA_ "GenSigFuncType" SG_ 302 ACC_07_CRC 2;
BA_ "GenSigSendType" SG_ 302 ACC_07_CRC 0;
BA_ "GenSigFuncType" SG_ 302 ACC_07_BZ 1;
BA_ "GenSigSendType" SG_ 302 ACC_07_BZ 0;
BA_ "Fehlerwert" SG_ 302 ACC_Anhalteweg 2047;
BA_ "GenSigStartValue" SG_ 302 ACC_Anhalteweg 2046;
BA_ "GenSigSendType" SG_ 302 ACC_Anhalteweg 0;
BA_ "GenSigSendType" SG_ 302 ACC_Anhalten 0;
BA_ "GenSigSendType" SG_ 302 ACC_Freilauf_Anf 0;
BA_ "GenSigSendType" SG_ 302 ACC_Freilauf_Info 0;
BA_ "GenSigSendType" SG_ 302 ACC_Anforderung_HMS 0;
BA_ "GenSigSendType" SG_ 302 STA_Anf_BVS_unterdruecken 0;
BA_ "Fehlerwert" SG_ 302 STA_Status_HC 10;
BA_ "GenSigStartValue" SG_ 302 STA_Status_HC 14;
BA_ "GenSigSendType" SG_ 302 STA_Status_HC 0;
BA_ "GenSigSendType" SG_ 302 STA_Verzoeg_Anf_Freigabe 0;
BA_ "GenSigStartValue" SG_ 302 STA_Verzoeg_Anf 127;
BA_ "GenSigSendType" SG_ 302 STA_Verzoeg_Anf 0;
BA_ "GenSigSendType" SG_ 302 CBM_Warnblinken 0;
BA_ "GenSigSendType" SG_ 302 STA_Anforderung_HMS 0;
BA_ "GenSigStartValue" SG_ 302 ACC_Folgebeschl 254;
BA_ "GenSigSendType" SG_ 302 ACC_Folgebeschl 0;
BA_ "GenSigSendType" SG_ 680 ACC_Texte_Abstandswarner 0;
BA_ "GenSigSendType" SG_ 680 ACC_Vorz_Abstandswarner 0;
BA_ "GenSigSendType" SG_ 680 ACC_Texte_Sekundaeranz 0;
BA_ "GenSigSendType" SG_ 680 ACC_Status_Anzeige 3;
BA_ "GenSigSendType" SG_ 680 ACC_Akustik_03 0;
BA_ "NWM-WakeupAllowed" SG_ 680 ACC_Geschw_Zielfahrzeug 1;
BA_ "GenSigSendType" SG_ 680 ACC_Geschw_Zielfahrzeug 0;
BA_ "GenSigSendType" SG_ 680 ACC_Texte 0;
BA_ "GenSigSendType" SG_ 680 ACC_STA_Text 0;
BA_ "GenSigSendType" SG_ 680 STA_Texte 0;
BA_ "GenSigSendType" SG_ 680 STA_Zusatzanz 0;
BA_ "GenSigStartValue" SG_ 680 ACC_Zeitluecke_Abstandswarner 63;
BA_ "GenSigSendType" SG_ 680 ACC_Zeitluecke_Abstandswarner 0;
BA_ "GenSigStartValue" SG_ 680 ACC_Abstand_Abstandswarner 511;
BA_ "GenSigSendType" SG_ 680 ACC_Abstand_Abstandswarner 0;
BA_ "GenSigSendType" SG_ 680 ACC_Einheit_Abstandswarner 0;
BA_ "GenSigSwitchedByIgnition" SG_ 64 Airbag_01_CRC 0;
BA_ "GenSigFuncType" SG_ 64 Airbag_01_CRC 2;
BA_ "GenSigSendType" SG_ 64 Airbag_01_CRC 0;
BA_ "GenSigSwitchedByIgnition" SG_ 64 Airbag_01_BZ 0;
BA_ "GenSigFuncType" SG_ 64 Airbag_01_BZ 1;
BA_ "GenSigSendType" SG_ 64 Airbag_01_BZ 0;
BA_ "GenSigSwitchedByIgnition" SG_ 64 AB_RGS_Anst 0;
BA_ "GenSigStartValue" SG_ 64 AB_RGS_Anst 8;
BA_ "GenSigSendType" SG_ 64 AB_RGS_Anst 3;
BA_ "GenSigSwitchedByIgnition" SG_ 64 AB_Front_Crash 0;
BA_ "GenSigSendType" SG_ 64 AB_Front_Crash 4;
BA_ "GenSigActiveRepetitions" SG_ 64 AB_Front_Crash 5;
BA_ "GenSigSwitchedByIgnition" SG_ 64 AB_Heck_Crash 0;
BA_ "GenSigSendType" SG_ 64 AB_Heck_Crash 4;
BA_ "GenSigActiveRepetitions" SG_ 64 AB_Heck_Crash 5;
BA_ "GenSigSwitchedByIgnition" SG_ 64 AB_SF_Crash 0;
BA_ "GenSigSendType" SG_ 64 AB_SF_Crash 4;
BA_ "GenSigActiveRepetitions" SG_ 64 AB_SF_Crash 5;
BA_ "GenSigSwitchedByIgnition" SG_ 64 AB_SB_Crash 0;
BA_ "GenSigSendType" SG_ 64 AB_SB_Crash 4;
BA_ "GenSigActiveRepetitions" SG_ 64 AB_SB_Crash 5;
BA_ "GenSigSwitchedByIgnition" SG_ 64 AB_Rollover_Crash 0;
BA_ "GenSigSendType" SG_ 64 AB_Rollover_Crash 4;
BA_ "GenSigActiveRepetitions" SG_ 64 AB_Rollover_Crash 5;
BA_ "GenSigSwitchedByIgnition" SG_ 64 AB_Crash_Int 0;
BA_ "GenSigSendType" SG_ 64 AB_Crash_Int 4;
BA_ "GenSigActiveRepetitions" SG_ 64 AB_Crash_Int 5;
BA_ "GenSigSwitchedByIgnition" SG_ 64 AB_Lampe 0;
BA_ "GenSigStartValue" SG_ 64 AB_Lampe 1;
BA_ "GenSigSendType" SG_ 64 AB_Lampe 0;
BA_ "GenSigSwitchedByIgnition" SG_ 64 AB_Deaktiviert 0;
BA_ "GenSigSendType" SG_ 64 AB_Deaktiviert 0;
BA_ "GenSigSwitchedByIgnition" SG_ 64 AB_VB_deaktiviert 0;
BA_ "GenSigStartValue" SG_ 64 AB_VB_deaktiviert 1;
BA_ "GenSigSendType" SG_ 64 AB_VB_deaktiviert 0;
BA_ "GenSigSwitchedByIgnition" SG_ 64 AB_Systemfehler 0;
BA_ "GenSigSendType" SG_ 64 AB_Systemfehler 0;
BA_ "GenSigSwitchedByIgnition" SG_ 64 AB_Diagnose 0;
BA_ "GenSigSendType" SG_ 64 AB_Diagnose 0;
BA_ "GenSigSwitchedByIgnition" SG_ 64 AB_Stellgliedtest 0;
BA_ "GenSigSendType" SG_ 64 AB_Stellgliedtest 0;
BA_ "GenSigSwitchedByIgnition" SG_ 64 AB_Erh_Auf_VB 0;
BA_ "GenSigSendType" SG_ 64 AB_Erh_Auf_VB 0;
BA_ "GenSigSwitchedByIgnition" SG_ 64 AB_Gurtwarn_VF 0;
BA_ "GenSigSendType" SG_ 64 AB_Gurtwarn_VF 0;
BA_ "GenSigSwitchedByIgnition" SG_ 64 AB_Gurtwarn_VB 0;
BA_ "GenSigSendType" SG_ 64 AB_Gurtwarn_VB 0;
BA_ "GenSigSwitchedByIgnition" SG_ 64 AB_Anzeige_Fussg 0;
BA_ "GenSigSendType" SG_ 64 AB_Anzeige_Fussg 0;
BA_ "GenSigSwitchedByIgnition" SG_ 64 AB_Texte_AKS 0;
BA_ "GenSigSendType" SG_ 64 AB_Texte_AKS 0;
BA_ "GenSigSwitchedByIgnition" SG_ 64 AB_MKB_gueltig 0;
BA_ "GenSigFuncType" SG_ 64 AB_MKB_gueltig 8;
BA_ "GenSigSendType" SG_ 64 AB_MKB_gueltig 0;
BA_ "GenSigSwitchedByIgnition" SG_ 64 AB_MKB_Anforderung 0;
BA_ "GenSigSendType" SG_ 64 AB_MKB_Anforderung 4;
BA_ "GenSigActiveRepetitions" SG_ 64 AB_MKB_Anforderung 5;
BA_ "GenSigSwitchedByIgnition" SG_ 64 AB_Versorgungsspannung 0;
BA_ "GenSigSendType" SG_ 64 AB_Versorgungsspannung 0;
BA_ "Fehlerwert" SG_ 64 AB_Deaktivierung_HV 7;
BA_ "GenSigSwitchedByIgnition" SG_ 64 AB_Deaktivierung_HV 0;
BA_ "GenSigSendType" SG_ 64 AB_Deaktivierung_HV 4;
BA_ "GenSigActiveRepetitions" SG_ 64 AB_Deaktivierung_HV 5;
BA_ "GenSigSwitchedByIgnition" SG_ 64 AB_EDR_Trigger 0;
BA_ "GenSigSendType" SG_ 64 AB_EDR_Trigger 3;
BA_ "GenSigSwitchedByIgnition" SG_ 64 SC_LowSpeedCrashErkannt 0;
BA_ "GenSigSendType" SG_ 64 SC_LowSpeedCrashErkannt 0;
BA_ "GenSigStartValue" SG_ 64 SC_Masterzeit 127;
BA_ "GenSigSendType" SG_ 64 SC_Masterzeit 0;
BA_ "GenSigSwitchedByIgnition" SG_ 1312 Airbag_02_CRC 0;
BA_ "GenSigFuncType" SG_ 1312 Airbag_02_CRC 2;
BA_ "GenSigSendType" SG_ 1312 Airbag_02_CRC 0;
BA_ "GenSigSwitchedByIgnition" SG_ 1312 Airbag_02_BZ 0;
BA_ "GenSigFuncType" SG_ 1312 Airbag_02_BZ 1;
BA_ "GenSigSendType" SG_ 1312 Airbag_02_BZ 0;
BA_ "GenSigSwitchedByIgnition" SG_ 1312 LoGeWa_Event_Kombiwarnung 0;
BA_ "GenSigSendType" SG_ 1312 LoGeWa_Event_Kombiwarnung 3;
BA_ "GenSigSendType" SG_ 1312 AB_Anprall_Seite_Beifahrer 3;
BA_ "GenSigSendType" SG_ 1312 AB_Anprall_Rollover 3;
BA_ "GenSigSendType" SG_ 1312 AB_Anprall_FGS 3;
BA_ "GenSigSendType" SG_ 1312 AB_Anprall_Front_Beifahrer 3;
BA_ "GenSigSendType" SG_ 1312 AB_Anprall_Front_Fahrer 3;
BA_ "GenSigSendType" SG_ 1312 AB_Anprall_Heck_Beifahrer 3;
BA_ "GenSigSendType" SG_ 1312 AB_Anprall_Heck_Fahrer 3;
BA_ "GenSigSwitchedByIgnition" SG_ 1312 AB_Wickelklappung_Reihe2_MI 0;
BA_ "GenSigSendType" SG_ 1312 AB_Wickelklappung_Reihe2_MI 3;
BA_ "Fehlerwert" SG_ 1312 AB_Belegung_VB 1;
BA_ "GenSigSwitchedByIgnition" SG_ 1312 AB_Belegung_VB 0;
BA_ "GenSigSendType" SG_ 1312 AB_Belegung_VB 0;
BA_ "GenSigSendType" SG_ 1312 AB_Abschaltanf_SIH_BF 3;
BA_ "GenSigSendType" SG_ 1312 AB_Anprall_Seite_Fahrer 3;
BA_ "GenSigSwitchedByIgnition" SG_ 1312 SC_PAO_Schriftzug_Anf 0;
BA_ "GenSigSendType" SG_ 1312 SC_PAO_Schriftzug_Anf 0;
BA_ "GenSigSwitchedByIgnition" SG_ 1312 SC_PAO_ON_Anf 0;
BA_ "GenSigSendType" SG_ 1312 SC_PAO_ON_Anf 0;
BA_ "GenSigSwitchedByIgnition" SG_ 1312 SC_PAO_OFF_Anf 0;
BA_ "GenSigSendType" SG_ 1312 SC_PAO_OFF_Anf 0;
BA_ "Fehlerwert" SG_ 1312 AB_Crashschwere 7;
BA_ "GenSigSwitchedByIgnition" SG_ 1312 AB_Crashschwere 0;
BA_ "GenSigSendType" SG_ 1312 AB_Crashschwere 3;
BA_ "GenSigSwitchedByIgnition" SG_ 1312 AB_Anforderung_USM 0;
BA_ "GenSigSendType" SG_ 1312 AB_Anforderung_USM 0;
BA_ "GenSigSwitchedByIgnition" SG_ 1312 AB_Gurtschloss_FA 0;
BA_ "GenSigStartValue" SG_ 1312 AB_Gurtschloss_FA 1;
BA_ "GenSigSendType" SG_ 1312 AB_Gurtschloss_FA 3;
BA_ "GenSigSwitchedByIgnition" SG_ 1312 AB_Gurtschloss_BF 0;
BA_ "GenSigStartValue" SG_ 1312 AB_Gurtschloss_BF 1;
BA_ "GenSigSendType" SG_ 1312 AB_Gurtschloss_BF 3;
BA_ "GenSigSwitchedByIgnition" SG_ 1312 AB_Gurtschloss_Reihe2_FA 0;
BA_ "GenSigStartValue" SG_ 1312 AB_Gurtschloss_Reihe2_FA 1;
BA_ "GenSigSendType" SG_ 1312 AB_Gurtschloss_Reihe2_FA 3;
BA_ "GenSigSwitchedByIgnition" SG_ 1312 AB_Gurtschloss_Reihe2_MI 0;
BA_ "GenSigStartValue" SG_ 1312 AB_Gurtschloss_Reihe2_MI 1;
BA_ "GenSigSendType" SG_ 1312 AB_Gurtschloss_Reihe2_MI 3;
BA_ "GenSigSwitchedByIgnition" SG_ 1312 AB_Gurtschloss_Reihe2_BF 0;
BA_ "GenSigStartValue" SG_ 1312 AB_Gurtschloss_Reihe2_BF 1;
BA_ "GenSigSendType" SG_ 1312 AB_Gurtschloss_Reihe2_BF 3;
BA_ "GenSigSwitchedByIgnition" SG_ 1312 AB_Gurtschloss_Reihe3_FA 0;
BA_ "GenSigStartValue" SG_ 1312 AB_Gurtschloss_Reihe3_FA 1;
BA_ "GenSigSendType" SG_ 1312 AB_Gurtschloss_Reihe3_FA 3;
BA_ "GenSigSwitchedByIgnition" SG_ 1312 AB_Gurtschloss_Reihe3_MI 0;
BA_ "GenSigStartValue" SG_ 1312 AB_Gurtschloss_Reihe3_MI 1;
BA_ "GenSigSendType" SG_ 1312 AB_Gurtschloss_Reihe3_MI 3;
BA_ "GenSigSwitchedByIgnition" SG_ 1312 AB_Gurtschloss_Reihe3_BF 0;
BA_ "GenSigStartValue" SG_ 1312 AB_Gurtschloss_Reihe3_BF 1;
BA_ "GenSigSendType" SG_ 1312 AB_Gurtschloss_Reihe3_BF 3;
BA_ "Fehlerwert" SG_ 1312 AB_Sitzpos_Sens_FA 1;
BA_ "GenSigSwitchedByIgnition" SG_ 1312 AB_Sitzpos_Sens_FA 0;
BA_ "GenSigSendType" SG_ 1312 AB_Sitzpos_Sens_FA 0;
BA_ "Fehlerwert" SG_ 1312 AB_Sitzpos_Sens_BF 1;
BA_ "GenSigSwitchedByIgnition" SG_ 1312 AB_Sitzpos_Sens_BF 0;
BA_ "GenSigSendType" SG_ 1312 AB_Sitzpos_Sens_BF 0;
BA_ "GenSigSwitchedByIgnition" SG_ 1312 AB_Wickelklappung_Reihe2_BF 0;
BA_ "GenSigSendType" SG_ 1312 AB_Wickelklappung_Reihe2_BF 3;
BA_ "GenSigSwitchedByIgnition" SG_ 1312 AB_Wickelklappung_Reihe2_FA 0;
BA_ "GenSigSendType" SG_ 1312 AB_Wickelklappung_Reihe2_FA 3;
BA_ "GenSigSwitchedByIgnition" SG_ 1633 AAG_BZ 0;
BA_ "GenSigFuncType" SG_ 1633 AAG_BZ 1;
BA_ "GenSigSendType" SG_ 1633 AAG_BZ 0;
BA_ "GenSigSwitchedByIgnition" SG_ 1633 AAG_AVS_Fehler_02_inv 0;
BA_ "GenSigStartValue" SG_ 1633 AAG_AVS_Fehler_02_inv 1;
BA_ "GenSigSendType" SG_ 1633 AAG_AVS_Fehler_02_inv 0;
BA_ "GenSigSwitchedByIgnition" SG_ 1633 AAG_Bremsl_durch_ECD 0;
BA_ "GenSigSendType" SG_ 1633 AAG_Bremsl_durch_ECD 0;
BA_ "GenSigSwitchedByIgnition" SG_ 1633 AAG_Anhaenger_abgesteckt 0;
BA_ "GenSigSendType" SG_ 1633 AAG_Anhaenger_abgesteckt 0;
BA_ "GenSigSwitchedByIgnition" SG_ 1633 AAG_NSL_aktiv 0;
BA_ "GenSigSendType" SG_ 1633 AAG_NSL_aktiv 0;
BA_ "GenSigSwitchedByIgnition" SG_ 1633 AAG_Anhaenger_erkannt 0;
BA_ "NWM-WakeupAllowed" SG_ 1633 AAG_Anhaenger_erkannt 1;
BA_ "GenSigSendType" SG_ 1633 AAG_Anhaenger_erkannt 0;
BA_ "GenSigSwitchedByIgnition" SG_ 1633 AAG_Blinker_H_aktiv 0;
BA_ "GenSigSendType" SG_ 1633 AAG_Blinker_H_aktiv 0;
BA_ "GenSigSwitchedByIgnition" SG_ 1633 AAG_Blinker_HL_def 0;
BA_ "GenSigSendType" SG_ 1633 AAG_Blinker_HL_def 0;
BA_ "GenSigSwitchedByIgnition" SG_ 1633 AAG_Blinker_HR_def 0;
BA_ "GenSigSendType" SG_ 1633 AAG_Blinker_HR_def 0;
BA_ "GenSigSwitchedByIgnition" SG_ 1633 AAG_Bremslicht_H_def 0;
BA_ "GenSigSendType" SG_ 1633 AAG_Bremslicht_H_def 0;
BA_ "GenSigSwitchedByIgnition" SG_ 1633 AAG_Schlusslicht_HL_def 0;
BA_ "GenSigSendType" SG_ 1633 AAG_Schlusslicht_HL_def 0;
BA_ "GenSigSwitchedByIgnition" SG_ 1633 AAG_Schlusslicht_HR_def 0;
BA_ "GenSigSendType" SG_ 1633 AAG_Schlusslicht_HR_def 0;
BA_ "GenSigSwitchedByIgnition" SG_ 1633 AAG_Bremslicht_Reku 0;
BA_ "GenSigSendType" SG_ 1633 AAG_Bremslicht_Reku 0;
BA_ "Fehlerwert" SG_ 1633 AAG_AVS_Fehler_02 1;
BA_ "GenSigSwitchedByIgnition" SG_ 1633 AAG_AVS_Fehler_02 0;
BA_ "GenSigSendType" SG_ 1633 AAG_AVS_Fehler_02 0;
BA_ "GenSigSwitchedByIgnition" SG_ 1633 AAG_AVS_Stati 0;
BA_ "GenSigSendType" SG_ 1633 AAG_AVS_Stati 0;
BA_ "GenSigStartValue" SG_ 897 US_RDir_VL 255;
BA_ "GenSigSendType" SG_ 897 US_RDir_VL 0;
BA_ "GenSigStartValue" SG_ 897 US_RDir_VLM 255;
BA_ "GenSigSendType" SG_ 897 US_RDir_VLM 0;
BA_ "GenSigStartValue" SG_ 897 US_RIndir_VLM_VL 255;
BA_ "GenSigSendType" SG_ 897 US_RIndir_VLM_VL 0;
BA_ "GenSigStartValue" SG_ 897 US_RIndir_VLM_VRM 255;
BA_ "GenSigSendType" SG_ 897 US_RIndir_VLM_VRM 0;
BA_ "GenSigStartValue" SG_ 897 US_RIndir_VL_VLM 255;
BA_ "GenSigSendType" SG_ 897 US_RIndir_VL_VLM 0;
BA_ "GenSigStartValue" SG_ 897 US_GDir_VL 15;
BA_ "GenSigSendType" SG_ 897 US_GDir_VL 0;
BA_ "GenSigStartValue" SG_ 897 US_GDir_VLM 15;
BA_ "GenSigSendType" SG_ 897 US_GDir_VLM 0;
BA_ "GenSigStartValue" SG_ 897 US_GIndir_VLM_VL 15;
BA_ "GenSigSendType" SG_ 897 US_GIndir_VLM_VL 0;
BA_ "GenSigStartValue" SG_ 897 US_GIndir_VLM_VRM 15;
BA_ "GenSigSendType" SG_ 897 US_GIndir_VLM_VRM 0;
BA_ "GenSigStartValue" SG_ 897 US_GIndir_VL_VLM 15;
BA_ "GenSigSendType" SG_ 897 US_GIndir_VL_VLM 0;
BA_ "GenSigSendType" SG_ 897 APS_01_Paketzaehler 0;
BA_ "GenSigStartValue" SG_ 898 US_RDir_VR 255;
BA_ "GenSigSendType" SG_ 898 US_RDir_VR 0;
BA_ "GenSigStartValue" SG_ 898 US_RDir_VRM 255;
BA_ "GenSigSendType" SG_ 898 US_RDir_VRM 0;
BA_ "GenSigStartValue" SG_ 898 US_RIndir_VRM_VR 255;
BA_ "GenSigSendType" SG_ 898 US_RIndir_VRM_VR 0;
BA_ "GenSigStartValue" SG_ 898 US_RIndir_VRM_VLM 255;
BA_ "GenSigSendType" SG_ 898 US_RIndir_VRM_VLM 0;
BA_ "GenSigStartValue" SG_ 898 US_RIndir_VR_VRM 255;
BA_ "GenSigSendType" SG_ 898 US_RIndir_VR_VRM 0;
BA_ "GenSigStartValue" SG_ 898 US_GDir_VR 15;
BA_ "GenSigSendType" SG_ 898 US_GDir_VR 0;
BA_ "GenSigStartValue" SG_ 898 US_GDir_VRM 15;
BA_ "GenSigSendType" SG_ 898 US_GDir_VRM 0;
BA_ "GenSigStartValue" SG_ 898 US_GIndir_VRM_VLM 15;
BA_ "GenSigSendType" SG_ 898 US_GIndir_VRM_VLM 0;
BA_ "GenSigStartValue" SG_ 898 US_GIndir_VRM_VR 15;
BA_ "GenSigSendType" SG_ 898 US_GIndir_VRM_VR 0;
BA_ "GenSigStartValue" SG_ 898 US_GIndir_VR_VRM 15;
BA_ "GenSigSendType" SG_ 898 US_GIndir_VR_VRM 0;
BA_ "GenSigSendType" SG_ 898 APS_02_Paketzaehler 0;
BA_ "GenSigStartValue" SG_ 927 US_RDir_VRS 1023;
BA_ "GenSigSendType" SG_ 927 US_RDir_VRS 0;
BA_ "GenSigStartValue" SG_ 927 US_RDir_VLS 1023;
BA_ "GenSigSendType" SG_ 927 US_RDir_VLS 0;
BA_ "GenSigStartValue" SG_ 927 US_RDir_HRS 1023;
BA_ "GenSigSendType" SG_ 927 US_RDir_HRS 0;
BA_ "GenSigStartValue" SG_ 927 US_RDir_HLS 1023;
BA_ "GenSigSendType" SG_ 927 US_RDir_HLS 0;
BA_ "Fehlerwert" SG_ 927 US_Fehler_VS 1;
BA_ "GenSigSendType" SG_ 927 US_Fehler_VS 0;
BA_ "Fehlerwert" SG_ 927 US_Fehler_HS 1;
BA_ "GenSigSendType" SG_ 927 US_Fehler_HS 0;
BA_ "GenSigSendType" SG_ 927 US_Verschmutzung_VS 0;
BA_ "GenSigSendType" SG_ 927 US_Verschmutzung_HS 0;
BA_ "GenSigSendType" SG_ 927 US_NichtVerfuegbarkeit_VS 0;
BA_ "GenSigSendType" SG_ 927 US_NichtVerfuegbarkeit_HS 0;
BA_ "GenSigSendType" SG_ 927 APS_03_Paketzaehler 0;
BA_ "GenSigFuncType" SG_ 896 US_ACC_CRC 2;
BA_ "GenSigSendType" SG_ 896 US_ACC_CRC 0;
BA_ "GenSigFuncType" SG_ 896 US_ACC_BZ 1;
BA_ "GenSigSendType" SG_ 896 US_ACC_BZ 0;
BA_ "Fehlerwert" SG_ 896 US_Sende_Modus 15;
BA_ "GenSigSendType" SG_ 896 US_Sende_Modus 0;
BA_ "GenSigSendType" SG_ 896 US_relevanter_Fehler 0;
BA_ "GenSigSendType" SG_ 896 US_relevante_Nichtverfuegbarkeit 0;
BA_ "GenSigSendType" SG_ 896 US_Freisicht_nio 0;
BA_ "GenSigSendType" SG_ 896 US_blindness_detected 0;
BA_ "Fehlerwert" SG_ 896 US_Sende_Modus_hinten 15;
BA_ "GenSigSendType" SG_ 896 US_Sende_Modus_hinten 0;
BA_ "GenSigFuncType" SG_ 2527679497 ARA_01_CRC 2;
BA_ "GenSigSendType" SG_ 2527679497 ARA_01_CRC 0;
BA_ "GenSigFuncType" SG_ 2527679497 ARA_01_BZ 1;
BA_ "GenSigSendType" SG_ 2527679497 ARA_01_BZ 0;
BA_ "GenSigStartValue" SG_ 2527679497 ARA_Status_ARA_HAL 9;
BA_ "GenSigSendType" SG_ 2527679497 ARA_Status_ARA_HAL 0;
BA_ "GenSigSwitchedByIgnition" SG_ 2527679497 ARA_HAL_Radwinkel_Soll 0;
BA_ "GenSigSendType" SG_ 2527679497 ARA_HAL_Radwinkel_Soll 0;
BA_ "GenSigSwitchedByIgnition" SG_ 2527679497 ARA_HAL_VZ_Radwinkel_Soll 0;
BA_ "GenSigSendType" SG_ 2527679497 ARA_HAL_VZ_Radwinkel_Soll 0;
BA_ "GenSigStartValue" SG_ 2527679497 ARA_Status_ARA_EPS 9;
BA_ "GenSigSendType" SG_ 2527679497 ARA_Status_ARA_EPS 0;
BA_ "GenSigSwitchedByIgnition" SG_ 2527679497 ARA_VZ_Zahnstangen_Pos_Soll 0;
BA_ "GenSigSendType" SG_ 2527679497 ARA_VZ_Zahnstangen_Pos_Soll 0;
BA_ "GenSigSendType" SG_ 2527679497 ARA_Zahnstangen_Pos_Soll 0;
BA_ "GenSigSendType" SG_ 2527679497 ARA_01_Signal_red_cyclic 6;
BA_ "GenSigFuncType" SG_ 677 ARA_02_CRC 2;
BA_ "GenSigSendType" SG_ 677 ARA_02_CRC 0;
BA_ "GenSigFuncType" SG_ 677 ARA_02_BZ 1;
BA_ "GenSigSendType" SG_ 677 ARA_02_BZ 0;
BA_ "GenSigSendType" SG_ 677 ARA_02_Signal_red_cyclic 6;
BA_ "Fehlerwert" SG_ 677 ARA_Bremsverzoegerung 127;
BA_ "GenSigSwitchedByIgnition" SG_ 677 ARA_Bremsverzoegerung 0;
BA_ "GenSigStartValue" SG_ 677 ARA_Bremsverzoegerung 126;
BA_ "GenSigSendType" SG_ 677 ARA_Bremsverzoegerung 0;
BA_ "GenSigSendType" SG_ 677 ARA_Anf_Bremsverzoegerung 0;
BA_ "Fehlerwert" SG_ 677 ARA_maximale_Beschleunigung 127;
BA_ "GenSigStartValue" SG_ 677 ARA_maximale_Beschleunigung 122;
BA_ "GenSigSendType" SG_ 677 ARA_maximale_Beschleunigung 0;
BA_ "GenSigSwitchedByIgnition" SG_ 677 ARA_Anhalten 0;
BA_ "GenSigSendType" SG_ 677 ARA_Anhalten 0;
BA_ "Fehlerwert" SG_ 677 ARA_Anhaltweg 2047;
BA_ "GenSigStartValue" SG_ 677 ARA_Anhaltweg 2046;
BA_ "GenSigSendType" SG_ 677 ARA_Anhaltweg 0;
BA_ "GenSigSendType" SG_ 677 ARA_Anforderung_HMS 0;
BA_ "Fehlerwert" SG_ 677 ARA_Parken_beibehalten_HMS 3;
BA_ "GenSigStartValue" SG_ 677 ARA_Parken_beibehalten_HMS 2;
BA_ "GenSigSendType" SG_ 677 ARA_Parken_beibehalten_HMS 0;
BA_ "Fehlerwert" SG_ 677 ARA_maximale_Geschwindigkeit 255;
BA_ "GenSigStartValue" SG_ 677 ARA_maximale_Geschwindigkeit 251;
BA_ "GenSigSendType" SG_ 677 ARA_maximale_Geschwindigkeit 0;
BA_ "Fehlerwert" SG_ 344 ARA_Sensor_Knickwgeschw 4095;
BA_ "GenSigStartValue" SG_ 344 ARA_Sensor_Knickwgeschw 4094;
BA_ "GenSigSendType" SG_ 344 ARA_Sensor_Knickwgeschw 0;
BA_ "GenSigSendType" SG_ 344 ARA_Sensor_Sektoren 0;
BA_ "Fehlerwert" SG_ 344 ARA_Sensor_Knickw_Rohwert 65535;
BA_ "GenSigStartValue" SG_ 344 ARA_Sensor_Knickw_Rohwert 65534;
BA_ "GenSigSendType" SG_ 344 ARA_Sensor_Knickw_Rohwert 0;
BA_ "GenSigSwitchedByIgnition" SG_ 344 ARA_Sensor_Signal_red_cyclic 0;
BA_ "GenSigSendType" SG_ 344 ARA_Sensor_Signal_red_cyclic 6;
BA_ "GenSigSendType" SG_ 344 ARA_Sensor_Knickwgeschw_upd 0;
BA_ "GenSigSendType" SG_ 344 ARA_Sensor_Knickw_Rohwert_upd 0;
BA_ "Fehlerwert" SG_ 345 ARA_Knickwinkel_konfidenz 127;
BA_ "GenSigStartValue" SG_ 345 ARA_Knickwinkel_konfidenz 126;
BA_ "GenSigSendType" SG_ 345 ARA_Knickwinkel_konfidenz 3;
BA_ "Fehlerwert" SG_ 345 ARA_Texte 63;
BA_ "GenSigSendType" SG_ 345 ARA_Texte 3;
BA_ "GenSigSendType" SG_ 345 ARA_Modus 3;
BA_ "GenSigSwitchedByIgnition" SG_ 345 ARA_Aktiver_Grafikmodus 0;
BA_ "GenSigSendType" SG_ 345 ARA_Aktiver_Grafikmodus 3;
BA_ "GenSigSendType" SG_ 345 ARA_Deaktivierung_sperren 3;
BA_ "GenSigSendType" SG_ 345 ARA_Modus_Anf 3;
BA_ "GenSigSendType" SG_ 345 ARA_Bremsfuss 3;
BA_ "GenSigSendType" SG_ 345 ARA_Sensor_Aktivierung 3;
BA_ "GenSigStartValue" SG_ 345 ARA_Knickwinkel_Komfort 62;
BA_ "GenSigSendType" SG_ 345 ARA_Knickwinkel_Komfort 3;
BA_ "Fehlerwert" SG_ 345 ARA_Status 2;
BA_ "GenSigSwitchedByIgnition" SG_ 345 ARA_Status 0;
BA_ "GenSigStartValue" SG_ 345 ARA_Status 1;
BA_ "GenSigSendType" SG_ 345 ARA_Status 3;
BA_ "Fehlerwert" SG_ 345 ARA_Knickwinkel_Max 127;
BA_ "GenSigStartValue" SG_ 345 ARA_Knickwinkel_Max 126;
BA_ "GenSigSendType" SG_ 345 ARA_Knickwinkel_Max 3;
BA_ "Fehlerwert" SG_ 345 ARA_Knickwinkel_Soll 255;
BA_ "GenSigStartValue" SG_ 345 ARA_Knickwinkel_Soll 254;
BA_ "GenSigSendType" SG_ 345 ARA_Knickwinkel_Soll 3;
BA_ "Fehlerwert" SG_ 345 ARA_Knickwinkel_Ist 255;
BA_ "GenSigStartValue" SG_ 345 ARA_Knickwinkel_Ist 254;
BA_ "GenSigSendType" SG_ 345 ARA_Knickwinkel_Ist 3;
BA_ "GenSigSwitchedByIgnition" SG_ 1365 AV_HEK_Status_Anz_Punkte 0;
BA_ "GenSigSendType" SG_ 1365 AV_HEK_Status_Anz_Punkte 0;
BA_ "GenSigSwitchedByIgnition" SG_ 1365 AV_HEK_Status_Zaehler 0;
BA_ "GenSigSendType" SG_ 1365 AV_HEK_Status_Zaehler 0;
BA_ "Fehlerwert" SG_ 1365 AV_HEK_Status_Kamera_H 7;
BA_ "GenSigSwitchedByIgnition" SG_ 1365 AV_HEK_Status_Kamera_H 0;
BA_ "GenSigStartValue" SG_ 1365 AV_HEK_Status_Kamera_H 1;
BA_ "GenSigSendType" SG_ 1365 AV_HEK_Status_Kamera_H 0;
BA_ "Fehlerwert" SG_ 1365 AV_HEK_Status_Kamera_V 7;
BA_ "GenSigSwitchedByIgnition" SG_ 1365 AV_HEK_Status_Kamera_V 0;
BA_ "GenSigStartValue" SG_ 1365 AV_HEK_Status_Kamera_V 1;
BA_ "GenSigSendType" SG_ 1365 AV_HEK_Status_Kamera_V 0;
BA_ "Fehlerwert" SG_ 1365 AV_HEK_Status_Kamera_L 7;
BA_ "GenSigSwitchedByIgnition" SG_ 1365 AV_HEK_Status_Kamera_L 0;
BA_ "GenSigStartValue" SG_ 1365 AV_HEK_Status_Kamera_L 1;
BA_ "GenSigSendType" SG_ 1365 AV_HEK_Status_Kamera_L 0;
BA_ "Fehlerwert" SG_ 1365 AV_HEK_Status_Kamera_R 7;
BA_ "GenSigSwitchedByIgnition" SG_ 1365 AV_HEK_Status_Kamera_R 0;
BA_ "GenSigStartValue" SG_ 1365 AV_HEK_Status_Kamera_R 1;
BA_ "GenSigSendType" SG_ 1365 AV_HEK_Status_Kamera_R 0;
BA_ "GenSigSwitchedByIgnition" SG_ 1365 AV_HEK_Status_aktiv 0;
BA_ "GenSigSendType" SG_ 1365 AV_HEK_Status_aktiv 5;
BA_ "GenSigSwitchedByIgnition" SG_ 1365 AV_Umfeldbeleuchtung_Anf 0;
BA_ "GenSigSendType" SG_ 1365 AV_Umfeldbeleuchtung_Anf 0;
BA_ "GenSigSwitchedByIgnition" SG_ 1365 AV_Charisma_FahrPr 0;
BA_ "GenSigSendType" SG_ 1365 AV_Charisma_FahrPr 3;
BA_ "GenSigSwitchedByIgnition" SG_ 1365 AV_Charisma_Status 0;
BA_ "GenSigSendType" SG_ 1365 AV_Charisma_Status 3;
BA_ "GenSigSwitchedByIgnition" SG_ 2536704256 BAP_Aussenlicht_ASG_01_Header 0;
BA_ "GenSigSendType" SG_ 2536704256 BAP_Aussenlicht_ASG_01_Header 3;
BA_ "GenSigSwitchedByIgnition" SG_ 2536704272 BAP_Aussenlicht_FSG_01_Header 0;
BA_ "GenSigSendType" SG_ 2536704272 BAP_Aussenlicht_FSG_01_Header 3;
BA_ "GenSigSwitchedByIgnition" SG_ 2536711427 BAP_BatteryControl_ASG_04_Header 0;
BA_ "GenSigSendType" SG_ 2536711427 BAP_BatteryControl_ASG_04_Header 3;
BA_ "GenSigSwitchedByIgnition" SG_ 2536711440 BAP_BatteryControl_FSG_01_Header 0;
BA_ "GenSigSendType" SG_ 2536711440 BAP_BatteryControl_FSG_01_Header 3;
BA_ "GenSigSwitchedByIgnition" SG_ 2536705794 BAP_BC_ASG_03_Header 0;
BA_ "GenSigSendType" SG_ 2536705794 BAP_BC_ASG_03_Header 3;
BA_ "GenSigSwitchedByIgnition" SG_ 2536705808 BAP_BC_FSG_01_Header 0;
BA_ "GenSigSendType" SG_ 2536705808 BAP_BC_FSG_01_Header 3;
BA_ "GenSigSwitchedByIgnition" SG_ 2536767264 BAP_Debug_Cmd 0;
BA_ "GenSigSendType" SG_ 2536767264 BAP_Debug_Cmd 3;
BA_ "GenSigSwitchedByIgnition" SG_ 2536767280 BAP_Debug_Data 0;
BA_ "GenSigSendType" SG_ 2536767280 BAP_Debug_Data 3;
BA_ "GenSigSwitchedByIgnition" SG_ 2536705280 BAP_Doorlocking_ASG_01_Header 0;
BA_ "GenSigSendType" SG_ 2536705280 BAP_Doorlocking_ASG_01_Header 3;
BA_ "GenSigSwitchedByIgnition" SG_ 2536705281 BAP_Doorlocking_ASG_02_Header 0;
BA_ "GenSigSendType" SG_ 2536705281 BAP_Doorlocking_ASG_02_Header 3;
BA_ "GenSigSwitchedByIgnition" SG_ 2536705282 BAP_Doorlocking_ASG_03_Data 0;
BA_ "GenSigSendType" SG_ 2536705282 BAP_Doorlocking_ASG_03_Data 3;
BA_ "GenSigSwitchedByIgnition" SG_ 2536705283 BAP_Doorlocking_ASG_04_Header 0;
BA_ "GenSigSendType" SG_ 2536705283 BAP_Doorlocking_ASG_04_Header 3;
BA_ "GenSigSwitchedByIgnition" SG_ 2536705296 BAP_Doorlocking_FSG_01_Header 0;
BA_ "GenSigSendType" SG_ 2536705296 BAP_Doorlocking_FSG_01_Header 3;
BA_ "GenSigSwitchedByIgnition" SG_ 2536707072 BAP_Homelink_ASG_01_Header 0;
BA_ "GenSigSendType" SG_ 2536707072 BAP_Homelink_ASG_01_Header 3;
BA_ "GenSigSwitchedByIgnition" SG_ 2536707088 BAP_Homelink_FSG_01_Header 0;
BA_ "GenSigSendType" SG_ 2536707088 BAP_Homelink_FSG_01_Header 3;
BA_ "GenSigSwitchedByIgnition" SG_ 2536704000 BAP_Innenlicht_ASG_01_Header 0;
BA_ "GenSigSendType" SG_ 2536704000 BAP_Innenlicht_ASG_01_Header 3;
BA_ "GenSigSwitchedByIgnition" SG_ 2536704016 BAP_Innenlicht_FSG_01_Header 0;
BA_ "GenSigSendType" SG_ 2536704016 BAP_Innenlicht_FSG_01_Header 3;
BA_ "GenSigSwitchedByIgnition" SG_ 2536702211 BAP_Klima1_ASG_04_Header 0;
BA_ "GenSigSendType" SG_ 2536702211 BAP_Klima1_ASG_04_Header 3;
BA_ "GenSigSwitchedByIgnition" SG_ 2536702224 BAP_Klima1_FSG_01_Header 0;
BA_ "GenSigSendType" SG_ 2536702224 BAP_Klima1_FSG_01_Header 3;
BA_ "GenSigSwitchedByIgnition" SG_ 2536705536 BAP_Mirror_ASG_01_Header 0;
BA_ "GenSigSendType" SG_ 2536705536 BAP_Mirror_ASG_01_Header 3;
BA_ "GenSigSwitchedByIgnition" SG_ 2536705552 BAP_Mirror_FSG_01_Header 0;
BA_ "GenSigSendType" SG_ 2536705552 BAP_Mirror_FSG_01_Header 3;
BA_ "GenSigSwitchedByIgnition" SG_ 2536704512 BAP_OPS_ASG_01_Header 0;
BA_ "GenSigSendType" SG_ 2536704512 BAP_OPS_ASG_01_Header 3;
BA_ "GenSigSwitchedByIgnition" SG_ 2536704513 BAP_OPS_ASG_02_Header 0;
BA_ "GenSigSendType" SG_ 2536704513 BAP_OPS_ASG_02_Header 3;
BA_ "GenSigSwitchedByIgnition" SG_ 2536704528 BAP_OPS_FSG_01_Header 0;
BA_ "GenSigSendType" SG_ 2536704528 BAP_OPS_FSG_01_Header 3;
BA_ "GenSigSwitchedByIgnition" SG_ 2536704529 BAP_OPS_FSG_02_Header 0;
BA_ "GenSigSendType" SG_ 2536704529 BAP_OPS_FSG_02_Header 3;
BA_ "GenSigSwitchedByIgnition" SG_ 2536702722 BAP_ParkHeater_ASG_03_Header 0;
BA_ "GenSigSendType" SG_ 2536702722 BAP_ParkHeater_ASG_03_Header 3;
BA_ "GenSigSwitchedByIgnition" SG_ 2536702736 BAP_ParkHeater_FSG_01_Header 0;
BA_ "GenSigSendType" SG_ 2536702736 BAP_ParkHeater_FSG_01_Header 3;
BA_ "GenSigSwitchedByIgnition" SG_ 2536703746 BAP_RDK_ASG_03_Header 0;
BA_ "GenSigSendType" SG_ 2536703746 BAP_RDK_ASG_03_Header 3;
BA_ "GenSigSwitchedByIgnition" SG_ 2536703760 BAP_RDK_FSG_01_Header 0;
BA_ "GenSigSendType" SG_ 2536703760 BAP_RDK_FSG_01_Header 3;
BA_ "GenSigSwitchedByIgnition" SG_ 2536713728 BAP_RSE_ASG_01_Header 0;
BA_ "GenSigSendType" SG_ 2536713728 BAP_RSE_ASG_01_Header 3;
BA_ "GenSigSwitchedByIgnition" SG_ 2536713729 BAP_RSE_ASG_02_Header 0;
BA_ "GenSigSendType" SG_ 2536713729 BAP_RSE_ASG_02_Header 3;
BA_ "GenSigSwitchedByIgnition" SG_ 2536713744 BAP_RSE_FSG_01_Header 0;
BA_ "GenSigSendType" SG_ 2536713744 BAP_RSE_FSG_01_Header 3;
BA_ "GenSigSwitchedByIgnition" SG_ 2536718080 BAP_SeatCoDriverRear_ASG_01 0;
BA_ "GenSigSendType" SG_ 2536718080 BAP_SeatCoDriverRear_ASG_01 3;
BA_ "GenSigSwitchedByIgnition" SG_ 2536718081 BAP_SeatCoDriverRear_ASG_02 0;
BA_ "GenSigSendType" SG_ 2536718081 BAP_SeatCoDriverRear_ASG_02 3;
BA_ "GenSigSwitchedByIgnition" SG_ 2536718096 BAP_SeatCoDriverRear_FSG_01 0;
BA_ "GenSigSendType" SG_ 2536718096 BAP_SeatCoDriverRear_FSG_01 3;
BA_ "GenSigSwitchedByIgnition" SG_ 2536717824 BAP_SeatDriverRear_ASG_01 0;
BA_ "GenSigSendType" SG_ 2536717824 BAP_SeatDriverRear_ASG_01 3;
BA_ "GenSigSwitchedByIgnition" SG_ 2536717825 BAP_SeatDriverRear_ASG_02 0;
BA_ "GenSigSendType" SG_ 2536717825 BAP_SeatDriverRear_ASG_02 3;
BA_ "GenSigSwitchedByIgnition" SG_ 2536717840 BAP_SeatDriverRear_FSG_01 0;
BA_ "GenSigSendType" SG_ 2536717840 BAP_SeatDriverRear_FSG_01 3;
BA_ "GenSigSwitchedByIgnition" SG_ 2536717056 BAP_SeatPneumatic_ASG_01_Header 0;
BA_ "GenSigSendType" SG_ 2536717056 BAP_SeatPneumatic_ASG_01_Header 3;
BA_REL_ "GenSigTimeoutTime" BU_SG_REL_ BCM2 SG_ 302 CBM_Warnblinken 500;
BA_REL_ "GenSigTimeoutTime" BU_SG_REL_ BCM1 SG_ 680 ACC_Status_Anzeige 2000;
BA_REL_ "GenSigTimeoutTime" BU_SG_REL_ BCM2 SG_ 64 Airbag_01_CRC 500;
BA_REL_ "GenSigTimeoutTime" BU_SG_REL_ SitzMem_BFS SG_ 64 Airbag_01_CRC 500;
BA_REL_ "GenSigTimeoutTime" BU_SG_REL_ SitzMem_FS SG_ 64 Airbag_01_CRC 500;
BA_REL_ "GenSigTimeoutTime" BU_SG_REL_ SitzMem_HBFS SG_ 64 Airbag_01_CRC 500;
BA_REL_ "GenSigTimeoutTime" BU_SG_REL_ SitzMem_HFS SG_ 64 Airbag_01_CRC 500;
BA_REL_ "GenSigTimeoutTime" BU_SG_REL_ SitzMem_SR3 SG_ 64 Airbag_01_CRC 500;
BA_REL_ "GenSigTimeoutTime" BU_SG_REL_ BCM2 SG_ 64 Airbag_01_BZ 500;
BA_REL_ "GenSigTimeoutTime" BU_SG_REL_ SitzMem_BFS SG_ 64 Airbag_01_BZ 500;
BA_REL_ "GenSigTimeoutTime" BU_SG_REL_ SitzMem_FS SG_ 64 Airbag_01_BZ 500;
BA_REL_ "GenSigTimeoutTime" BU_SG_REL_ SitzMem_HBFS SG_ 64 Airbag_01_BZ 500;
BA_REL_ "GenSigTimeoutTime" BU_SG_REL_ SitzMem_HFS SG_ 64 Airbag_01_BZ 500;
BA_REL_ "GenSigTimeoutTime" BU_SG_REL_ SitzMem_SR3 SG_ 64 Airbag_01_BZ 500;
BA_REL_ "GenSigTimeoutTime" BU_SG_REL_ BCM2 SG_ 64 AB_Front_Crash 500;
BA_REL_ "GenSigTimeoutTime" BU_SG_REL_ SitzMem_BFS SG_ 64 AB_Front_Crash 500;
BA_REL_ "GenSigTimeoutTime" BU_SG_REL_ SitzMem_FS SG_ 64 AB_Front_Crash 500;
BA_REL_ "GenSigTimeoutTime" BU_SG_REL_ SitzMem_HBFS SG_ 64 AB_Front_Crash 500;
BA_REL_ "GenSigTimeoutTime" BU_SG_REL_ SitzMem_HFS SG_ 64 AB_Front_Crash 500;
BA_REL_ "GenSigTimeoutTime" BU_SG_REL_ SitzMem_SR3 SG_ 64 AB_Front_Crash 500;
BA_REL_ "GenSigTimeoutTime" BU_SG_REL_ VTS SG_ 64 AB_Front_Crash 500;
BA_REL_ "GenSigTimeoutTime" BU_SG_REL_ BCM2 SG_ 64 AB_Heck_Crash 500;
BA_REL_ "GenSigTimeoutTime" BU_SG_REL_ SitzMem_BFS SG_ 64 AB_Heck_Crash 500;
BA_REL_ "GenSigTimeoutTime" BU_SG_REL_ SitzMem_FS SG_ 64 AB_Heck_Crash 500;
BA_REL_ "GenSigTimeoutTime" BU_SG_REL_ SitzMem_HBFS SG_ 64 AB_Heck_Crash 500;
BA_REL_ "GenSigTimeoutTime" BU_SG_REL_ SitzMem_HFS SG_ 64 AB_Heck_Crash 500;
BA_REL_ "GenSigTimeoutTime" BU_SG_REL_ SitzMem_SR3 SG_ 64 AB_Heck_Crash 500;
BA_REL_ "GenSigTimeoutTime" BU_SG_REL_ VTS SG_ 64 AB_Heck_Crash 500;
BA_REL_ "GenSigTimeoutTime" BU_SG_REL_ BCM2 SG_ 64 AB_SF_Crash 500;
BA_REL_ "GenSigTimeoutTime" BU_SG_REL_ SitzMem_BFS SG_ 64 AB_SF_Crash 500;
BA_REL_ "GenSigTimeoutTime" BU_SG_REL_ SitzMem_FS SG_ 64 AB_SF_Crash 500;
BA_REL_ "GenSigTimeoutTime" BU_SG_REL_ SitzMem_HBFS SG_ 64 AB_SF_Crash 500;
BA_REL_ "GenSigTimeoutTime" BU_SG_REL_ SitzMem_HFS SG_ 64 AB_SF_Crash 500;
BA_REL_ "GenSigTimeoutTime" BU_SG_REL_ SitzMem_SR3 SG_ 64 AB_SF_Crash 500;
BA_REL_ "GenSigTimeoutTime" BU_SG_REL_ TSG_BFS SG_ 64 AB_SF_Crash 500;
BA_REL_ "GenSigTimeoutTime" BU_SG_REL_ TSG_FS SG_ 64 AB_SF_Crash 500;
BA_REL_ "GenSigTimeoutTime" BU_SG_REL_ VTS SG_ 64 AB_SF_Crash 500;
BA_REL_ "GenSigTimeoutTime" BU_SG_REL_ BCM2 SG_ 64 AB_SB_Crash 500;
BA_REL_ "GenSigTimeoutTime" BU_SG_REL_ SitzMem_BFS SG_ 64 AB_SB_Crash 500;
BA_REL_ "GenSigTimeoutTime" BU_SG_REL_ SitzMem_FS SG_ 64 AB_SB_Crash 500;
BA_REL_ "GenSigTimeoutTime" BU_SG_REL_ SitzMem_HBFS SG_ 64 AB_SB_Crash 500;
BA_REL_ "GenSigTimeoutTime" BU_SG_REL_ SitzMem_HFS SG_ 64 AB_SB_Crash 500;
BA_REL_ "GenSigTimeoutTime" BU_SG_REL_ SitzMem_SR3 SG_ 64 AB_SB_Crash 500;
BA_REL_ "GenSigTimeoutTime" BU_SG_REL_ TSG_BFS SG_ 64 AB_SB_Crash 500;
BA_REL_ "GenSigTimeoutTime" BU_SG_REL_ TSG_FS SG_ 64 AB_SB_Crash 500;
BA_REL_ "GenSigTimeoutTime" BU_SG_REL_ VTS SG_ 64 AB_SB_Crash 500;
BA_REL_ "GenSigTimeoutTime" BU_SG_REL_ BCM2 SG_ 64 AB_Rollover_Crash 500;
BA_REL_ "GenSigTimeoutTime" BU_SG_REL_ SitzMem_BFS SG_ 64 AB_Rollover_Crash 500;
BA_REL_ "GenSigTimeoutTime" BU_SG_REL_ SitzMem_FS SG_ 64 AB_Rollover_Crash 500;
BA_REL_ "GenSigTimeoutTime" BU_SG_REL_ SitzMem_HBFS SG_ 64 AB_Rollover_Crash 500;
BA_REL_ "GenSigTimeoutTime" BU_SG_REL_ SitzMem_HFS SG_ 64 AB_Rollover_Crash 500;
BA_REL_ "GenSigTimeoutTime" BU_SG_REL_ SitzMem_SR3 SG_ 64 AB_Rollover_Crash 500;
BA_REL_ "GenSigTimeoutTime" BU_SG_REL_ TSG_BFS SG_ 64 AB_Rollover_Crash 500;
BA_REL_ "GenSigTimeoutTime" BU_SG_REL_ TSG_FS SG_ 64 AB_Rollover_Crash 500;
BA_REL_ "GenSigTimeoutTime" BU_SG_REL_ VTS SG_ 64 AB_Rollover_Crash 500;
BA_REL_ "GenSigTimeoutTime" BU_SG_REL_ BCM1 SG_ 64 AB_Crash_Int 500;
BA_REL_ "GenSigTimeoutTime" BU_SG_REL_ SitzMem_BFS SG_ 64 AB_Crash_Int 500;
BA_REL_ "GenSigTimeoutTime" BU_SG_REL_ SitzMem_FS SG_ 64 AB_Crash_Int 500;
BA_REL_ "GenSigTimeoutTime" BU_SG_REL_ SitzMem_HBFS SG_ 64 AB_Crash_Int 500;
BA_REL_ "GenSigTimeoutTime" BU_SG_REL_ SitzMem_HFS SG_ 64 AB_Crash_Int 500;
BA_REL_ "GenSigTimeoutTime" BU_SG_REL_ SitzMem_SR3 SG_ 64 AB_Crash_Int 500;
BA_REL_ "GenSigTimeoutTime" BU_SG_REL_ TSG_BFS SG_ 64 AB_Crash_Int 500;
BA_REL_ "GenSigTimeoutTime" BU_SG_REL_ TSG_FS SG_ 64 AB_Crash_Int 500;
BA_REL_ "GenSigTimeoutTime" BU_SG_REL_ VTS SG_ 64 AB_Crash_Int 500;
BA_REL_ "GenSigTimeoutTime" BU_SG_REL_ VTS SG_ 64 AB_Lampe 500;
BA_REL_ "GenSigTimeoutTime" BU_SG_REL_ VTS SG_ 64 AB_Stellgliedtest 500;
BA_REL_ "GenSigTimeoutTime" BU_SG_REL_ VTS SG_ 64 AB_Gurtwarn_VF 500;
BA_REL_ "GenSigTimeoutTime" BU_SG_REL_ VTS SG_ 64 AB_Gurtwarn_VB 500;
BA_REL_ "GenSigTimeoutTime" BU_SG_REL_ SitzMem_BFS SG_ 1312 Airbag_02_CRC 2000;
BA_REL_ "GenSigTimeoutTime" BU_SG_REL_ SitzMem_BFS SG_ 1312 Airbag_02_BZ 2000;
BA_REL_ "GenSigTimeoutTime" BU_SG_REL_ BCM1 SG_ 1312 AB_Belegung_VB 2000;
BA_REL_ "GenSigTimeoutTime" BU_SG_REL_ SitzMem_BFS SG_ 1312 AB_Belegung_VB 2000;
BA_REL_ "GenSigTimeoutTime" BU_SG_REL_ TSG_BFS SG_ 1312 AB_Belegung_VB 2000;
BA_REL_ "GenSigTimeoutTime" BU_SG_REL_ TSG_FS SG_ 1312 AB_Belegung_VB 2000;
BA_REL_ "GenSigTimeoutTime" BU_SG_REL_ BCM1 SG_ 1312 AB_Abschaltanf_SIH_BF 2000;
BA_REL_ "GenSigTimeoutTime" BU_SG_REL_ BCM1 SG_ 1312 SC_PAO_Schriftzug_Anf 2000;
BA_REL_ "GenSigTimeoutTime" BU_SG_REL_ BCM1 SG_ 1312 SC_PAO_ON_Anf 2000;
BA_REL_ "GenSigTimeoutTime" BU_SG_REL_ BCM1 SG_ 1312 SC_PAO_OFF_Anf 2000;
BA_REL_ "GenSigTimeoutTime" BU_SG_REL_ BCM1 SG_ 1312 AB_Gurtschloss_FA 2000;
BA_REL_ "GenSigTimeoutTime" BU_SG_REL_ BCM2 SG_ 1312 AB_Gurtschloss_FA 2000;
BA_REL_ "GenSigTimeoutTime" BU_SG_REL_ TSG_BFS SG_ 1312 AB_Gurtschloss_FA 2000;
BA_REL_ "GenSigTimeoutTime" BU_SG_REL_ VTS SG_ 1312 AB_Gurtschloss_FA 2000;
BA_REL_ "GenSigTimeoutTime" BU_SG_REL_ BCM1 SG_ 1312 AB_Gurtschloss_BF 2000;
BA_REL_ "GenSigTimeoutTime" BU_SG_REL_ SitzMem_BFS SG_ 1312 AB_Gurtschloss_BF 2000;
BA_REL_ "GenSigTimeoutTime" BU_SG_REL_ TSG_BFS SG_ 1312 AB_Gurtschloss_BF 2000;
BA_REL_ "GenSigTimeoutTime" BU_SG_REL_ VTS SG_ 1312 AB_Gurtschloss_BF 2000;
BA_REL_ "GenSigTimeoutTime" BU_SG_REL_ BCM1 SG_ 1312 AB_Gurtschloss_Reihe2_FA 2000;
BA_REL_ "GenSigTimeoutTime" BU_SG_REL_ SitzMem_HFS SG_ 1312 AB_Gurtschloss_Reihe2_FA 2000;
BA_REL_ "GenSigTimeoutTime" BU_SG_REL_ TSG_FS SG_ 1312 AB_Gurtschloss_Reihe2_FA 2000;
BA_REL_ "GenSigTimeoutTime" BU_SG_REL_ BCM1 SG_ 1312 AB_Gurtschloss_Reihe2_MI 2000;
BA_REL_ "GenSigTimeoutTime" BU_SG_REL_ BCM1 SG_ 1312 AB_Gurtschloss_Reihe2_BF 2000;
BA_REL_ "GenSigTimeoutTime" BU_SG_REL_ SitzMem_HBFS SG_ 1312 AB_Gurtschloss_Reihe2_BF 2000;
BA_REL_ "GenSigTimeoutTime" BU_SG_REL_ TSG_FS SG_ 1312 AB_Gurtschloss_Reihe2_BF 2000;
BA_REL_ "GenSigTimeoutTime" BU_SG_REL_ TSG_BFS SG_ 1312 AB_Sitzpos_Sens_FA 2000;
BA_REL_ "GenSigTimeoutTime" BU_SG_REL_ TSG_FS SG_ 1312 AB_Sitzpos_Sens_FA 2000;
BA_REL_ "GenSigTimeoutTime" BU_SG_REL_ SitzMem_BFS SG_ 1312 AB_Sitzpos_Sens_BF 2000;
BA_REL_ "GenSigTimeoutTime" BU_SG_REL_ SitzMem_FS SG_ 1312 AB_Sitzpos_Sens_BF 2000;
BA_REL_ "GenSigTimeoutTime" BU_SG_REL_ SitzMem_HBFS SG_ 1312 AB_Sitzpos_Sens_BF 2000;
BA_REL_ "GenSigTimeoutTime" BU_SG_REL_ TSG_BFS SG_ 1312 AB_Sitzpos_Sens_BF 2000;
BA_REL_ "GenSigTimeoutTime" BU_SG_REL_ TSG_FS SG_ 1312 AB_Sitzpos_Sens_BF 2000;
BA_REL_ "GenSigTimeoutTime" BU_SG_REL_ BCM2 SG_ 1633 AAG_BZ 1000;
BA_REL_ "GenSigTimeoutTime" BU_SG_REL_ BCM1 SG_ 1633 AAG_Anhaenger_abgesteckt 1000;
BA_REL_ "GenSigTimeoutTime" BU_SG_REL_ MFG SG_ 1633 AAG_Anhaenger_abgesteckt 1000;
BA_REL_ "GenSigTimeoutTime" BU_SG_REL_ BCM1 SG_ 1633 AAG_NSL_aktiv 1000;
BA_REL_ "GenSigTimeoutTime" BU_SG_REL_ BCM1 SG_ 1633 AAG_Anhaenger_erkannt 1000;
BA_REL_ "GenSigTimeoutTime" BU_SG_REL_ BCM2 SG_ 1633 AAG_Anhaenger_erkannt 1000;
BA_REL_ "GenSigTimeoutTime" BU_SG_REL_ Gateway SG_ 1633 AAG_Anhaenger_erkannt 1000;
BA_REL_ "GenSigTimeoutTime" BU_SG_REL_ HDSG SG_ 1633 AAG_Anhaenger_erkannt 1000;
BA_REL_ "GenSigTimeoutTime" BU_SG_REL_ VTS SG_ 1633 AAG_Anhaenger_erkannt 1000;
BA_REL_ "GenSigTimeoutTime" BU_SG_REL_ MFG SG_ 1633 AAG_Blinker_H_aktiv 1000;
BA_REL_ "GenSigTimeoutTime" BU_SG_REL_ BCM1 SG_ 1633 AAG_AVS_Fehler_02 1000;
BA_REL_ "GenSigTimeoutTime" BU_SG_REL_ BCM1 SG_ 1633 AAG_AVS_Stati 1000;
BA_REL_ "GenSigTimeoutTime" BU_SG_REL_ VTS SG_ 1633 AAG_AVS_Stati 1000;
BA_REL_ "GenSigTimeoutTime" BU_SG_REL_ BCM1 SG_ 344 ARA_Sensor_Knickwgeschw 1000;
BA_REL_ "GenSigTimeoutTime" BU_SG_REL_ BCM1 SG_ 344 ARA_Sensor_Sektoren 1000;
BA_REL_ "GenSigTimeoutTime" BU_SG_REL_ BCM1 SG_ 344 ARA_Sensor_Knickw_Rohwert 1000;
BA_REL_ "GenSigTimeoutTime" BU_SG_REL_ BCM1 SG_ 344 ARA_Sensor_Signal_red_cyclic 1000;
BA_REL_ "GenSigTimeoutTime" BU_SG_REL_ BCM1 SG_ 344 ARA_Sensor_Knickwgeschw_upd 1000;
BA_REL_ "GenSigTimeoutTime" BU_SG_REL_ BCM1 SG_ 344 ARA_Sensor_Knickw_Rohwert_upd 1000;
BA_REL_ "GenSigTimeoutTime" BU_SG_REL_ AAG SG_ 345 ARA_Status 1000;
BA_REL_ "GenSigTimeoutTime" BU_SG_REL_ BCM1 SG_ 1365 AV_Umfeldbeleuchtung_Anf 5000;
VAL_ 2617058113 SAD_TM_rollo_sw_state 5 "Unknown" 4 "2nd detect open" 3 "2nd detect close" 2 "1st detent open" 1 "1st detent close" 0 "Idle" ;
VAL_ 2617058113 SAD_TM_sunroof_sw_state 9 "unknown" 8 "Tilt 2nd open" 7 "Tilt 2nd close" 6 "Tilt 1st open" 5 "Tilt 1st close" 4 "Slide 2nd open" 3 "Slide 2nd close" 2 "Slide 1st open" 1 "Slide 1st close" 0 "Idle" ;
VAL_ 2617058112 SAD_TM_sunroof_sw_expected 9 "unknown" 8 "Tilt 2nd open" 7 "Tilt 2nd close" 6 "Tilt 1st open" 5 "Tilt 1st close" 4 "Slide 2nd open" 3 "Slide 2nd close" 2 "Slide 1st open" 1 "Slide 1st close" 0 "Idle" ;
VAL_ 2617058112 SAD_TM_rollo_sw_expected 5 "Unknown" 4 "2nd detect open" 3 "2nd detect close" 2 "1st detent open" 1 "1st detent close" 0 "Idle" ;
VAL_ 2617058112 SAD_TM_Mode 0 "None" 1 "Monitor" 2 "Control" ;
VAL_ 2617058161 SAD_L99H01_B_Error 0 "None" 1 "Info" 2 "Warning" 3 "Temporary" 4 "Critical" ;
VAL_ 2617058161 SAD_L99H01_B_State 0 "Break" 1 "Active" 2 "Tristate" ;
VAL_ 2617058160 SAD_L99H01_B_OVT 1 "29V" 0 "20V" ;
VAL_ 2617058160 SAD_L99H01_B_FW 1 "High-side" 0 "Low-side" ;
VAL_ 2617058160 SAD_L99H01_B_CLK_SPCTR 1 "Pulse Train" 0 "125kHz" ;
VAL_ 2617058160 SAD_L99H01_B_EXTTH_n 7 "0" 6 "1" 5 "2" 4 "3" 3 "4" 2 "5" 1 "6" 0 "7" ;
VAL_ 2617058160 SAD_L99H01_B_DIAG 3 "2.0V" 2 "1.5V" 1 "1.0V" 0 "0.5V" ;
VAL_ 2617058160 SAD_L99H01_B_EXTTH_m 7 "0" 6 "1" 5 "2" 4 "3" 3 "4" 2 "5" 1 "6" 0 "7" ;
VAL_ 2617058160 SAD_L99H01_B_COPT 7 "2000 ns" 6 "1750 ns" 5 "1500 ns" 4 "1250 ns" 3 "1000 ns" 2 "750 ns" 1 "500 ns" 0 "250 ns" ;
VAL_ 2617058145 SAD_L99H01_A_Error 0 "None" 1 "Info" 2 "Warning" 3 "Temporary" 4 "Critical" ;
VAL_ 2617058145 SAD_L99H01_A_State 0 "Break" 1 "Active" 2 "Tristate" ;
VAL_ 2617058144 SAD_L99H01_A_OVT 1 "29V" 0 "20V" ;
VAL_ 2617058144 SAD_L99H01_A_FW 1 "High-side" 0 "Low-side" ;
VAL_ 2617058144 SAD_L99H01_A_CLK_SPCTR 1 "Pulse Train" 0 "125kHz" ;
VAL_ 2617058144 SAD_L99H01_A_EXTTH_n 7 "0" 6 "1" 5 "2" 4 "3" 3 "4" 2 "5" 1 "6" 0 "7" ;
VAL_ 2617058144 SAD_L99H01_A_DIAG 3 "2.0V" 2 "1.5V" 1 "1.0V" 0 "0.5V" ;
VAL_ 2617058144 SAD_L99H01_A_EXTTH_m 7 "0" 6 "1" 5 "2" 4 "3" 3 "4" 2 "5" 1 "6" 0 "7" ;
VAL_ 2617058144 SAD_L99H01_A_COPT 7 "2000 ns" 6 "1750 ns" 5 "1500 ns" 4 "1250 ns" 3 "1000 ns" 2 "750 ns" 1 "500 ns" 0 "250 ns" ;
VAL_ 2616992577 SAD_TM_rollo_sw_state 5 "Unknown" 4 "2nd detect open" 3 "2nd detect close" 2 "1st detent open" 1 "1st detent close" 0 "Idle" ;
VAL_ 2616992577 SAD_TM_sunroof_sw_state 9 "unknown" 8 "Tilt 2nd open" 7 "Tilt 2nd close" 6 "Tilt 1st open" 5 "Tilt 1st close" 4 "Slide 2nd open" 3 "Slide 2nd close" 2 "Slide 1st open" 1 "Slide 1st close" 0 "Idle" ;
VAL_ 2616992576 SAD_TM_sunroof_sw_expected 9 "unknown" 8 "Tilt 2nd open" 7 "Tilt 2nd close" 6 "Tilt 1st open" 5 "Tilt 1st close" 4 "Slide 2nd open" 3 "Slide 2nd close" 2 "Slide 1st open" 1 "Slide 1st close" 0 "Idle" ;
VAL_ 2616992576 SAD_TM_rollo_sw_expected 5 "Unknown" 4 "2nd detect open" 3 "2nd detect close" 2 "1st detent open" 1 "1st detent close" 0 "Idle" ;
VAL_ 2616992576 SAD_TM_Mode 0 "None" 1 "Monitor" 2 "Control" ;
VAL_ 2616992624 SAD_L99H01_B_OVT 1 "29V" 0 "20V" ;
VAL_ 2616992624 SAD_L99H01_B_FW 1 "High-side" 0 "Low-side" ;
VAL_ 2616992624 SAD_L99H01_B_CLK_SPCTR 1 "Pulse Train" 0 "125kHz" ;
VAL_ 2616992624 SAD_L99H01_B_EXTTH_n 7 "0" 6 "1" 5 "2" 4 "3" 3 "4" 2 "5" 1 "6" 0 "7" ;
VAL_ 2616992624 SAD_L99H01_B_DIAG 3 "2.0V" 2 "1.5V" 1 "1.0V" 0 "0.5V" ;
VAL_ 2616992624 SAD_L99H01_B_EXTTH_m 7 "0" 6 "1" 5 "2" 4 "3" 3 "4" 2 "5" 1 "6" 0 "7" ;
VAL_ 2616992624 SAD_L99H01_B_COPT 7 "2000 ns" 6 "1750 ns" 5 "1500 ns" 4 "1250 ns" 3 "1000 ns" 2 "750 ns" 1 "500 ns" 0 "250 ns" ;
VAL_ 2616992608 SAD_L99H01_A_OVT 1 "29V" 0 "20V" ;
VAL_ 2616992608 SAD_L99H01_A_FW 1 "High-side" 0 "Low-side" ;
VAL_ 2616992608 SAD_L99H01_A_CLK_SPCTR 1 "Pulse Train" 0 "125kHz" ;
VAL_ 2616992608 SAD_L99H01_A_EXTTH_n 7 "0" 6 "1" 5 "2" 4 "3" 3 "4" 2 "5" 1 "6" 0 "7" ;
VAL_ 2616992608 SAD_L99H01_A_DIAG 3 "2.0V" 2 "1.5V" 1 "1.0V" 0 "0.5V" ;
VAL_ 2616992608 SAD_L99H01_A_EXTTH_m 7 "0" 6 "1" 5 "2" 4 "3" 3 "4" 2 "5" 1 "6" 0 "7" ;
VAL_ 2616992608 SAD_L99H01_A_COPT 7 "2000 ns" 6 "1750 ns" 5 "1500 ns" 4 "1250 ns" 3 "1000 ns" 2 "750 ns" 1 "500 ns" 0 "250 ns" ;
VAL_ 2616992625 SAD_L99H01_B_Error 0 "None" 1 "Info" 2 "Warning" 3 "Temporary" 4 "Critical" ;
VAL_ 2616992625 SAD_L99H01_B_State 0 "Break" 1 "Active" 2 "Tristate" ;
VAL_ 2616992609 SAD_L99H01_A_Error 0 "None" 1 "Info" 2 "Warning" 3 "Temporary" 4 "Critical" ;
VAL_ 2616992609 SAD_L99H01_A_State 0 "Break" 1 "Active" 2 "Tristate" ;
VAL_ 302 ACC_Anhalteweg 2046 "Neutralwert" 2047 "Fehler" ;
VAL_ 302 ACC_Anhalten 0 "kein_Anhalten_gewuenscht" 1 "Anhalten_gewuenscht" ;
VAL_ 302 ACC_Freilauf_Anf 0 "keine Freilauf-Anforderung" 1 "Freilauf-Anforderung" ;
VAL_ 302 ACC_Freilauf_Info 0 "Freilauf_freigegeben" 1 "kein_Uebergang_in_Freilauf_zulaessig" 2 "Freilauf_nicht_freigegeben" 3 "Freilauf_Anforderung" ;
VAL_ 302 ACC_Anforderung_HMS 0 "keine_Anforderung" 1 "halten" 2 "parken" 3 "halten_Standby" 4 "anfahren" 5 "Loesen_ueber_Rampe" ;
VAL_ 302 STA_Anf_BVS_unterdruecken 0 "kein_Fehler" 1 "Fehler_Winkelregelung_abbrechen" 2 "Fehler_Winkelregelung_einfrieren" ;
VAL_ 302 STA_Status_HC 0 "aus" 2 "passiv" 3 "aktiv" 6 "ausrampen_moderat" 7 "ausrampen_schnell" 9 "einfrieren" 10 "Fehler" 14 "Initialisierung" ;
VAL_ 302 STA_Verzoeg_Anf_Freigabe 0 "nicht_freigegeben" 1 "freigegeben" ;
VAL_ 302 STA_Verzoeg_Anf 127 "Neutralwert" ;
VAL_ 302 CBM_Warnblinken 0 "aus" 1 "statisch" 2 "Taster" 3 "nicht_definiert" ;
VAL_ 302 STA_Anforderung_HMS 0 "keine_Anforderung" 1 "halten" 2 "parken" 3 "halten_Standby" 4 "anfahren" 5 "Loesen_ueber_Rampe" ;
VAL_ 302 ACC_Folgebeschl 254 "Neutralwert" ;
VAL_ 680 ACC_Texte_Abstandswarner 0 "keine_Anzeige" 1 "Systemstoerung" 2 "keine_Sensorsicht" 3 "zurzeit_eingeschraenkt" ;
VAL_ 680 ACC_Vorz_Abstandswarner 0 "keine_Anzeige" 1 "kleiner" 2 "groesser" 3 "kleiner_Warnung" ;
VAL_ 680 ACC_Texte_Sekundaeranz 0 "keine_Anzeige" 1 "Zielfahrzeug_erkannt" 2 "Rechtskurve_voraus" 3 "Linkskurve_voraus" 4 "Tempolimit_voraus" 5 "Sensorsicht" 6 "Anfahrbereit" 7 "Tempolimit_erkannt" 8 "Kreuzung_voraus" 9 "Kreisverkehr_voraus" ;
VAL_ 680 ACC_Status_Anzeige 0 "ACC_GRA_Hauptschalter_aus" 1 "ACC_in_Init_nicht_bei_GRA" 2 "ACC_GRA_passiv" 3 "ACC_GRA_aktiv" 4 "ACC_GRA_im_Hintergrund_uebertreten" 5 "ACC_GRA_Abschaltreaktion" 6 "ACC_reversibel_aus_nicht_bei_GRA" 7 "ACC_GRA_irreversibel_aus" ;
VAL_ 680 ACC_Akustik_03 0 "keine_Akustik" 1 "niederpriore_Akustik" 2 "mittelpriore_Akustik" 3 "hochpriore_Akustik" 4 "hochpriore_Dauerakustik" ;
VAL_ 680 ACC_Texte 0 "keine_Anzeige" 1 "ACC_nicht_verfuegbar" 2 "ACC_und_AWV_nicht_verfuegbar" 3 "ACC_keine_Sensorsicht" 4 "ACC_und_AWV_keine_Sensorsicht" 5 "ACC_Steigung_zu_gross" 6 "ACC_nur_in_Fahrstufe_verfuegbar" 7 "ACC_Parkbremse_betaetigt" 8 "ACC_ESP_Eingriff" 9 "ACC_Bitte_uebernehmen" 10 "ACC_HDC_betaetigt" 11 "ACC_Geschwindigkeitsgrenze" 12 "ACC_Schalthebelposition" 13 "ACC_Drehzahl" 14 "ACC_Kupplung_betaetigt" 15 "ACC_Aktivierverhinderung" 16 "ACC_Abschaltung" 17 "ACC_Parkassistent_aktiv" 18 "ACC_ESC_aus" ;
VAL_ 680 ACC_STA_Text 0 "ACC_Text" 1 "ACC_STA_Text" ;
VAL_ 680 STA_Texte 0 "keine_Anzeige" 1 "STA_nicht_verfuegbar" 2 "STA_Fahreruebernahme" 3 "STA_Constant_brake_mode" 4 "STA_Gurtschloss_nicht_gesteckt" 5 "STA_Fahrzeugeschw_zu_hoch" 6 "STA_Freifahrt" ;
VAL_ 680 STA_Zusatzanz 0 "keine_Anzeige" 1 "STA_verfuegbar" 2 "STA_aktiv" 3 "STA_Warnung" ;
VAL_ 680 ACC_Zeitluecke_Abstandswarner 61 "Freifahrt" 62 "nicht_definiert" 63 "keine_Anzeige" ;
VAL_ 680 ACC_Abstand_Abstandswarner 509 "Freifahrt" 510 "nicht_definiert" 511 "keine_Anzeige" ;
VAL_ 680 ACC_Einheit_Abstandswarner 0 "Meter" 1 "Yard" ;
VAL_ 64 AB_RGS_Anst 4 "aktiv_Niveau_1" 5 "aktiv_Niveau_2" 6 "aktiv_Niveau_3" 7 "aktiv_Niveau_4" 8 "deaktiviert" ;
VAL_ 64 AB_Front_Crash 0 "kein_Front_Crash" 1 "Front_Crash" ;
VAL_ 64 AB_Heck_Crash 0 "kein_Heck_Crash" 1 "Heck_Crash" ;
VAL_ 64 AB_SF_Crash 0 "kein_Seiten_Crash_Fahrer" 1 "Seiten_Crash_Fahrer" ;
VAL_ 64 AB_SB_Crash 0 "kein_Seiten_Crash_Beifahrer" 1 "Seiten_Crash_Beifahrer" ;
VAL_ 64 AB_Rollover_Crash 0 "kein_Rollover" 1 "Rollover" ;
VAL_ 64 AB_Crash_Int 0 "kein_Crash" 1 "Crash_Intensitaet_1" 2 "Crash_Intensitaet_2_(nur_Stellgliedtest_MLB_B8)" 3 "Crash_Intensitaet_2_(nur_D4_C7_Colorado_NF_PAG__Crash_im_MLB_B8)" 4 "Crash_Intensitaet_3_(alt_VW/AUDI__Stellgliedtest_MLB_B8)" 5 "Crash_Intensitaet_3_(alt_PAG)" 7 "Crash_Intensitaet_3" ;
VAL_ 64 AB_Lampe 0 "Aus" 1 "Ein" ;
VAL_ 64 AB_Deaktiviert 0 "aktiv" 1 "deaktiviert" ;
VAL_ 64 AB_VB_deaktiviert 0 "Beifahrerairbag_aktiv" 1 "Beifahrerairbag_deaktiviert" ;
VAL_ 64 AB_Systemfehler 0 "kein_Fehler" 1 "Airbag_Systemfehler" ;
VAL_ 64 AB_Diagnose 0 "nicht_in_Diagnose" 1 "in_Diagnose" ;
VAL_ 64 AB_Stellgliedtest 0 "nicht_im_Stellgliedtest" 1 "Airbag_im_Stellgliedtest" ;
VAL_ 64 AB_Erh_Auf_VB 0 "keine_Anzeige" 1 "Beifahrerairbag_deaktiviert" 2 "Beifahrerairbag_aktiviert" 3 "nicht_definiert" ;
VAL_ 64 AB_Gurtwarn_VF 0 "keine_Warnung" 1 "Gurtwarnung_ausloesen" ;
VAL_ 64 AB_Gurtwarn_VB 0 "keine_Warnung" 1 "Gurtwarnung_ausloesen" ;
VAL_ 64 AB_Anzeige_Fussg 0 "keine_FSG_Aktion_ausgeloest" 1 "Motorhaube_offen" 2 "Systemfehler" ;
VAL_ 64 AB_Texte_AKS 0 "keine_AKS_Ausloesung" 1 "AKS_ausgeloest" 2 "AKS_Systemfehler" ;
VAL_ 64 AB_MKB_gueltig 0 "Multikollisionsbremsung_nicht_freigeschaltet" 1 "Multikollisionsbremsung_freigeschaltet" ;
VAL_ 64 AB_MKB_Anforderung 0 "Multikollisionsbremsung_nicht_angefordert" 1 "Multikollisionsbremsung_angefordert" ;
VAL_ 64 AB_Versorgungsspannung 0 "plausibel" 1 "unplausibel" ;
VAL_ 64 AB_Deaktivierung_HV 0 "keine_Deaktivierung" 1 "Deaktivierung_1" 2 "Deaktivierung_2" 3 "Deaktivierung_3" 4 "Deaktivierung_4" 5 "Deaktivierung_5" 6 "Deaktivierung_6" 7 "Fehler" ;
VAL_ 64 AB_EDR_Trigger 0 "No_Event" 1 "Start_Event" 2 "NonDeployment_Event" 3 "Deployment_Event" ;
VAL_ 64 SC_LowSpeedCrashErkannt 0 "kein_Crash_erkannt" 1 "Crash_Frontbereich_erkannt" 2 "Crash_Heckbereich_erkannt" 3 "Crash_Front_und_Heckbereich_erkannt" ;
VAL_ 64 SC_Masterzeit 127 "Init" ;
VAL_ 1312 LoGeWa_Event_Kombiwarnung 0 "Init" 1 "Unfall" 2 "Traktionsverlust" 3 "Panne" 4 "Sichtbehinderung" 5 "Stauende" 6 "Aktiver_Eingriff_PreSense" 7 "Aktiver_Eingriff_ANB" 8 "Aktiver_Eingriff_Emergency_Brake" ;
VAL_ 1312 AB_Anprall_Seite_Beifahrer 0 "kein_Anprall" 1 "Anprall_erkannt" ;
VAL_ 1312 AB_Anprall_Rollover 0 "kein_Anprall" 1 "Anprall_erkannt" ;
VAL_ 1312 AB_Anprall_FGS 0 "kein_Anprall" 1 "Anprall_erkannt" ;
VAL_ 1312 AB_Anprall_Front_Beifahrer 0 "kein_Anprall" 1 "Anprall_erkannt" ;
VAL_ 1312 AB_Anprall_Front_Fahrer 0 "kein_Anprall" 1 "Anprall_erkannt" ;
VAL_ 1312 AB_Anprall_Heck_Beifahrer 0 "kein_Anprall" 1 "Anprall_erkannt" ;
VAL_ 1312 AB_Anprall_Heck_Fahrer 0 "kein_Anprall" 1 "Anprall_erkannt" ;
VAL_ 1312 AB_Wickelklappung_Reihe2_MI 0 "nicht_verbaut" 1 "nicht_verfügbar (Fehler oder Init)" 2 "nicht_verriegelt" 3 "verriegelt" ;
VAL_ 1312 AB_Belegung_VB 0 "nicht_verfuegbar" 1 "Fehler" 2 "nicht_belegt" 3 "belegt" ;
VAL_ 1312 AB_Abschaltanf_SIH_BF 0 "Normalbetrieb" 1 "Abschaltung_angefordert" ;
VAL_ 1312 AB_Anprall_Seite_Fahrer 0 "kein_Anprall" 1 "Anprall_erkannt" ;
VAL_ 1312 SC_PAO_Schriftzug_Anf 0 "LED aus" 1 "LED an" 2 "LED blinken" 3 "reserviert" ;
VAL_ 1312 SC_PAO_ON_Anf 0 "LED aus" 1 "LED an" 2 "LED blinken" 3 "reserviert" ;
VAL_ 1312 SC_PAO_OFF_Anf 0 "LED aus" 1 "LED an" 2 "LED blinken" 3 "reserviert" ;
VAL_ 1312 AB_Crashschwere 0 "kein_Ereignis" 1 "Crashschwere_1" 2 "Crashschwere_2" 3 "Crashschwere_3" 4 "Crashschwere_4" 5 "Crashschwere_5" 6 "nicht_belegt" 7 "Fehler" ;
VAL_ 1312 AB_Anforderung_USM 0 "keine_Anforderung" 1 "Anforderung" ;
VAL_ 1312 AB_Gurtschloss_FA 0 "nicht_verbaut" 1 "nicht_verfügbar (Fehler oder Init)" 2 "nicht_gesteckt" 3 "gesteckt" ;
VAL_ 1312 AB_Gurtschloss_BF 0 "nicht_verbaut" 1 "nicht_verfügbar (Fehler oder Init)" 2 "nicht_gesteckt" 3 "gesteckt" ;
VAL_ 1312 AB_Gurtschloss_Reihe2_FA 0 "nicht_verbaut" 1 "nicht_verfügbar (Fehler oder Init)" 2 "nicht_gesteckt" 3 "gesteckt" ;
VAL_ 1312 AB_Gurtschloss_Reihe2_MI 0 "nicht_verbaut" 1 "nicht_verfügbar (Fehler oder Init)" 2 "nicht_gesteckt" 3 "gesteckt" ;
VAL_ 1312 AB_Gurtschloss_Reihe2_BF 0 "nicht_verbaut" 1 "nicht_verfügbar (Fehler oder Init)" 2 "nicht_gesteckt" 3 "gesteckt" ;
VAL_ 1312 AB_Gurtschloss_Reihe3_FA 0 "nicht_verbaut" 1 "nicht_verfügbar (Fehler oder Init)" 2 "nicht_gesteckt" 3 "gesteckt" ;
VAL_ 1312 AB_Gurtschloss_Reihe3_MI 0 "nicht_verbaut" 1 "nicht_verfügbar (Fehler oder Init)" 2 "nicht_gesteckt" 3 "gesteckt" ;
VAL_ 1312 AB_Gurtschloss_Reihe3_BF 0 "nicht_verbaut" 1 "nicht_verfügbar (Fehler oder Init)" 2 "nicht_gesteckt" 3 "gesteckt" ;
VAL_ 1312 AB_Sitzpos_Sens_FA 0 "nicht verfügbar" 1 "Fehler" 2 "Sitz nicht vorne" 3 "Sitz vorne" ;
VAL_ 1312 AB_Sitzpos_Sens_BF 0 "nicht verfügbar" 1 "Fehler" 2 "Sitz nicht vorne" 3 "Sitz vorne" ;
VAL_ 1312 AB_Wickelklappung_Reihe2_BF 0 "nicht_verbaut" 1 "nicht_verfügbar (Fehler oder Init)" 2 "nicht_verriegelt" 3 "verriegelt" ;
VAL_ 1312 AB_Wickelklappung_Reihe2_FA 0 "nicht_verbaut" 1 "nicht_verfügbar (Fehler oder Init)" 2 "nicht_verriegelt" 3 "verriegelt" ;
VAL_ 1633 AAG_AVS_Fehler_02_inv 0 "Fehler" 1 "kein_Fehler" ;
VAL_ 1633 AAG_Bremsl_durch_ECD 0 "Bremslicht_ist_aus" 1 "Bremslicht_durch_ECD_aktiv" ;
VAL_ 1633 AAG_Anhaenger_abgesteckt 1 "Anhaenger_wurde_bei_KL15_aus_abgesteckt" ;
VAL_ 1633 AAG_NSL_aktiv 1 "Anhaenger_Nebelschusslicht_aktiv" ;
VAL_ 1633 AAG_Anhaenger_erkannt 0 "kein_Anhaenger_erkannt" 1 "AAG_Anhaenger_erkannt" ;
VAL_ 1633 AAG_Blinker_H_aktiv 1 "Anhaenger_Blinker_aktiv" ;
VAL_ 1633 AAG_Blinker_HL_def 1 "Anhaenger_Blinker_links_defekt" ;
VAL_ 1633 AAG_Blinker_HR_def 1 "Anhaenger_Blinker_rechts_defekt" ;
VAL_ 1633 AAG_Bremslicht_H_def 1 "Anhaenger_Bremslicht_defekt" ;
VAL_ 1633 AAG_Schlusslicht_HL_def 1 "Anhaenger_Schlusslicht_links_defekt" ;
VAL_ 1633 AAG_Schlusslicht_HR_def 1 "Anhaenger_Schlusslicht_rechts_defekt" ;
VAL_ 1633 AAG_Bremslicht_Reku 0 "inaktiv" 1 "aktiv" ;
VAL_ 1633 AAG_AVS_Fehler_02 0 "kein_Fehler" 1 "Fehler" ;
VAL_ 1633 AAG_AVS_Stati 0 "endlage eingefahren erreicht" 1 "endlage ausgefahren erreicht" 2 "ausfahren automatik " 3 "einfahren automatik" 4 "ausfahren manuell " 5 "einfahren manuell" 6 "zwischenposition" 7 "nicht initialisiert" ;
VAL_ 927 US_Fehler_VS 0 "kein_Fehler" 1 "Fehler" ;
VAL_ 927 US_Fehler_HS 0 "kein_Fehler" 1 "Fehler" ;
VAL_ 927 US_Verschmutzung_VS 0 "keine_Blindheit" 1 "Blindheit_erkannt" ;
VAL_ 927 US_Verschmutzung_HS 0 "keine_Blindheit" 1 "Blindheit_erkannt" ;
VAL_ 927 US_NichtVerfuegbarkeit_VS 0 "Abstandswert_verfuegbar" 1 "Abstandswert_nicht_verfuegbar" ;
VAL_ 927 US_NichtVerfuegbarkeit_HS 0 "Abstandswert_verfuegbar" 1 "Abstandswert_nicht_verfuegbar" ;
VAL_ 896 US_Sende_Modus 0 "keine_fuer_das_ACC_SG_relevanten_Abstandswerte_werden_gesendet" 1 "4K_ext_range__10_Signalwege_verfuegbar__4m" 2 "4K_norm_range__10_Signalwege_verfuegbar__2m" 3 "6K_ext_range__16_Signalwege_verfuegbar__4m" 4 "6K_norm_range__16_Signalwege_verfuegbar__2m" 5 "2K_ext_range__2_Signalwege_verfuegbar__4m" 6 "Modeumschaltung__ext_>_norm__oder__norm_>_ext" 7 "Blindheitspruefung" 8 "4K_ext_range__12_Signalwege_verfuegbar_4m" 9 "4K_norm_range__12_Signalwege_verfuegbar_2m" 10 "6K_ext_range__18_Signalwege_verfuegbar_4m" 11 "6K_norm_range__18_Signalwege_verfuegbar_2m" 15 "Fehler" ;
VAL_ 896 US_relevanter_Fehler 0 "kein_relevanter_Fehler" 1 "relevanter_Fehler" ;
VAL_ 896 US_relevante_Nichtverfuegbarkeit 0 "verfuegbar" 1 "nicht_verfuegbar" ;
VAL_ 896 US_Freisicht_nio 0 "Freisicht_iO" 1 "Freisicht_niO" ;
VAL_ 896 US_blindness_detected 0 "blindness_nicht_detektiert" 1 "blindness_detektiert" ;
VAL_ 896 US_Sende_Modus_hinten 0 "keine_fuer_das_ACC_SG_relevanten_Abstandswerte_werden_gesendet" 5 "2K_ext_range__2_Signalwege_verfuegbar__4m" 6 "Modeumschaltung__ext_>_norm__oder__norm_>_ext" 7 "Blindheitspruefung" 15 "Fehler" ;
VAL_ 2527679497 ARA_Status_ARA_HAL 0 "reserviert" 1 "reserviert" 2 "reserviert" 3 "reserviert" 4 "ARA_HAL_aktivierbar" 6 "ARA_HAL_Lenkwinkel_aktiv" 7 "reserviert" 8 "ARA_HAL_funktionsbereit" 9 "ARA_HAL_Neustart" 10 "ARA_HAL_Abbruch" 11 "reserviert" 12 "reserviert" 13 "reserviert" 14 "reserviert" 15 "reserviert" ;
VAL_ 2527679497 ARA_HAL_Radwinkel_Soll 1020 "inaktiv" 1021 "Reserviert" 1022 "Reserviert" 1023 "Reserviert" ;
VAL_ 2527679497 ARA_HAL_VZ_Radwinkel_Soll 0 "positiv_Lenkeinschlag_links" 1 "negativ_Lenkeinschlag_rechts" ;
VAL_ 2527679497 ARA_Status_ARA_EPS 0 "reserviert" 1 "reserviert" 2 "reserviert" 4 "ARA_EPS_aktivierbar" 5 "reserviert" 6 "ARA_EPS_Lenkwinkel_aktiv" 7 "reserviert" 8 "ARA_EPS_funktionsbereit" 9 "ARA_EPS_Neustart" 10 "ARA_EPS_Abbruch" 11 "reserviert" 12 "reserviert" 13 "reserviert" 14 "reserviert" 15 "reserviert" ;
VAL_ 2527679497 ARA_VZ_Zahnstangen_Pos_Soll 0 "positiv" 1 "negativ" ;
VAL_ 2527679497 ARA_Zahnstangen_Pos_Soll 4094 "Inaktiv" ;
VAL_ 2527679497 ARA_01_Signal_red_cyclic 0 "Langsame_Zykluszeit_aktiv" 1 "Schnelle_Zykluszeit_aktiv" ;
VAL_ 677 ARA_02_Signal_red_cyclic 0 "Langsame_Zykluszeit_aktiv" 1 "Schnelle_Zykluszeit_aktiv" ;
VAL_ 677 ARA_Bremsverzoegerung 126 "Init" 127 "Fehler" ;
VAL_ 677 ARA_Anf_Bremsverzoegerung 0 "keine Bremsanforderung" 1 "Bremsanforderung" ;
VAL_ 677 ARA_maximale_Beschleunigung 122 "Init" 127 "Fehler" ;
VAL_ 677 ARA_Anhalten 0 "keine_Anhalten_gewuenscht" 1 "Anhalten_gewuenscht" ;
VAL_ 677 ARA_Anhaltweg 2046 "Neutralwert" 2047 "Fehler" ;
VAL_ 677 ARA_Anforderung_HMS 0 "keine_Anforderung" 1 "halten" 2 "parken" 3 "halten_Standby" 4 "anfahren" 5 "Loesen_ueber_Rampe" ;
VAL_ 677 ARA_Parken_beibehalten_HMS 0 "Parken_nicht_beibehalten" 1 "Parken_beibehalten" 2 "Init" 3 "Fehler" ;
VAL_ 677 ARA_maximale_Geschwindigkeit 251 "Init" 255 "Fehler" ;
VAL_ 344 ARA_Sensor_Knickwgeschw 4094 "Init" 4095 "Fehler" ;
VAL_ 344 ARA_Sensor_Knickw_Rohwert 65534 "Init" 65535 "Fehler" ;
VAL_ 344 ARA_Sensor_Signal_red_cyclic 0 "Langsame_Zykluszeit_aktiv" 1 "Schnelle_Zykluszeit_aktiv" ;
VAL_ 344 ARA_Sensor_Knickwgeschw_upd 0 "nicht_aktuell" 1 "aktuell" ;
VAL_ 344 ARA_Sensor_Knickw_Rohwert_upd 0 "nicht_aktuell" 1 "aktuell" ;
VAL_ 345 ARA_Knickwinkel_konfidenz 126 "Init" 127 "Fehler" ;
VAL_ 345 ARA_Texte 0 "kein Text/Akustik" 63 "Fehler" ;
VAL_ 345 ARA_Modus 0 "Knickwinkelmodus" 1 "Trajektorienmodus" ;
VAL_ 345 ARA_Aktiver_Grafikmodus 0 "keine Grafik" 1 "Grafikmodus aktiv" ;
VAL_ 345 ARA_Deaktivierung_sperren 0 "nicht_gesperrt" 1 "gesperrt" ;
VAL_ 345 ARA_Modus_Anf 0 "ARA Modus nicht im TSG angefordert" 1 "ARA Modus im TSG angefordert" ;
VAL_ 345 ARA_Bremsfuss 0 "kein Bremsfuss" 1 "Bremsfuss angefordert" ;
VAL_ 345 ARA_Sensor_Aktivierung 0 "Knickwinkelsensor deaktivieren" 1 "Knickwinkelsensor aktivieren" ;
VAL_ 345 ARA_Knickwinkel_Komfort 62 "Init" 63 "Fehler" ;
VAL_ 345 ARA_Status 0 "ARA_Status_inaktiv" 1 "ARA_Status_init" 2 "Fehler" 3 "ARA_Status_Start" 4 " ARA_Status_aktiv " 6 "ARA_Status_Regelung_aktiv" 8 "ARA_Status_betriebsbereit" 9 "ARA_Status_Klemmtraeger_erkannt" 10 "ARA_Status_Abbruch" 11 "ARA_Status_nicht_betriebsbereit" ;
VAL_ 345 ARA_Knickwinkel_Max 126 "Init" 127 "Fehler" ;
VAL_ 345 ARA_Knickwinkel_Soll 254 "Init" 255 "Fehler" ;
VAL_ 345 ARA_Knickwinkel_Ist 254 "Init" 255 "Fehler" ;
VAL_ 1365 AV_HEK_Status_Kamera_H 0 "betriebsbereit" 1 "passiv" 2 "verschmutzt" 7 "Fehler" ;
VAL_ 1365 AV_HEK_Status_Kamera_V 0 "betriebsbereit" 1 "passiv" 2 "verschmutzt" 7 "Fehler" ;
VAL_ 1365 AV_HEK_Status_Kamera_L 0 "betriebsbereit" 1 "passiv" 2 "verschmutzt" 7 "Fehler" ;
VAL_ 1365 AV_HEK_Status_Kamera_R 0 "betriebsbereit" 1 "passiv" 2 "verschmutzt" 7 "Fehler" ;
VAL_ 1365 AV_HEK_Status_aktiv 0 "inaktiv" 1 "aktiv" ;
VAL_ 1365 AV_Umfeldbeleuchtung_Anf 0 "nicht_angefordert" 1 "angefordert" ;
VAL_ 1365 AV_Charisma_FahrPr 0 "keine_Funktion" 1 "Programm_1" 2 "Programm_2" 3 "Programm_3" 4 "Programm_4" 5 "Programm_5" 6 "Programm_6" 7 "Programm_7" 8 "Programm_8" 9 "Programm_9" 10 "Programm_10" 11 "Programm_11" 12 "Programm_12" 13 "Programm_13" 14 "Programm_14" 15 "Programm_15" ;
VAL_ 1365 AV_Charisma_Status 0 "Init" 1 "verfuegbar" 2 "nicht_verfuegbar" 3 "asynchron_durch_Fahrerwunsch" ;
